VERSION ""

NS_ :

BS_:

BU_: IVI

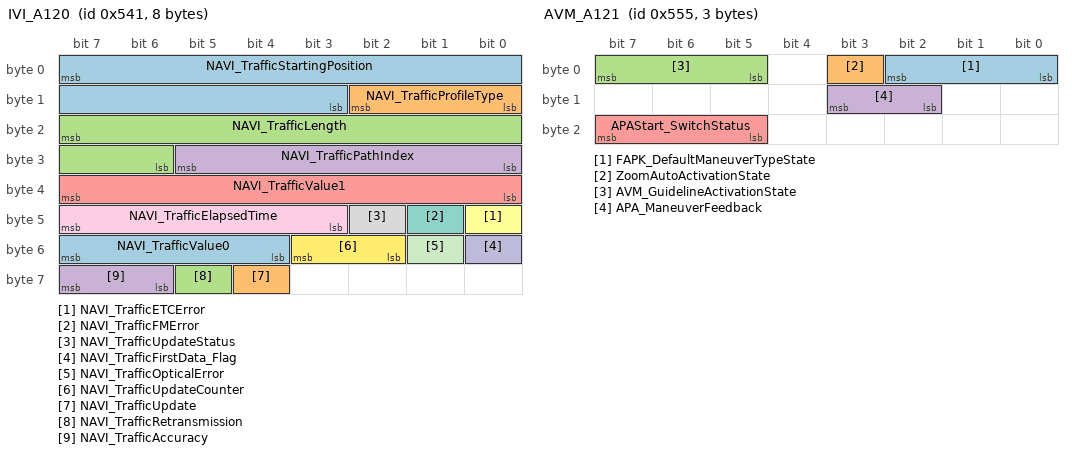
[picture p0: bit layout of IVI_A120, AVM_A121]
BO_ 1345 IVI_A120: 8 IVI
  SG_ NAVI_TrafficStartingPosition : 7|13@0+ (1,0) [0|8190] "m" Vector__XXX
  SG_ NAVI_TrafficProfileType : 10|3@0+ (1,0) [0|0] "" Vector__XXX
  SG_ NAVI_TrafficLength : 23|10@0+ (10,0) [0|7000] "m" Vector__XXX
  SG_ NAVI_TrafficPathIndex : 29|6@0+ (1,1) [1|63] "-" Vector__XXX
  SG_ NAVI_TrafficValue1 : 39|8@0+ (1,0) [0|255] "-" Vector__XXX
  SG_ NAVI_TrafficETCError : 40|1@0+ (1,0) [0|0] "" Vector__XXX
  SG_ NAVI_TrafficFMError : 41|1@0+ (1,0) [0|0] "" Vector__XXX
  SG_ NAVI_TrafficUpdateStatus : 42|1@0+ (1,0) [0|0] "" Vector__XXX
  SG_ NAVI_TrafficElapsedTime : 47|5@0+ (10,0) [0|300] "min" Vector__XXX
  SG_ NAVI_TrafficFirstData_Flag : 48|1@0+ (1,0) [0|0] "" Vector__XXX
  SG_ NAVI_TrafficOpticalError : 49|1@0+ (1,0) [0|0] "" Vector__XXX
  SG_ NAVI_TrafficUpdateCounter : 51|2@0+ (1,0) [0|3] "-" Vector__XXX
  SG_ NAVI_TrafficValue0 : 55|4@0+ (1,0) [0|0] "" Vector__XXX
  SG_ NAVI_TrafficUpdate : 60|1@0+ (1,0) [0|0] "" Vector__XXX
  SG_ NAVI_TrafficRetransmission : 61|1@0+ (1,0) [0|0] "" Vector__XXX
  SG_ NAVI_TrafficAccuracy : 63|2@0+ (1,0) [0|0] "" Vector__XXX

BO_ 1356 ADASISv2_A103: 8 IVI
  SG_ ADASISv2_POSITION : 7|64@0+ (1,0) [0|0] "" Vector__XXX

BO_ 1365 AVM_A121: 3 Vector__XXX
  SG_ FAPK_DefaultManeuverTypeState : 2|3@0+ (1,0) [0|0] "" IVI
  SG_ ZoomAutoActivationState : 3|1@0+ (1,0) [0|0] "" IVI
  SG_ AVM_GuidelineActivationState : 7|3@0+ (1,0) [0|0] "" IVI
  SG_ APA_ManeuverFeedback : 11|2@0+ (1,0) [0|0] "" IVI
  SG_ APAStart_SwitchStatus : 23|3@0+ (1,0) [0|0] "" IVI

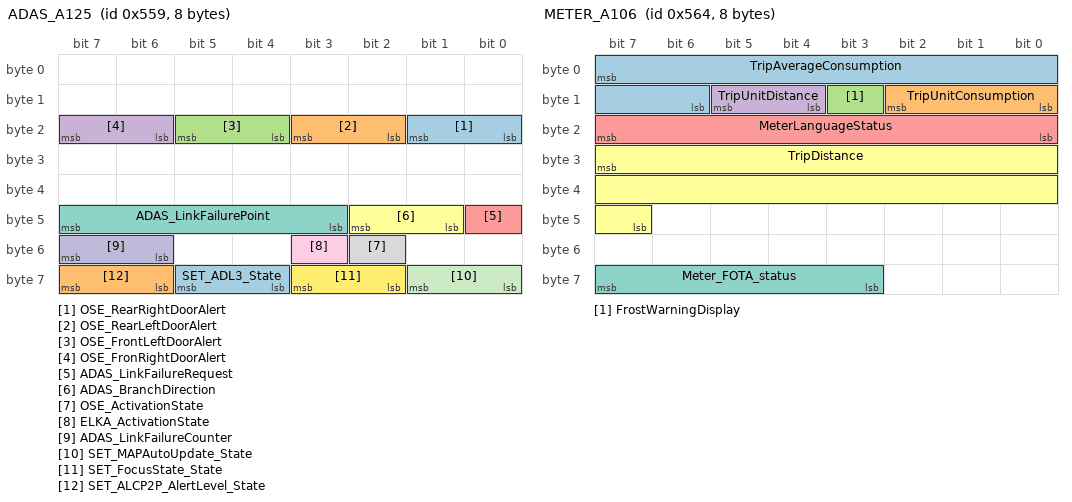
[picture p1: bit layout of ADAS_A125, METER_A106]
BO_ 1369 ADAS_A125: 8 Vector__XXX
  SG_ OSE_RearRightDoorAlert : 17|2@0+ (1,0) [0|0] "" IVI
  SG_ OSE_RearLeftDoorAlert : 19|2@0+ (1,0) [0|0] "" IVI
  SG_ OSE_FrontLeftDoorAlert : 21|2@0+ (1,0) [0|0] "" IVI
  SG_ OSE_FronRightDoorAlert : 23|2@0+ (1,0) [0|0] "" IVI
  SG_ ADAS_LinkFailureRequest : 40|1@0+ (1,0) [0|0] "" IVI
  SG_ ADAS_BranchDirection : 42|2@0+ (1,0) [0|0] "" IVI
  SG_ ADAS_LinkFailurePoint : 47|5@0+ (1,0) [0|30] "-" IVI
  SG_ OSE_ActivationState : 50|1@0+ (1,0) [0|0] "" IVI
  SG_ ELKA_ActivationState : 51|1@0+ (1,0) [0|0] "" IVI
  SG_ ADAS_LinkFailureCounter : 55|2@0+ (1,0) [0|3] "-" IVI
  SG_ SET_MAPAutoUpdate_State : 57|2@0+ (1,0) [0|0] "" IVI
  SG_ SET_FocusState_State : 59|2@0+ (1,0) [0|0] "" IVI
  SG_ SET_ADL3_State : 61|2@0+ (1,0) [0|0] "" IVI
  SG_ SET_ALCP2P_AlertLevel_State : 63|2@0+ (1,0) [0|0] "" IVI

BO_ 1380 METER_A106: 8 Vector__XXX
  SG_ TripAverageConsumption : 7|10@0+ (0.1,0) [0|102.3] "" IVI
  SG_ TripUnitConsumption : 10|3@0+ (1,0) [0|0] "" IVI
  SG_ FrostWarningDisplay : 11|1@0+ (1,0) [0|0] "" IVI
  SG_ TripUnitDistance : 13|2@0+ (1,0) [0|0] "" IVI
  SG_ MeterLanguageStatus : 23|8@0+ (1,0) [0|0] "" IVI
  SG_ TripDistance : 31|17@0+ (0.1,0) [0|13107.1] "" IVI
  SG_ Meter_FOTA_status : 63|5@0+ (1,0) [0|0] "" IVI

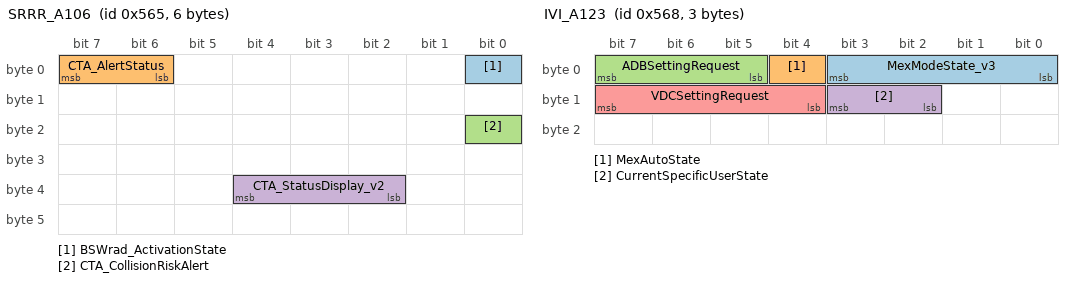
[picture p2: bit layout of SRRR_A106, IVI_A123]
BO_ 1381 SRRR_A106: 6 Vector__XXX
  SG_ BSWrad_ActivationState : 0|1@0+ (1,0) [0|0] "" IVI
  SG_ CTA_AlertStatus : 7|2@0+ (1,0) [0|0] "" IVI
  SG_ CTA_CollisionRiskAlert : 16|1@0+ (1,0) [0|0] "" IVI
  SG_ CTA_StatusDisplay_v2 : 36|3@0+ (1,0) [0|0] "" IVI

BO_ 1384 IVI_A123: 3 IVI
  SG_ MexModeState_v3 : 3|4@0+ (1,0) [0|0] "" Vector__XXX
  SG_ MexAutoState : 4|1@0+ (1,0) [0|0] "" Vector__XXX
  SG_ ADBSettingRequest : 7|3@0+ (1,0) [0|0] "" Vector__XXX
  SG_ CurrentSpecificUserState : 11|2@0+ (1,0) [0|0] "" Vector__XXX
  SG_ VDCSettingRequest : 15|4@0+ (1,0) [0|0] "" Vector__XXX

BO_ 1386 HVAC_A101: 5 Vector__XXX
  SG_ ClimCabinParticleConcDisplay : 15|10@0+ (5,0) [0|4095] "µg/m3" IVI
  SG_ ClimExternParticleConcDisplay : 21|10@0+ (5,0) [0|4095] "µg/m3" IVI

BO_ 1392 IVI_A119: 8 IVI
  SG_ HUD_ADASactivationRequest2 : 1|2@0+ (1,0) [0|0] "" Vector__XXX
  SG_ VSPsoundChoiceActivationRequest2 : 4|3@0+ (1,0) [0|0] "" Vector__XXX
  SG_ FAPK_DefaultManeuverTypeRequest2 : 7|3@0+ (1,0) [0|0] "" Vector__XXX
  SG_ AmbientLightingColor_v3 : 8|7@0+ (1,0) [0|0] "" Vector__XXX
  SG_ FOTA_ReadyToSleep_IVI : 9|1@0+ (1,0) [0|0] "" Vector__XXX
  SG_ VSPSoundActivationRequest2 : 11|2@0+ (1,0) [0|0] "" Vector__XXX
  SG_ HUD_TurnByTurnActivationRequest2 : 13|2@0+ (1,0) [0|0] "" Vector__XXX
  SG_ HUD_TSRactivationRequest2 : 15|2@0+ (1,0) [0|0] "" Vector__XXX
  SG_ SET_Acceleration_Request2 : 17|3@0+ (1,0) [0|0] "" Vector__XXX
  SG_ SET_NavigatDriveAssist_Request2 : 25|2@0+ (1,0) [0|0] "" Vector__XXX
  SG_ SET_ALCActivationByTSIG_Request2 : 27|2@0+ (1,0) [0|0] "" Vector__XXX
  SG_ SET_Deceleration_Request2 : 30|3@0+ (1,0) [0|0] "" Vector__XXX
  SG_ SET_OvertakingAssist_Request2 : 33|2@0+ (1,0) [0|0] "" Vector__XXX
  SG_ SET_LaneChangeSwiftness_Request2 : 36|3@0+ (1,0) [0|0] "" Vector__XXX
  SG_ SET_CornerSpeedLevel_Request2 : 39|3@0+ (1,0) [0|0] "" Vector__XXX
  SG_ SET_VoiceGuidance_Request2 : 41|2@0+ (1,0) [0|0] "" Vector__XXX
  SG_ SET_PositionInLane_Request2 : 44|3@0+ (1,0) [0|0] "" Vector__XXX
  SG_ SET_OvertakeRelatSpeed_Request2 : 47|3@0+ (1,0) [0|0] "" Vector__XXX
  SG_ IVI_SafeModeAck : 48|1@0+ (1,0) [0|0] "" Vector__XXX
  SG_ WDA_ActivationRequest2 : 50|2@0+ (1,0) [0|0] "" Vector__XXX
  SG_ RAB_ActivationRequest2 : 52|2@0+ (1,0) [0|0] "" Vector__XXX
  SG_ RST_PedalMappingRequest : 55|3@0+ (1,0) [0|0] "" Vector__XXX
  SG_ VirtualKeySuspendReq2 : 57|2@0+ (1,0) [0|0] "" Vector__XXX
  SG_ SET_MAPAutoUpdate_Request2 : 59|2@0+ (1,0) [0|0] "" Vector__XXX
  SG_ SET_FocusState_Request2 : 61|2@0+ (1,0) [0|0] "" Vector__XXX
  SG_ SET_ADL3_Request2 : 63|2@0+ (1,0) [0|0] "" Vector__XXX

BO_ 1394 ADASIS_CASP_A101: 8 IVI
  SG_ E_Hor_MedRange_CartoData : 4|61@0+ (1,0) [0|0] "" Vector__XXX
  SG_ E_Hor_MedRange_DataType : 7|3@0+ (1,0) [0|0] "" Vector__XXX

BO_ 1398 HEVC_A155: 3 Vector__XXX
  SG_ ChargingStationComType : 11|3@0+ (1,0) [0|0] "" IVI
  SG_ V2G_ServiceActivationState : 23|3@0+ (1,0) [0|0] "" IVI

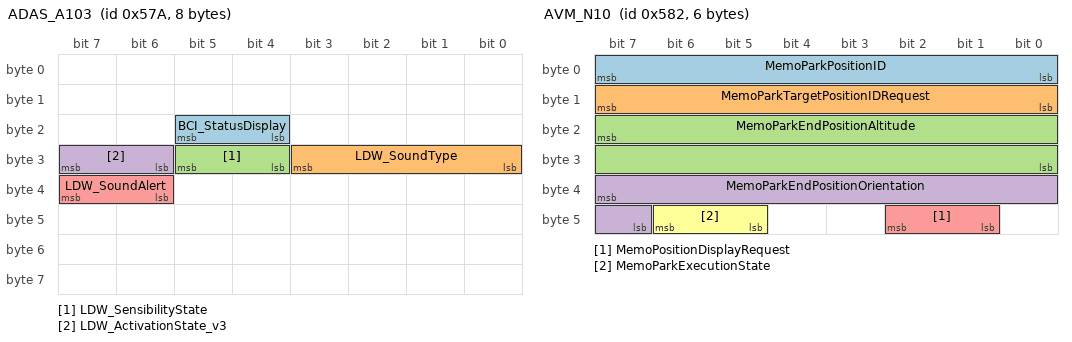
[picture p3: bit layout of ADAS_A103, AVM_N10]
BO_ 1402 ADAS_A103: 8 Vector__XXX
  SG_ BCI_StatusDisplay : 21|2@0+ (1,0) [0|0] "" IVI
  SG_ LDW_SoundType : 27|4@0+ (1,0) [0|0] "" IVI
  SG_ LDW_SensibilityState : 29|2@0+ (1,0) [0|0] "" IVI
  SG_ LDW_ActivationState_v3 : 31|2@0+ (1,0) [0|0] "" IVI
  SG_ LDW_SoundAlert : 39|2@0+ (1,0) [0|0] "" IVI

BO_ 1410 AVM_N10: 6 Vector__XXX
  SG_ MemoParkPositionID : 7|8@0+ (1,0) [0|250] "" IVI
  SG_ MemoParkTargetPositionIDRequest : 15|8@0+ (1,0) [0|250] "" IVI
  SG_ MemoParkEndPositionAltitude : 23|16@0+ (0.1,-500) [-500|3000] "m" IVI
  SG_ MemoParkEndPositionOrientation : 39|9@0+ (1,-180) [-180|179] "°" IVI
  SG_ MemoPositionDisplayRequest : 42|2@0+ (1,0) [0|0] "" IVI
  SG_ MemoParkExecutionState : 46|2@0+ (1,0) [0|0] "" IVI

BO_ 1412 HVAC_A108: 3 Vector__XXX
  SG_ HVAC_ClimShortcutPush : 5|1@0+ (1,0) [0|0] "" IVI

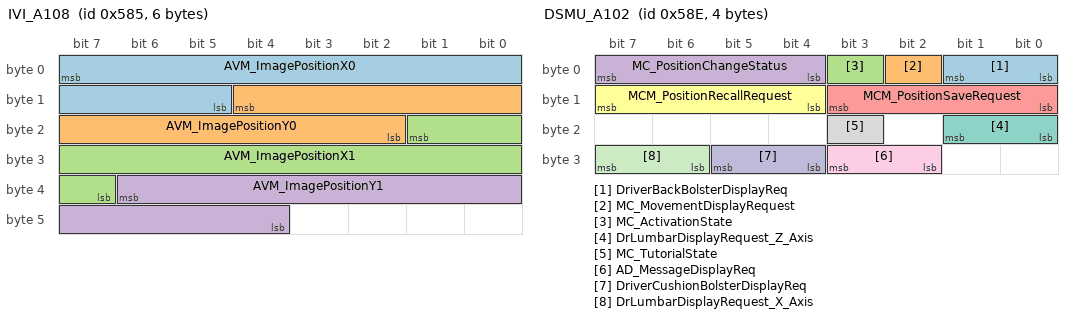
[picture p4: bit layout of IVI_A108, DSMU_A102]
BO_ 1413 IVI_A108: 6 IVI
  SG_ AVM_ImagePositionX0 : 7|11@0+ (1,0) [0|2045] "pixel" Vector__XXX
  SG_ AVM_ImagePositionY0 : 12|11@0+ (1,0) [0|2045] "pixel" Vector__XXX
  SG_ AVM_ImagePositionX1 : 17|11@0+ (1,0) [0|2045] "pixel" Vector__XXX
  SG_ AVM_ImagePositionY1 : 38|11@0+ (1,0) [0|2045] "pixel" Vector__XXX

BO_ 1415 IVI_R101: 1 IVI
  SG_ FAPK_SelectedManeuverTypeRequest : 6|3@0+ (1,0) [0|0] "" Vector__XXX

BO_ 1422 DSMU_A102: 4 Vector__XXX
  SG_ DriverBackBolsterDisplayReq : 1|2@0+ (1,0) [0|0] "" IVI
  SG_ MC_MovementDisplayRequest : 2|1@0+ (1,0) [0|0] "" IVI
  SG_ MC_ActivationState : 3|1@0+ (1,0) [0|0] "" IVI
  SG_ MC_PositionChangeStatus : 7|4@0+ (1,0) [0|0] "" IVI
  SG_ MCM_PositionSaveRequest : 11|4@0+ (1,0) [0|0] "" IVI
  SG_ MCM_PositionRecallRequest : 15|4@0+ (1,0) [0|0] "" IVI
  SG_ DrLumbarDisplayRequest_Z_Axis : 17|2@0+ (1,0) [0|0] "" IVI
  SG_ MC_TutorialState : 19|1@0+ (1,0) [0|0] "" IVI
  SG_ AD_MessageDisplayReq : 27|2@0+ (1,0) [0|0] "" IVI
  SG_ DriverCushionBolsterDisplayReq : 29|2@0+ (1,0) [0|0] "" IVI
  SG_ DrLumbarDisplayRequest_X_Axis : 31|2@0+ (1,0) [0|0] "" IVI

BO_ 1424 AVM_N11: 8 Vector__XXX
  SG_ MemoParkEndPositionLongitude : 7|29@0+ (0.00010,-18000) [-18000.0000|17959.9999] "min" IVI
  SG_ MemoParkEndPositionLatitude : 26|28@0+ (0.00010,-9000) [-9000.0000|8959.9999] "min" IVI

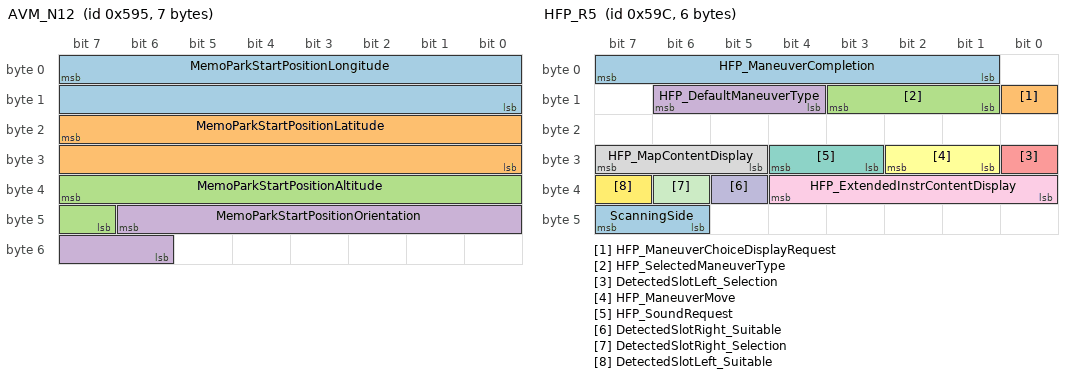
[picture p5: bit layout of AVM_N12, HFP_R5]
BO_ 1429 AVM_N12: 7 Vector__XXX
  SG_ MemoParkStartPositionLongitude : 7|16@0+ (0.00010,-0.2) [-0.2|0.2] "min" IVI
  SG_ MemoParkStartPositionLatitude : 23|16@0+ (0.00010,-0.2) [-0.2|0.2] "min" IVI
  SG_ MemoParkStartPositionAltitude : 39|9@0+ (0.1,-25.5) [-25.5|25.5] "m" IVI
  SG_ MemoParkStartPositionOrientation : 46|9@0+ (1,-180) [-180|179] "°" IVI

BO_ 1436 HFP_R5: 6 Vector__XXX
  SG_ HFP_ManeuverCompletion : 7|7@0+ (1,0) [0|100] "%" IVI
  SG_ HFP_ManeuverChoiceDisplayRequest : 8|1@0+ (1,0) [0|0] "" IVI
  SG_ HFP_SelectedManeuverType : 11|3@0+ (1,0) [0|0] "" IVI
  SG_ HFP_DefaultManeuverType : 14|3@0+ (1,0) [0|0] "" IVI
  SG_ DetectedSlotLeft_Selection : 24|1@0+ (1,0) [0|0] "" IVI
  SG_ HFP_ManeuverMove : 26|2@0+ (1,0) [0|0] "" IVI
  SG_ HFP_SoundRequest : 28|2@0+ (1,0) [0|0] "" IVI
  SG_ HFP_MapContentDisplay : 31|3@0+ (1,0) [0|0] "" IVI
  SG_ HFP_ExtendedInstrContentDisplay : 36|5@0+ (1,0) [0|0] "" IVI
  SG_ DetectedSlotRight_Suitable : 37|1@0+ (1,0) [0|0] "" IVI
  SG_ DetectedSlotRight_Selection : 38|1@0+ (1,0) [0|0] "" IVI
  SG_ DetectedSlotLeft_Suitable : 39|1@0+ (1,0) [0|0] "" IVI
  SG_ ScanningSide : 47|2@0+ (1,0) [0|0] "" IVI

BO_ 1439 HEVC_A133: 4 Vector__XXX
  SG_ InstantPowerZEVdisplay : 7|14@0+ (0.1,-500) [-500|500] "kW" IVI
  SG_ InstantConsumptionZEVdisplay_v3 : 23|11@0+ (0.1,-102.2) [-102.2|102.2] "" IVI

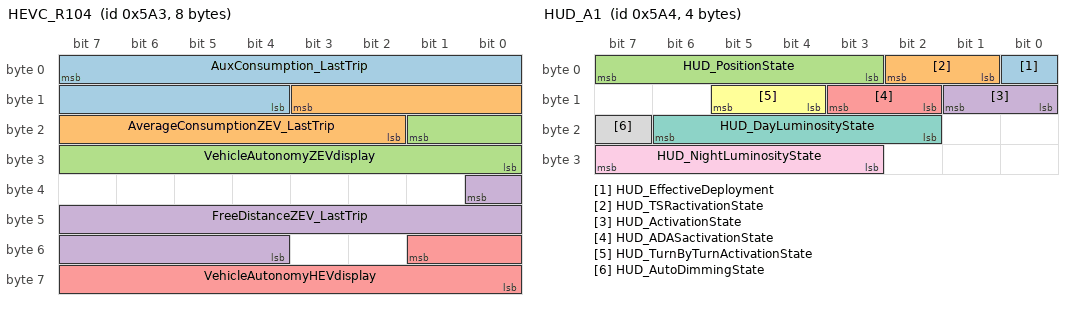
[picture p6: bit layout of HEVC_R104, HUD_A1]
BO_ 1443 HEVC_R104: 8 Vector__XXX
  SG_ AuxConsumption_LastTrip : 7|12@0+ (0.1,0) [0|409.4] "kWh" IVI
  SG_ AverageConsumptionZEV_LastTrip : 11|10@0+ (0.1,0) [0|102.2] "" IVI
  SG_ VehicleAutonomyZEVdisplay : 17|10@0+ (1,0) [0|1022] "km" IVI
  SG_ FreeDistanceZEV_LastTrip : 32|13@0+ (0.1,0) [0|819] "" IVI
  SG_ VehicleAutonomyHEVdisplay : 49|10@0+ (1,0) [0|1022] "" IVI

BO_ 1444 HUD_A1: 4 Vector__XXX
  SG_ HUD_EffectiveDeployment : 0|1@0+ (1,0) [0|0] "" IVI
  SG_ HUD_TSRactivationState : 2|2@0+ (1,0) [0|0] "" IVI
  SG_ HUD_PositionState : 7|5@0+ (1,0) [0|0] "" IVI
  SG_ HUD_ActivationState : 9|2@0+ (1,0) [0|0] "" IVI
  SG_ HUD_ADASactivationState : 11|2@0+ (1,0) [0|0] "" IVI
  SG_ HUD_TurnByTurnActivationState : 13|2@0+ (1,0) [0|0] "" IVI
  SG_ HUD_DayLuminosityState : 22|5@0+ (1,0) [0|0] "" IVI
  SG_ HUD_AutoDimmingState : 23|1@0+ (1,0) [0|0] "" IVI
  SG_ HUD_NightLuminosityState : 31|5@0+ (1,0) [0|0] "" IVI

BO_ 1446 SR_CANHS_R_02: 1 Vector__XXX
  SG_ StorageFormatStatus : 5|2@0+ (1,0) [0|0] "" IVI

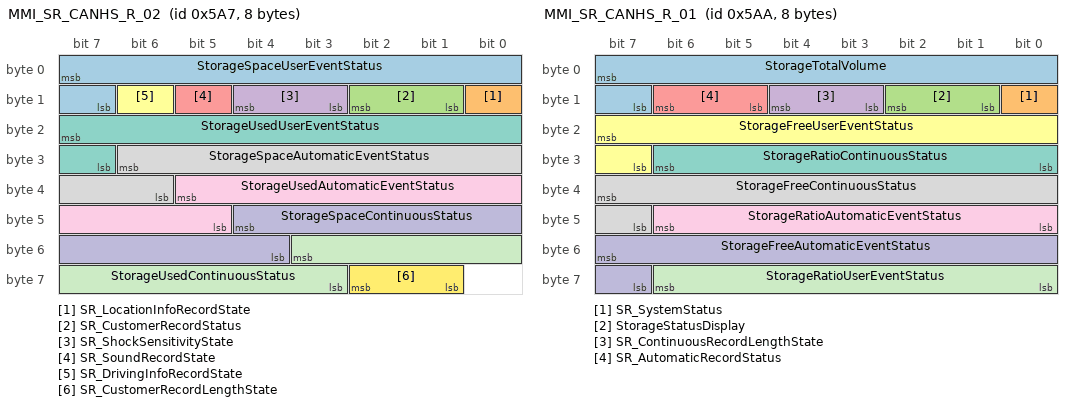
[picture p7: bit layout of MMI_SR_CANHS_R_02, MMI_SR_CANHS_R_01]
BO_ 1447 MMI_SR_CANHS_R_02: 8 Vector__XXX
  SG_ StorageSpaceUserEventStatus : 7|9@0+ (0.1,0) [0|32] "GB" IVI
  SG_ SR_LocationInfoRecordState : 8|1@0+ (1,0) [0|0] "" IVI
  SG_ SR_CustomerRecordStatus : 10|2@0+ (1,0) [0|0] "" IVI
  SG_ SR_ShockSensitivityState : 12|2@0+ (1,0) [0|0] "" IVI
  SG_ SR_SoundRecordState : 13|1@0+ (1,0) [0|0] "" IVI
  SG_ SR_DrivingInfoRecordState : 14|1@0+ (1,0) [0|0] "" IVI
  SG_ StorageUsedUserEventStatus : 23|9@0+ (0.1,0) [0|32] "GB" IVI
  SG_ StorageSpaceAutomaticEventStatus : 30|9@0+ (0.1,0) [0|32] "GB" IVI
  SG_ StorageUsedAutomaticEventStatus : 37|9@0+ (0.1,0) [0|32] "GB" IVI
  SG_ StorageSpaceContinuousStatus : 44|9@0+ (0.1,0) [0|32] "GB" IVI
  SG_ StorageUsedContinuousStatus : 51|9@0+ (0.1,0) [0|32] "GB" IVI
  SG_ SR_CustomerRecordLengthState : 58|2@0+ (1,0) [0|0] "" IVI

BO_ 1448 IVI_N20: 8 IVI
  SG_ ParkEndPositionLongitude : 7|29@0+ (0.00010,-18000) [-18000|17959.9999] "min" Vector__XXX
  SG_ ParkEndPositionLatitude : 26|28@0+ (0.00010,-9000) [-9000|8959.9999] "min" Vector__XXX

BO_ 1449 IVI_A109: 7 IVI
  SG_ ClimFrontDefrostPush : 0|1@0+ (1,0) [0|1] "-" Vector__XXX
  SG_ ClimRearDefrostPush : 1|1@0+ (1,0) [0|1] "-" Vector__XXX
  SG_ SecondRowLeftSeatAutoPush : 2|1@0+ (1,0) [0|1] "-" Vector__XXX
  SG_ SecondRowRightSeatAutoPush : 3|1@0+ (1,0) [0|1] "-" Vector__XXX
  SG_ ThirdRowLeftSeatAutoPush : 4|1@0+ (1,0) [0|1] "-" Vector__XXX
  SG_ ThirdRowRightSeatAutoPush : 5|1@0+ (1,0) [0|1] "-" Vector__XXX
  SG_ ClimHeatedSteeringWheelPush : 6|1@0+ (1,0) [0|1] "-" Vector__XXX
  SG_ ClimHeatedSteeringWheelAutoPush : 7|1@0+ (1,0) [0|1] "-" Vector__XXX
  SG_ ClimRearLeftTempRequest : 15|9@0+ (0.5,10) [10|127.5] "°" Vector__XXX
  SG_ ClimRearRightTempRequest : 22|9@0+ (0.5,10) [10|127.5] "°" Vector__XXX
  SG_ ClimRearRightFlowDistrVentPush : 24|1@0+ (1,0) [0|1] "" Vector__XXX
  SG_ ClimRearLeftFlowDistrVentPush : 25|1@0+ (1,0) [0|1] "" Vector__XXX
  SG_ ClimRearRightFlowDistrDefPush : 26|1@0+ (1,0) [0|1] "" Vector__XXX
  SG_ ClimRearLeftFlowDistrDefPush : 27|1@0+ (1,0) [0|1] "" Vector__XXX
  SG_ ClimRearRightSyncPush : 28|1@0+ (1,0) [0|1] "" Vector__XXX
  SG_ ClimRearLeftSyncPush : 29|1@0+ (1,0) [0|1] "" Vector__XXX
  SG_ ClimLinkPriorityHeatStrgAutoReq : 34|3@0+ (1,0) [0|0] "" Vector__XXX
  SG_ ClimRearRightAutoNormalPush : 35|1@0+ (1,0) [0|1] "" Vector__XXX
  SG_ ClimRearLeftAutoNormalPush : 36|1@0+ (1,0) [0|1] "" Vector__XXX
  SG_ ClimRearACPush : 37|1@0+ (1,0) [0|1] "" Vector__XXX
  SG_ ClimRearRightFlowDistrFeetPush : 38|1@0+ (1,0) [0|1] "" Vector__XXX
  SG_ ClimRearLeftFlowDistrFeetPush : 39|1@0+ (1,0) [0|1] "" Vector__XXX
  SG_ ClimFPrearLeftBlowingRequest : 43|4@0+ (1,0) [0|0] "" Vector__XXX
  SG_ ClimFPrearRightBlowingRequest : 47|4@0+ (1,0) [0|0] "" Vector__XXX
  SG_ ClimACmaxPush : 51|1@0+ (1,0) [0|1] "-" Vector__XXX
  SG_ VisionMexMode : 55|4@0+ (1,0) [0|0] "" Vector__XXX

BO_ 1450 MMI_SR_CANHS_R_01: 8 Vector__XXX
  SG_ StorageTotalVolume : 7|9@0+ (0.1,0) [0|32] "GB" IVI
  SG_ SR_SystemStatus : 8|1@0+ (1,0) [0|0] "" IVI
  SG_ StorageStatusDisplay : 10|2@0+ (1,0) [0|0] "" IVI
  SG_ SR_ContinuousRecordLengthState : 12|2@0+ (1,0) [0|0] "" IVI
  SG_ SR_AutomaticRecordStatus : 14|2@0+ (1,0) [0|0] "" IVI
  SG_ StorageFreeUserEventStatus : 23|9@0+ (0.1,0) [0|32] "GB" IVI
  SG_ StorageRatioContinuousStatus : 30|7@0+ (1,0) [0|100] "%" IVI
  SG_ StorageFreeContinuousStatus : 39|9@0+ (0.1,0) [0|32] "GB" IVI
  SG_ StorageRatioAutomaticEventStatus : 46|7@0+ (1,0) [0|100] "%" IVI
  SG_ StorageFreeAutomaticEventStatus : 55|9@0+ (0.1,0) [0|32] "GB" IVI
  SG_ StorageRatioUserEventStatus : 62|7@0+ (1,0) [0|100] "%" IVI

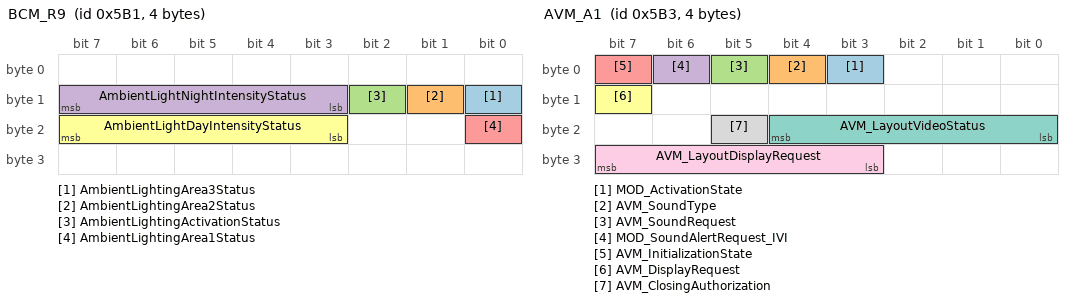
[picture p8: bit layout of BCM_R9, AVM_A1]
BO_ 1457 BCM_R9: 4 Vector__XXX
  SG_ AmbientLightingArea3Status : 8|1@0+ (1,0) [0|0] "" IVI
  SG_ AmbientLightingArea2Status : 9|1@0+ (1,0) [0|0] "" IVI
  SG_ AmbientLightingActivationStatus : 10|1@0+ (1,0) [0|0] "" IVI
  SG_ AmbientLightNightIntensityStatus : 15|5@0+ (5,0) [0|100] "%" IVI
  SG_ AmbientLightingArea1Status : 16|1@0+ (1,0) [0|0] "" IVI
  SG_ AmbientLightDayIntensityStatus : 23|5@0+ (5,0) [0|100] "%" IVI

BO_ 1458 HEVC_R112: 7 Vector__XXX
  SG_ PnCHEVCactivationStatus : 31|2@0+ (1,0) [0|0] "" IVI

BO_ 1459 AVM_A1: 4 Vector__XXX
  SG_ MOD_ActivationState : 3|1@0+ (1,0) [0|0] "" IVI
  SG_ AVM_SoundType : 4|1@0+ (1,0) [0|0] "" IVI
  SG_ AVM_SoundRequest : 5|1@0+ (1,0) [0|0] "" IVI
  SG_ MOD_SoundAlertRequest_IVI : 6|1@0+ (1,0) [0|0] "" IVI
  SG_ AVM_InitializationState : 7|1@0+ (1,0) [0|0] "" IVI
  SG_ AVM_DisplayRequest : 15|1@0+ (1,0) [0|0] "" IVI
  SG_ AVM_LayoutVideoStatus : 20|5@0+ (1,0) [0|0] "" IVI
  SG_ AVM_ClosingAuthorization : 21|1@0+ (1,0) [0|0] "" IVI
  SG_ AVM_LayoutDisplayRequest : 31|5@0+ (1,0) [0|0] "" IVI

BO_ 1462 HVAC_A105: 8 Vector__XXX
  SG_ ClimRearLeftTempDisplay : 7|9@0+ (0.5,0) [10|127.5] "°" IVI
  SG_ ClimFrontDefrostDisplayStatus : 8|1@0+ (1,0) [0|0] "" IVI
  SG_ ClimHeatedSteerWheelDispStatus : 9|1@0+ (1,0) [0|0] "" IVI
  SG_ ClimRearLeftTempDisplayStatus : 10|1@0+ (1,0) [0|0] "" IVI
  SG_ ClimHeatedSteerWheelAutoDisplay : 12|2@0+ (1,0) [0|0] "" IVI
  SG_ ClimFrontDefrostDisplay : 14|2@0+ (1,0) [0|0] "" IVI
  SG_ ClimRearRightTempDisplay : 23|9@0+ (0.5,0) [10|127.5] "°" IVI
  SG_ ClimRearRightSyncDisplayStatus : 24|1@0+ (1,0) [0|0] "" IVI
  SG_ ClimRearRightSyncDisplay : 26|2@0+ (1,0) [0|0] "" IVI
  SG_ ClimRearLeftSyncDisplayStatus : 27|1@0+ (1,0) [0|0] "" IVI
  SG_ ClimRearLeftSyncDisplay : 29|2@0+ (1,0) [0|0] "" IVI
  SG_ ClimRearRightTempDisplayStatus : 30|1@0+ (1,0) [0|0] "" IVI
  SG_ ClimRearRightFlowDistDispStatus : 32|1@0+ (1,0) [0|0] "" IVI
  SG_ ClimRearRightFlowDistrDisplay : 35|3@0+ (1,0) [0|0] "" IVI
  SG_ ClimRearLeftFlowDistrDispStatus : 36|1@0+ (1,0) [0|0] "" IVI
  SG_ ClimRearLeftFlowDistrDisplay : 39|3@0+ (1,0) [0|0] "" IVI
  SG_ ClimRearLeftBlowingAutoDisplay : 41|2@0+ (1,0) [0|0] "" IVI
  SG_ ClimRearRightBlowingAutoDisplay : 43|2@0+ (1,0) [0|0] "" IVI
  SG_ ClimRearRightBlowLevelDisplay : 47|4@0+ (1,0) [0|0] "" IVI
  SG_ ClimRearACDisplay : 49|2@0+ (1,0) [0|0] "" IVI
  SG_ ClimRearRightBlowLevlDispStatus : 50|1@0+ (1,0) [0|0] "" IVI
  SG_ ClimRearLeftBlowLevelDispStatus : 51|1@0+ (1,0) [0|0] "" IVI
  SG_ ClimRearLeftBlowLevelDisplay : 55|4@0+ (1,0) [0|0] "" IVI
  SG_ ClimLinkPrioritHeatStrgAutoDisp : 58|3@0+ (1,0) [0|0] "" IVI
  SG_ ClimRearRightAutoDisplay : 60|2@0+ (1,0) [0|0] "" IVI
  SG_ ClimRearLeftAutoDisplay : 62|2@0+ (1,0) [0|0] "" IVI
  SG_ ClimRearACDisplayStatus : 63|1@0+ (1,0) [0|0] "" IVI

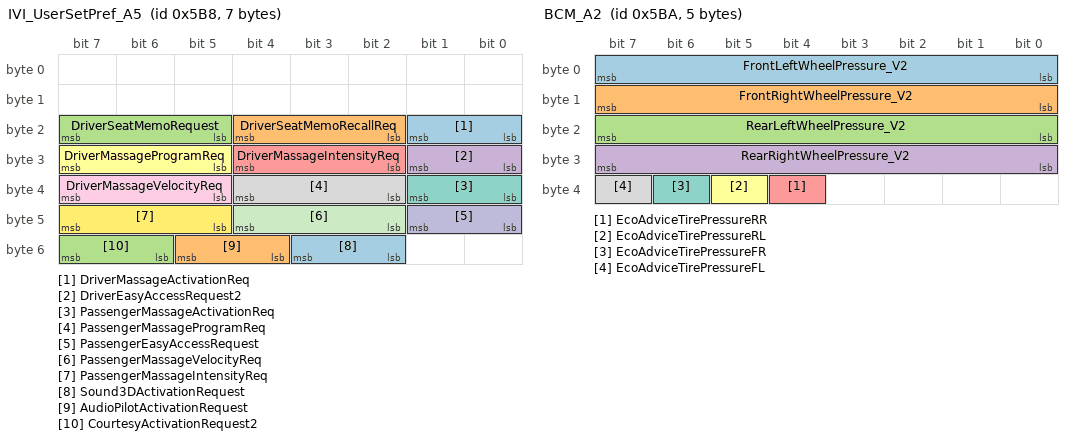
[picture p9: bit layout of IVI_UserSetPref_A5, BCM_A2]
BO_ 1464 IVI_UserSetPref_A5: 7 IVI
  SG_ DriverMassageActivationReq : 17|2@0+ (1,0) [0|0] "" Vector__XXX
  SG_ DriverSeatMemoRecallReq : 20|3@0+ (1,0) [0|0] "" Vector__XXX
  SG_ DriverSeatMemoRequest : 23|3@0+ (1,0) [0|0] "" Vector__XXX
  SG_ DriverEasyAccessRequest2 : 25|2@0+ (1,0) [0|0] "" Vector__XXX
  SG_ DriverMassageIntensityReq : 28|3@0+ (1,0) [0|0] "" Vector__XXX
  SG_ DriverMassageProgramReq : 31|3@0+ (1,0) [0|0] "" Vector__XXX
  SG_ PassengerMassageActivationReq : 33|2@0+ (1,0) [0|0] "" Vector__XXX
  SG_ PassengerMassageProgramReq : 36|3@0+ (1,0) [0|0] "" Vector__XXX
  SG_ DriverMassageVelocityReq : 39|3@0+ (1,0) [0|0] "" Vector__XXX
  SG_ PassengerEasyAccessRequest : 41|2@0+ (1,0) [0|0] "" Vector__XXX
  SG_ PassengerMassageVelocityReq : 44|3@0+ (1,0) [0|0] "" Vector__XXX
  SG_ PassengerMassageIntensityReq : 47|3@0+ (1,0) [0|0] "" Vector__XXX
  SG_ Sound3DActivationRequest : 51|2@0+ (1,0) [0|0] "" Vector__XXX
  SG_ AudioPilotActivationRequest : 53|2@0+ (1,0) [0|0] "" Vector__XXX
  SG_ CourtesyActivationRequest2 : 55|2@0+ (1,0) [0|0] "" Vector__XXX

BO_ 1465 IVI_A110: 8 IVI
  SG_ PreSoakHVACfunctionsRequest : 0|2@0+ (1,0) [0|0] "" Vector__XXX
  SG_ PreSoakTempValue_MMI_v2 : 7|7@0+ (0.5,16) [16|32] "°C" Vector__XXX
  SG_ PreSoakFRseatRequest : 10|3@0+ (1,0) [0|0] "" Vector__XXX
  SG_ PreSoakFLseatRequest : 13|3@0+ (1,0) [0|0] "" Vector__XXX
  SG_ PreSoakSecondRLseatRequest : 18|3@0+ (1,0) [0|0] "" Vector__XXX
  SG_ PreSoakSecondRRseatRequest : 21|3@0+ (1,0) [0|0] "" Vector__XXX
  SG_ PreSoak_eACmodeRequest : 23|2@0+ (1,0) [0|0] "" Vector__XXX
  SG_ PreSoakThirdRLseatRequest : 26|3@0+ (1,0) [0|0] "" Vector__XXX
  SG_ PreSoakBatteryHeatingRequest : 28|2@0+ (1,0) [0|0] "" Vector__XXX
  SG_ PreSoakSecondRCseatRequest : 31|3@0+ (1,0) [0|0] "" Vector__XXX
  SG_ LivingLightModeRequest : 32|1@0+ (1,0) [0|0] "" Vector__XXX
  SG_ PreSoakAirPurifierRequest : 34|2@0+ (1,0) [0|0] "" Vector__XXX
  SG_ PreSoakFrontDefrostRequest : 36|2@0+ (1,0) [0|0] "" Vector__XXX
  SG_ PreSoakThirdRRseatRequest : 39|3@0+ (1,0) [0|0] "" Vector__XXX
  SG_ SecondRowCentralSeatRequest : 43|4@0+ (1,0) [0|0] "" Vector__XXX
  SG_ PreSoakRearDefrostRequest : 45|2@0+ (1,0) [0|0] "" Vector__XXX
  SG_ PreSoakHeatedStrgWheelRequest : 47|2@0+ (1,0) [0|0] "" Vector__XXX
  SG_ FrontRightSeatRequest : 51|4@0+ (1,0) [0|0] "" Vector__XXX
  SG_ FrontLeftSeatRequest : 55|4@0+ (1,0) [0|0] "" Vector__XXX
  SG_ Dccharge_NextStationTimeArrival : 63|7@0+ (1,0) [0|120] "min" Vector__XXX

BO_ 1466 BCM_A2: 5 Vector__XXX
  SG_ FrontLeftWheelPressure_V2 : 7|8@0+ (30,0) [0|7620] "mbar" IVI
  SG_ FrontRightWheelPressure_V2 : 15|8@0+ (30,0) [0|7620] "mbar" IVI
  SG_ RearLeftWheelPressure_V2 : 23|8@0+ (30,0) [0|7620] "mbar" IVI
  SG_ RearRightWheelPressure_V2 : 31|8@0+ (30,0) [0|7620] "mbar" IVI
  SG_ EcoAdviceTirePressureRR : 36|1@0+ (1,0) [0|0] "" IVI
  SG_ EcoAdviceTirePressureRL : 37|1@0+ (1,0) [0|0] "" IVI
  SG_ EcoAdviceTirePressureFR : 38|1@0+ (1,0) [0|0] "" IVI
  SG_ EcoAdviceTirePressureFL : 39|1@0+ (1,0) [0|0] "" IVI

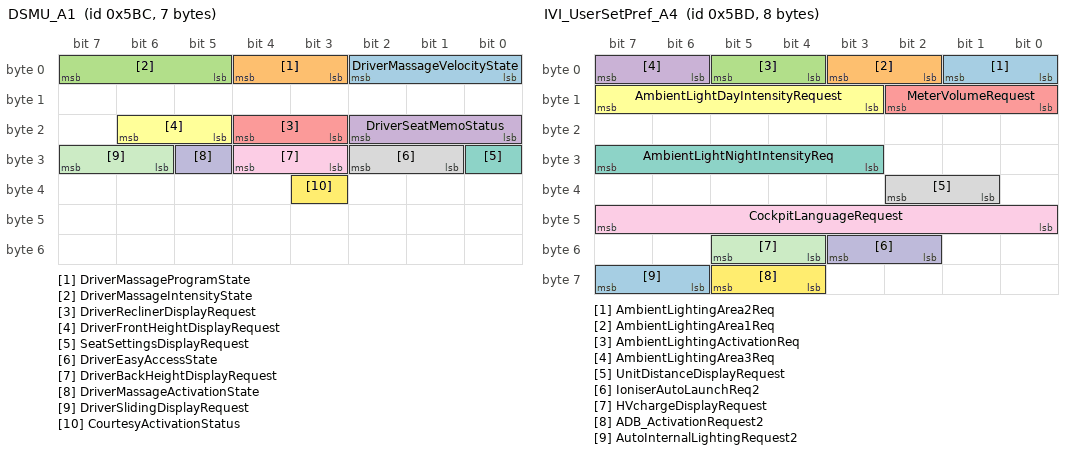
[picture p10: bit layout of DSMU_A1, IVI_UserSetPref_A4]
BO_ 1468 DSMU_A1: 7 Vector__XXX
  SG_ DriverMassageVelocityState : 2|3@0+ (1,0) [0|0] "" IVI
  SG_ DriverMassageProgramState : 4|2@0+ (1,0) [0|0] "" IVI
  SG_ DriverMassageIntensityState : 7|3@0+ (1,0) [0|0] "" IVI
  SG_ DriverSeatMemoStatus : 18|3@0+ (1,0) [0|0] "" IVI
  SG_ DriverReclinerDisplayRequest : 20|2@0+ (1,0) [0|0] "" IVI
  SG_ DriverFrontHeightDisplayRequest : 22|2@0+ (1,0) [0|0] "" IVI
  SG_ SeatSettingsDisplayRequest : 24|1@0+ (1,0) [0|0] "" IVI
  SG_ DriverEasyAccessState : 26|2@0+ (1,0) [0|0] "" IVI
  SG_ DriverBackHeightDisplayRequest : 28|2@0+ (1,0) [0|0] "" IVI
  SG_ DriverMassageActivationState : 29|1@0+ (1,0) [0|0] "" IVI
  SG_ DriverSlidingDisplayRequest : 31|2@0+ (1,0) [0|0] "" IVI
  SG_ CourtesyActivationStatus : 35|1@0+ (1,0) [0|0] "" IVI

BO_ 1469 IVI_UserSetPref_A4: 8 IVI
  SG_ AmbientLightingArea2Req : 1|2@0+ (1,0) [0|0] "" Vector__XXX
  SG_ AmbientLightingArea1Req : 3|2@0+ (1,0) [0|0] "" Vector__XXX
  SG_ AmbientLightingActivationReq : 5|2@0+ (1,0) [0|0] "" Vector__XXX
  SG_ AmbientLightingArea3Req : 7|2@0+ (1,0) [0|0] "" Vector__XXX
  SG_ MeterVolumeRequest : 10|3@0+ (1,0) [0|0] "" Vector__XXX
  SG_ AmbientLightDayIntensityRequest : 15|5@0+ (5,0) [0|100] "%" Vector__XXX
  SG_ AmbientLightNightIntensityReq : 31|5@0+ (5,0) [0|100] "%" Vector__XXX
  SG_ UnitDistanceDisplayRequest : 34|2@0+ (1,0) [0|0] "" Vector__XXX
  SG_ CockpitLanguageRequest : 47|8@0+ (1,0) [0|0] "" Vector__XXX
  SG_ IoniserAutoLaunchReq2 : 51|2@0+ (1,0) [0|0] "" Vector__XXX
  SG_ HVchargeDisplayRequest : 53|2@0+ (1,0) [0|0] "" Vector__XXX
  SG_ ADB_ActivationRequest2 : 61|2@0+ (1,0) [0|0] "" Vector__XXX
  SG_ AutoInternalLightingRequest2 : 63|2@0+ (1,0) [0|0] "" Vector__XXX

BO_ 1470 IVI_N105: 8 IVI
  SG_ ITM_LeftBlowingLevelDownPush : 0|1@0+ (1,0) [0|1] "" Vector__XXX
  SG_ ITM_HumidSensorSensitivUpPush : 1|1@0+ (1,0) [0|1] "" Vector__XXX
  SG_ ITM_HumidSensorSensitivOperType : 2|1@0+ (1,0) [0|0] "" Vector__XXX
  SG_ ITM_HumidSensorSensitivDownPush : 3|1@0+ (1,0) [0|1] "" Vector__XXX
  SG_ ITM_BlowingLevelLongPush : 4|1@0+ (1,0) [0|1] "" Vector__XXX
  SG_ ITM_AQSSensitivityUpPush : 5|1@0+ (1,0) [0|1] "" Vector__XXX
  SG_ ITM_AQSSensitivityOperationType : 6|1@0+ (1,0) [0|0] "" Vector__XXX
  SG_ ITM_AQSSensitivityDownPush : 7|1@0+ (1,0) [0|1] "" Vector__XXX
  SG_ ITM_LeftFlowDistrRequest : 10|3@0+ (1,0) [0|0] "" Vector__XXX
  SG_ ITM_LeftFlowDistrOperationType : 11|1@0+ (1,0) [0|0] "" Vector__XXX
  SG_ ITM_LeftFlowDistrDownPush : 12|1@0+ (1,0) [0|1] "-" Vector__XXX
  SG_ ITM_LeftBlowingLevelUpPush : 13|1@0+ (1,0) [0|1] "" Vector__XXX
  SG_ ITM_LeftBlowingLevelOperType : 15|2@0+ (1,0) [0|0] "" Vector__XXX
  SG_ ITM_RearLeftBlowLevelOperType : 17|2@0+ (1,0) [0|0] "" Vector__XXX
  SG_ ITM_RearLeftBlowLevelDownPush : 18|1@0+ (1,0) [0|1] "" Vector__XXX
  SG_ ITM_LeftTempUpPush : 19|1@0+ (1,0) [0|1] "-" Vector__XXX
  SG_ ITM_LeftTempOperationType : 21|2@0+ (1,0) [0|0] "" Vector__XXX
  SG_ ITM_LeftTempDownPush : 22|1@0+ (1,0) [0|1] "-" Vector__XXX
  SG_ ITM_LeftFlowDistrUpPush : 23|1@0+ (1,0) [0|1] "-" Vector__XXX
  SG_ ITM_RearLeftTempDownPush : 24|1@0+ (1,0) [0|1] "" Vector__XXX
  SG_ ITM_RearLeftFlowDistrUpPush : 25|1@0+ (1,0) [0|1] "" Vector__XXX
  SG_ ITM_RearLeftFlowDistrRequest : 28|3@0+ (1,0) [0|0] "" Vector__XXX
  SG_ ITM_RearLeftFlowDistrOperType : 29|1@0+ (1,0) [0|0] "" Vector__XXX
  SG_ ITM_RearLeftFlowDistrDownPush : 30|1@0+ (1,0) [0|1] "" Vector__XXX
  SG_ ITM_RearLeftBlowLevelUpPush : 31|1@0+ (1,0) [0|1] "" Vector__XXX
  SG_ ITM_RearRightFlowDistrDownPush : 32|1@0+ (1,0) [0|1] "" Vector__XXX
  SG_ ITM_RearRightBlowLevelUpPush : 33|1@0+ (1,0) [0|1] "" Vector__XXX
  SG_ ITM_RearRightBlowLevelOperType : 35|2@0+ (1,0) [0|0] "" Vector__XXX
  SG_ ITM_RearRightBlowLevelDownPush : 36|1@0+ (1,0) [0|1] "" Vector__XXX
  SG_ ITM_RearLeftTempUpPush : 37|1@0+ (1,0) [0|1] "" Vector__XXX
  SG_ ITM_RearLeftTempOperationType : 39|2@0+ (1,0) [0|0] "" Vector__XXX
  SG_ ITM_RearRightTempOperationType : 41|2@0+ (1,0) [0|0] "" Vector__XXX
  SG_ ITM_RearRightTempDownPush : 42|1@0+ (1,0) [0|1] "" Vector__XXX
  SG_ ITM_RearRightFlowDistrUpPush : 43|1@0+ (1,0) [0|1] "" Vector__XXX
  SG_ ITM_RearRightFlowDistrRequest : 46|3@0+ (1,0) [0|0] "" Vector__XXX
  SG_ ITM_RearRightFlowDistrOperType : 47|1@0+ (1,0) [0|0] "" Vector__XXX
  SG_ ITM_RightFlowDistrUpPush : 48|1@0+ (1,0) [0|1] "-" Vector__XXX
  SG_ ITM_RightFlowDistrOperationType : 49|1@0+ (1,0) [0|0] "" Vector__XXX
  SG_ ITM_RightFlowDistrDownPush : 50|1@0+ (1,0) [0|1] "-" Vector__XXX
  SG_ ITM_RightBlowingLevelUpPush : 51|1@0+ (1,0) [0|1] "" Vector__XXX
  SG_ ITM_RightBlowingLevelOperType : 53|2@0+ (1,0) [0|0] "" Vector__XXX
  SG_ ITM_RightBlowingLevelDownPush : 54|1@0+ (1,0) [0|1] "" Vector__XXX
  SG_ ITM_RearRightTempUpPush : 55|1@0+ (1,0) [0|1] "" Vector__XXX
  SG_ ITM_TempLongPush : 56|1@0+ (1,0) [0|1] "-" Vector__XXX
  SG_ ITM_RightTempUpPush : 57|1@0+ (1,0) [0|1] "-" Vector__XXX
  SG_ ITM_RightTempOperationType : 59|2@0+ (1,0) [0|0] "" Vector__XXX
  SG_ ITM_RightTempDownPush : 60|1@0+ (1,0) [0|1] "-" Vector__XXX
  SG_ ITM_RightFlowDistrRequest : 63|3@0+ (1,0) [0|0] "" Vector__XXX

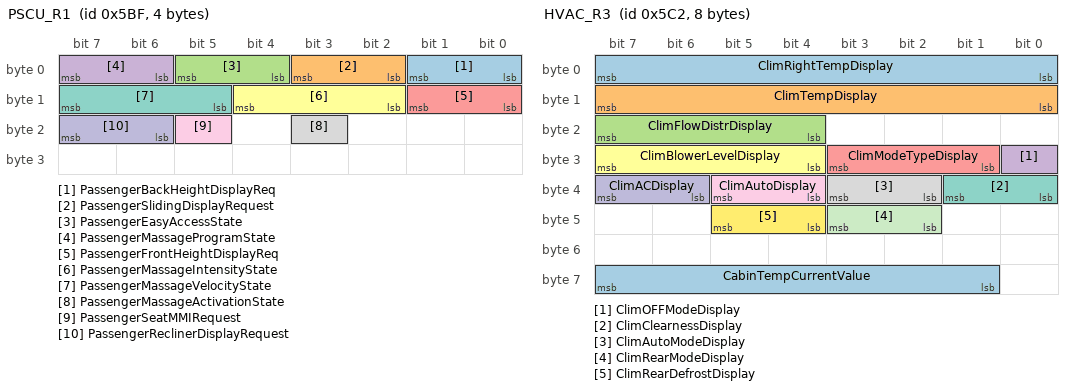
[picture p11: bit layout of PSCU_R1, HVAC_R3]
BO_ 1471 PSCU_R1: 4 Vector__XXX
  SG_ PassengerBackHeightDisplayReq : 1|2@0+ (1,0) [0|0] "" IVI
  SG_ PassengerSlidingDisplayRequest : 3|2@0+ (1,0) [0|0] "" IVI
  SG_ PassengerEasyAccessState : 5|2@0+ (1,0) [0|0] "" IVI
  SG_ PassengerMassageProgramState : 7|2@0+ (1,0) [0|0] "" IVI
  SG_ PassengerFrontHeightDisplayReq : 9|2@0+ (1,0) [0|0] "" IVI
  SG_ PassengerMassageIntensityState : 12|3@0+ (1,0) [0|0] "" IVI
  SG_ PassengerMassageVelocityState : 15|3@0+ (1,0) [0|0] "" IVI
  SG_ PassengerMassageActivationState : 19|1@0+ (1,0) [0|0] "" IVI
  SG_ PassengerSeatMMIRequest : 21|1@0+ (1,0) [0|0] "" IVI
  SG_ PassengerReclinerDisplayRequest : 23|2@0+ (1,0) [0|0] "" IVI

BO_ 1472 MULTIDRIVE_A1: 8 IVI
  SG_ MexModeState : 44|3@0+ (1,0) [0|0] "" Vector__XXX
  SG_ MexModeState_xEV : 63|3@0+ (1,0) [0|0] "" Vector__XXX

BO_ 1474 HVAC_R3: 8 Vector__XXX
  SG_ ClimRightTempDisplay : 7|8@0+ (0.5,0) [10|127.5] "°" IVI
  SG_ ClimTempDisplay : 15|8@0+ (0.5,0) [10|127.5] "°" IVI
  SG_ ClimFlowDistrDisplay : 23|4@0+ (1,0) [0|0] "" IVI
  SG_ ClimOFFModeDisplay : 24|1@0+ (1,0) [0|0] "" IVI
  SG_ ClimModeTypeDisplay : 27|3@0+ (1,0) [0|0] "" IVI
  SG_ ClimBlowerLevelDisplay : 31|4@0+ (1,0) [0|0] "" IVI
  SG_ ClimClearnessDisplay : 33|2@0+ (1,0) [0|0] "" IVI
  SG_ ClimAutoModeDisplay : 35|2@0+ (1,0) [0|0] "" IVI
  SG_ ClimAutoDisplay : 37|2@0+ (1,0) [0|0] "" IVI
  SG_ ClimACDisplay : 39|2@0+ (1,0) [0|0] "" IVI
  SG_ ClimRearModeDisplay : 43|2@0+ (1,0) [0|0] "" IVI
  SG_ ClimRearDefrostDisplay : 45|2@0+ (1,0) [0|0] "" IVI
  SG_ CabinTempCurrentValue : 63|7@0+ (1,-40) [-40|60] "°C" IVI

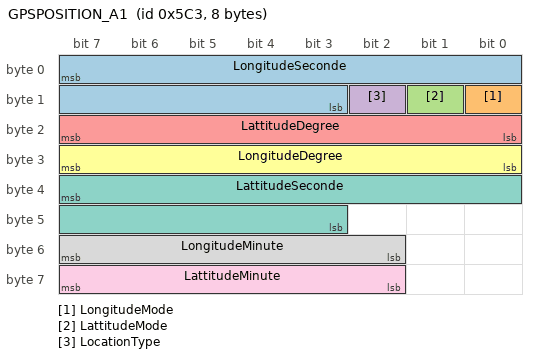
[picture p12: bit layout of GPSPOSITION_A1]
BO_ 1475 GPSPOSITION_A1: 8 IVI
  SG_ LongitudeSeconde : 7|13@0+ (0.01,0) [0|59.99] "s" Vector__XXX
  SG_ LongitudeMode : 8|1@0+ (1,0) [0|0] "" Vector__XXX
  SG_ LattitudeMode : 9|1@0+ (1,0) [0|0] "" Vector__XXX
  SG_ LocationType : 10|1@0+ (1,0) [0|0] "" Vector__XXX
  SG_ LattitudeDegree : 23|8@0+ (1,0) [0|180] "°" Vector__XXX
  SG_ LongitudeDegree : 31|8@0+ (1,0) [0|180] "°" Vector__XXX
  SG_ LattitudeSeconde : 39|13@0+ (0.01,0) [0|59.99] "s" Vector__XXX
  SG_ LongitudeMinute : 55|6@0+ (1,0) [0|59] "min" Vector__XXX
  SG_ LattitudeMinute : 63|6@0+ (1,0) [0|59] "min" Vector__XXX

CM_ BO_ 1386 "[C1AHS-T3-2017]: Specific C1A  frame";
BA_DEF_ BO_  "CANFD_BRS" ENUM "0","1";
BA_DEF_ BO_  "GenMsgSendType" STRING;
BA_DEF_ SG_  "Unavailable_Value" STRING;
BA_DEF_ BO_  "VFrameFormat" ENUM "StandardCAN","ExtendedCAN","reserved","reserved","reserved","reserved","reserved","reserved","reserved","reserved","reserved","reserved","reserved","reserved","StandardCAN_FD","ExtendedCAN_FD";
BA_DEF_ BO_  "GenMsgCycleTime" INT 0 50000;
BA_DEF_ BO_  "Exclusion_time" INT 0 50000;
BA_DEF_ SG_  "Event" STRING;
BA_DEF_ BO_  "Optional_Frame" STRING;

BA_DEF_DEF_  "CANFD_BRS" "0";
BA_DEF_DEF_  "Event" "false";
BA_DEF_DEF_  "GenMsgCycleTime" 0;
BA_DEF_DEF_  "Optional_Frame" "false";
BA_DEF_DEF_  "VFrameFormat" "StandardCAN";
BA_ "GenMsgCycleTime" BO_ 1345 1000;
BA_ "GenMsgSendType" BO_ 1345 "Periodic";
BA_ "GenMsgCycleTime" BO_ 1356 500;
BA_ "GenMsgSendType" BO_ 1356 "Periodic";
BA_ "Exclusion_time" BO_ 1365 20;
BA_ "GenMsgCycleTime" BO_ 1365 500;
BA_ "GenMsgSendType" BO_ 1365 "Periodic and Event";
BA_ "Exclusion_time" BO_ 1369 10;
BA_ "GenMsgCycleTime" BO_ 1369 500;
BA_ "GenMsgSendType" BO_ 1369 "Periodic and Event";
BA_ "Exclusion_time" BO_ 1380 100;
BA_ "GenMsgCycleTime" BO_ 1380 500;
BA_ "GenMsgSendType" BO_ 1380 "Periodic and Event";
BA_ "Exclusion_time" BO_ 1381 10;
BA_ "GenMsgCycleTime" BO_ 1381 500;
BA_ "GenMsgSendType" BO_ 1381 "Periodic and Event";
BA_ "Exclusion_time" BO_ 1384 20;
BA_ "GenMsgCycleTime" BO_ 1384 1000;
BA_ "GenMsgSendType" BO_ 1384 "Periodic and Event";
BA_ "GenMsgCycleTime" BO_ 1386 200;
BA_ "GenMsgSendType" BO_ 1386 "Periodic";
BA_ "Exclusion_time" BO_ 1392 100;
BA_ "GenMsgCycleTime" BO_ 1392 3000;
BA_ "GenMsgSendType" BO_ 1392 "Periodic and Event";
BA_ "Exclusion_time" BO_ 1394 20;
BA_ "GenMsgCycleTime" BO_ 1394 500;
BA_ "GenMsgSendType" BO_ 1394 "Periodic and Event";
BA_ "Exclusion_time" BO_ 1398 100;
BA_ "GenMsgCycleTime" BO_ 1398 3000;
BA_ "GenMsgSendType" BO_ 1398 "Periodic and Event";
BA_ "Exclusion_time" BO_ 1402 10;
BA_ "GenMsgCycleTime" BO_ 1402 500;
BA_ "GenMsgSendType" BO_ 1402 "Periodic and Event";
BA_ "Exclusion_time" BO_ 1410 20;
BA_ "GenMsgCycleTime" BO_ 1410 500;
BA_ "GenMsgSendType" BO_ 1410 "Periodic and Event";
BA_ "Exclusion_time" BO_ 1412 100;
BA_ "GenMsgCycleTime" BO_ 1412 500;
BA_ "GenMsgSendType" BO_ 1412 "Periodic and Event";
BA_ "Exclusion_time" BO_ 1413 20;
BA_ "GenMsgCycleTime" BO_ 1413 500;
BA_ "GenMsgSendType" BO_ 1413 "Periodic and Event";
BA_ "Exclusion_time" BO_ 1415 20;
BA_ "GenMsgCycleTime" BO_ 1415 500;
BA_ "GenMsgSendType" BO_ 1415 "Periodic and Event";
BA_ "Exclusion_time" BO_ 1422 20;
BA_ "GenMsgCycleTime" BO_ 1422 1000;
BA_ "GenMsgSendType" BO_ 1422 "Periodic and Event";
BA_ "Exclusion_time" BO_ 1424 20;
BA_ "GenMsgCycleTime" BO_ 1424 500;
BA_ "GenMsgSendType" BO_ 1424 "Periodic and Event";
BA_ "Exclusion_time" BO_ 1429 20;
BA_ "GenMsgCycleTime" BO_ 1429 500;
BA_ "GenMsgSendType" BO_ 1429 "Periodic and Event";
BA_ "Exclusion_time" BO_ 1436 10;
BA_ "GenMsgCycleTime" BO_ 1436 200;
BA_ "GenMsgSendType" BO_ 1436 "Periodic and Event";
BA_ "GenMsgCycleTime" BO_ 1439 500;
BA_ "GenMsgSendType" BO_ 1439 "Periodic";
BA_ "Exclusion_time" BO_ 1443 100;
BA_ "GenMsgCycleTime" BO_ 1443 500;
BA_ "GenMsgSendType" BO_ 1443 "Periodic and Event";
BA_ "Exclusion_time" BO_ 1444 100;
BA_ "GenMsgCycleTime" BO_ 1444 500;
BA_ "GenMsgSendType" BO_ 1444 "Periodic and Event";
BA_ "Exclusion_time" BO_ 1446 100;
BA_ "GenMsgCycleTime" BO_ 1446 500;
BA_ "GenMsgSendType" BO_ 1446 "Periodic and Event";
BA_ "Exclusion_time" BO_ 1447 100;
BA_ "GenMsgCycleTime" BO_ 1447 1000;
BA_ "GenMsgSendType" BO_ 1447 "Periodic and Event";
BA_ "Exclusion_time" BO_ 1448 20;
BA_ "GenMsgCycleTime" BO_ 1448 500;
BA_ "GenMsgSendType" BO_ 1448 "Periodic and Event";
BA_ "Exclusion_time" BO_ 1449 50;
BA_ "GenMsgCycleTime" BO_ 1449 1000;
BA_ "GenMsgSendType" BO_ 1449 "Periodic and Event";
BA_ "Exclusion_time" BO_ 1450 100;
BA_ "GenMsgCycleTime" BO_ 1450 1000;
BA_ "GenMsgSendType" BO_ 1450 "Periodic and Event";
BA_ "Exclusion_time" BO_ 1457 100;
BA_ "GenMsgCycleTime" BO_ 1457 500;
BA_ "GenMsgSendType" BO_ 1457 "Periodic and Event";
BA_ "Exclusion_time" BO_ 1458 100;
BA_ "GenMsgCycleTime" BO_ 1458 3000;
BA_ "GenMsgSendType" BO_ 1458 "Periodic and Event";
BA_ "Exclusion_time" BO_ 1459 100;
BA_ "GenMsgCycleTime" BO_ 1459 500;
BA_ "GenMsgSendType" BO_ 1459 "Periodic and Event";
BA_ "Exclusion_time" BO_ 1462 50;
BA_ "GenMsgCycleTime" BO_ 1462 1000;
BA_ "GenMsgSendType" BO_ 1462 "Periodic and Event";
BA_ "Exclusion_time" BO_ 1464 100;
BA_ "GenMsgCycleTime" BO_ 1464 3000;
BA_ "GenMsgSendType" BO_ 1464 "Periodic and Event";
BA_ "Exclusion_time" BO_ 1465 100;
BA_ "GenMsgCycleTime" BO_ 1465 1000;
BA_ "GenMsgSendType" BO_ 1465 "Periodic and Event";
BA_ "Exclusion_time" BO_ 1466 100;
BA_ "GenMsgCycleTime" BO_ 1466 500;
BA_ "GenMsgSendType" BO_ 1466 "Periodic and Event";
BA_ "Exclusion_time" BO_ 1468 100;
BA_ "GenMsgCycleTime" BO_ 1468 1000;
BA_ "GenMsgSendType" BO_ 1468 "Periodic and Event";
BA_ "Exclusion_time" BO_ 1469 100;
BA_ "GenMsgCycleTime" BO_ 1469 3000;
BA_ "GenMsgSendType" BO_ 1469 "Periodic and Event";
BA_ "Exclusion_time" BO_ 1470 50;
BA_ "GenMsgCycleTime" BO_ 1470 1000;
BA_ "GenMsgSendType" BO_ 1470 "Periodic and Event";
BA_ "Exclusion_time" BO_ 1471 100;
BA_ "GenMsgCycleTime" BO_ 1471 1000;
BA_ "GenMsgSendType" BO_ 1471 "Periodic and Event";
BA_ "Exclusion_time" BO_ 1472 100;
BA_ "GenMsgCycleTime" BO_ 1472 1000;
BA_ "GenMsgSendType" BO_ 1472 "Periodic and Event";
BA_ "Exclusion_time" BO_ 1474 20;
BA_ "GenMsgCycleTime" BO_ 1474 1000;
BA_ "GenMsgSendType" BO_ 1474 "Periodic and Event";
BA_ "Exclusion_time" BO_ 1475 100;
BA_ "GenMsgCycleTime" BO_ 1475 1000;
BA_ "GenMsgSendType" BO_ 1475 "Periodic and Event";
BA_ "Unavailable_Value" SG_ 1345 NAVI_TrafficUpdate "0b0";
BA_ "Unavailable_Value" SG_ 1345 NAVI_TrafficRetransmission "0b0";
BA_ "Unavailable_Value" SG_ 1345 NAVI_TrafficAccuracy "0b00";
BA_ "Event" SG_ 1365 FAPK_DefaultManeuverTypeState "true";
BA_ "Event" SG_ 1365 FAPK_DefaultManeuverTypeState "true";
BA_ "Event" SG_ 1365 FAPK_DefaultManeuverTypeState "true";
BA_ "Event" SG_ 1365 FAPK_DefaultManeuverTypeState "true";
BA_ "Unavailable_Value" SG_ 1365 FAPK_DefaultManeuverTypeState "0b111";
BA_ "Event" SG_ 1365 ZoomAutoActivationState "true";
BA_ "Event" SG_ 1365 ZoomAutoActivationState "true";
BA_ "Event" SG_ 1365 ZoomAutoActivationState "true";
BA_ "Event" SG_ 1365 ZoomAutoActivationState "true";
BA_ "Unavailable_Value" SG_ 1365 ZoomAutoActivationState "0b0";
BA_ "Event" SG_ 1365 AVM_GuidelineActivationState "true";
BA_ "Event" SG_ 1365 AVM_GuidelineActivationState "true";
BA_ "Event" SG_ 1365 AVM_GuidelineActivationState "true";
BA_ "Event" SG_ 1365 AVM_GuidelineActivationState "true";
BA_ "Unavailable_Value" SG_ 1365 AVM_GuidelineActivationState "0b111";
BA_ "Event" SG_ 1365 APA_ManeuverFeedback "true";
BA_ "Event" SG_ 1365 APA_ManeuverFeedback "true";
BA_ "Event" SG_ 1365 APA_ManeuverFeedback "true";
BA_ "Event" SG_ 1365 APA_ManeuverFeedback "true";
BA_ "Unavailable_Value" SG_ 1365 APA_ManeuverFeedback "0b11";
BA_ "Event" SG_ 1365 APAStart_SwitchStatus "true";
BA_ "Event" SG_ 1365 APAStart_SwitchStatus "true";
BA_ "Event" SG_ 1365 APAStart_SwitchStatus "true";
BA_ "Event" SG_ 1365 APAStart_SwitchStatus "true";
BA_ "Unavailable_Value" SG_ 1365 APAStart_SwitchStatus "0b000";
BA_ "Event" SG_ 1369 OSE_RearRightDoorAlert "true";
BA_ "Event" SG_ 1369 OSE_RearRightDoorAlert "true";
BA_ "Event" SG_ 1369 OSE_RearRightDoorAlert "true";
BA_ "Event" SG_ 1369 OSE_RearRightDoorAlert "true";
BA_ "Unavailable_Value" SG_ 1369 OSE_RearRightDoorAlert "0b00";
BA_ "Event" SG_ 1369 OSE_RearLeftDoorAlert "true";
BA_ "Event" SG_ 1369 OSE_RearLeftDoorAlert "true";
BA_ "Event" SG_ 1369 OSE_RearLeftDoorAlert "true";
BA_ "Event" SG_ 1369 OSE_RearLeftDoorAlert "true";
BA_ "Unavailable_Value" SG_ 1369 OSE_RearLeftDoorAlert "0b00";
BA_ "Event" SG_ 1369 OSE_FrontLeftDoorAlert "true";
BA_ "Event" SG_ 1369 OSE_FrontLeftDoorAlert "true";
BA_ "Event" SG_ 1369 OSE_FrontLeftDoorAlert "true";
BA_ "Event" SG_ 1369 OSE_FrontLeftDoorAlert "true";
BA_ "Unavailable_Value" SG_ 1369 OSE_FrontLeftDoorAlert "0b00";
BA_ "Event" SG_ 1369 OSE_FronRightDoorAlert "true";
BA_ "Event" SG_ 1369 OSE_FronRightDoorAlert "true";
BA_ "Event" SG_ 1369 OSE_FronRightDoorAlert "true";
BA_ "Event" SG_ 1369 OSE_FronRightDoorAlert "true";
BA_ "Unavailable_Value" SG_ 1369 OSE_FronRightDoorAlert "0b00";
BA_ "Event" SG_ 1369 ADAS_LinkFailureRequest "true";
BA_ "Event" SG_ 1369 ADAS_LinkFailureRequest "true";
BA_ "Event" SG_ 1369 ADAS_LinkFailureRequest "true";
BA_ "Event" SG_ 1369 ADAS_LinkFailureRequest "true";
BA_ "Event" SG_ 1369 ADAS_BranchDirection "true";
BA_ "Event" SG_ 1369 ADAS_BranchDirection "true";
BA_ "Event" SG_ 1369 ADAS_BranchDirection "true";
BA_ "Event" SG_ 1369 ADAS_BranchDirection "true";
BA_ "Unavailable_Value" SG_ 1369 ADAS_BranchDirection "0b00";
BA_ "Event" SG_ 1369 ADAS_LinkFailurePoint "true";
BA_ "Event" SG_ 1369 ADAS_LinkFailurePoint "true";
BA_ "Event" SG_ 1369 ADAS_LinkFailurePoint "true";
BA_ "Event" SG_ 1369 ADAS_LinkFailurePoint "true";
BA_ "Event" SG_ 1369 OSE_ActivationState "true";
BA_ "Event" SG_ 1369 OSE_ActivationState "true";
BA_ "Event" SG_ 1369 OSE_ActivationState "true";
BA_ "Event" SG_ 1369 OSE_ActivationState "true";
BA_ "Unavailable_Value" SG_ 1369 OSE_ActivationState "0b0";
BA_ "Event" SG_ 1369 ELKA_ActivationState "true";
BA_ "Event" SG_ 1369 ELKA_ActivationState "true";
BA_ "Event" SG_ 1369 ELKA_ActivationState "true";
BA_ "Event" SG_ 1369 ELKA_ActivationState "true";
BA_ "Unavailable_Value" SG_ 1369 ELKA_ActivationState "0b1";
BA_ "Event" SG_ 1369 ADAS_LinkFailureCounter "true";
BA_ "Event" SG_ 1369 ADAS_LinkFailureCounter "true";
BA_ "Event" SG_ 1369 ADAS_LinkFailureCounter "true";
BA_ "Event" SG_ 1369 ADAS_LinkFailureCounter "true";
BA_ "Event" SG_ 1369 SET_MAPAutoUpdate_State "true";
BA_ "Event" SG_ 1369 SET_MAPAutoUpdate_State "true";
BA_ "Event" SG_ 1369 SET_MAPAutoUpdate_State "true";
BA_ "Event" SG_ 1369 SET_MAPAutoUpdate_State "true";
BA_ "Unavailable_Value" SG_ 1369 SET_MAPAutoUpdate_State "0b00";
BA_ "Event" SG_ 1369 SET_FocusState_State "true";
BA_ "Event" SG_ 1369 SET_FocusState_State "true";
BA_ "Event" SG_ 1369 SET_FocusState_State "true";
BA_ "Event" SG_ 1369 SET_FocusState_State "true";
BA_ "Unavailable_Value" SG_ 1369 SET_FocusState_State "0b00";
BA_ "Event" SG_ 1369 SET_ADL3_State "true";
BA_ "Event" SG_ 1369 SET_ADL3_State "true";
BA_ "Event" SG_ 1369 SET_ADL3_State "true";
BA_ "Event" SG_ 1369 SET_ADL3_State "true";
BA_ "Unavailable_Value" SG_ 1369 SET_ADL3_State "0b00";
BA_ "Event" SG_ 1369 SET_ALCP2P_AlertLevel_State "true";
BA_ "Event" SG_ 1369 SET_ALCP2P_AlertLevel_State "true";
BA_ "Event" SG_ 1369 SET_ALCP2P_AlertLevel_State "true";
BA_ "Event" SG_ 1369 SET_ALCP2P_AlertLevel_State "true";
BA_ "Unavailable_Value" SG_ 1369 SET_ALCP2P_AlertLevel_State "0b00";
BA_ "Unavailable_Value" SG_ 1380 TripAverageConsumption "0x3FF";
BA_ "Unavailable_Value" SG_ 1380 TripUnitConsumption "0b000";
BA_ "Event" SG_ 1380 FrostWarningDisplay "true";
BA_ "Event" SG_ 1380 FrostWarningDisplay "true";
BA_ "Event" SG_ 1380 FrostWarningDisplay "true";
BA_ "Event" SG_ 1380 FrostWarningDisplay "true";
BA_ "Unavailable_Value" SG_ 1380 FrostWarningDisplay "0b0";
BA_ "Unavailable_Value" SG_ 1380 TripUnitDistance "0b00";
BA_ "Event" SG_ 1380 MeterLanguageStatus "true";
BA_ "Event" SG_ 1380 MeterLanguageStatus "true";
BA_ "Event" SG_ 1380 MeterLanguageStatus "true";
BA_ "Event" SG_ 1380 MeterLanguageStatus "true";
BA_ "Unavailable_Value" SG_ 1380 MeterLanguageStatus "0x00";
BA_ "Event" SG_ 1380 TripDistance "true";
BA_ "Event" SG_ 1380 TripDistance "true";
BA_ "Event" SG_ 1380 TripDistance "true";
BA_ "Event" SG_ 1380 TripDistance "true";
BA_ "Unavailable_Value" SG_ 1380 TripDistance "0x1FFFF";
BA_ "Event" SG_ 1380 Meter_FOTA_status "true";
BA_ "Event" SG_ 1380 Meter_FOTA_status "true";
BA_ "Event" SG_ 1380 Meter_FOTA_status "true";
BA_ "Event" SG_ 1380 Meter_FOTA_status "true";
BA_ "Unavailable_Value" SG_ 1380 Meter_FOTA_status "0x1F";
BA_ "Event" SG_ 1381 BSWrad_ActivationState "true";
BA_ "Event" SG_ 1381 BSWrad_ActivationState "true";
BA_ "Event" SG_ 1381 BSWrad_ActivationState "true";
BA_ "Event" SG_ 1381 BSWrad_ActivationState "true";
BA_ "Unavailable_Value" SG_ 1381 BSWrad_ActivationState "0b0";
BA_ "Event" SG_ 1381 CTA_AlertStatus "true";
BA_ "Event" SG_ 1381 CTA_AlertStatus "true";
BA_ "Event" SG_ 1381 CTA_AlertStatus "true";
BA_ "Event" SG_ 1381 CTA_AlertStatus "true";
BA_ "Unavailable_Value" SG_ 1381 CTA_AlertStatus "0b00";
BA_ "Event" SG_ 1381 CTA_CollisionRiskAlert "true";
BA_ "Event" SG_ 1381 CTA_CollisionRiskAlert "true";
BA_ "Event" SG_ 1381 CTA_CollisionRiskAlert "true";
BA_ "Event" SG_ 1381 CTA_CollisionRiskAlert "true";
BA_ "Unavailable_Value" SG_ 1381 CTA_CollisionRiskAlert "0b0";
BA_ "Event" SG_ 1381 CTA_StatusDisplay_v2 "true";
BA_ "Event" SG_ 1381 CTA_StatusDisplay_v2 "true";
BA_ "Event" SG_ 1381 CTA_StatusDisplay_v2 "true";
BA_ "Event" SG_ 1381 CTA_StatusDisplay_v2 "true";
BA_ "Event" SG_ 1384 MexModeState_v3 "true";
BA_ "Event" SG_ 1384 MexModeState_v3 "true";
BA_ "Event" SG_ 1384 MexModeState_v3 "true";
BA_ "Event" SG_ 1384 MexModeState_v3 "true";
BA_ "Unavailable_Value" SG_ 1384 MexModeState_v3 "0b0000";
BA_ "Event" SG_ 1384 MexAutoState "true";
BA_ "Event" SG_ 1384 MexAutoState "true";
BA_ "Event" SG_ 1384 MexAutoState "true";
BA_ "Event" SG_ 1384 MexAutoState "true";
BA_ "Unavailable_Value" SG_ 1384 MexAutoState "0b0";
BA_ "Event" SG_ 1384 ADBSettingRequest "true";
BA_ "Event" SG_ 1384 ADBSettingRequest "true";
BA_ "Event" SG_ 1384 ADBSettingRequest "true";
BA_ "Event" SG_ 1384 ADBSettingRequest "true";
BA_ "Unavailable_Value" SG_ 1384 ADBSettingRequest "0b000";
BA_ "Event" SG_ 1384 CurrentSpecificUserState "true";
BA_ "Event" SG_ 1384 CurrentSpecificUserState "true";
BA_ "Event" SG_ 1384 CurrentSpecificUserState "true";
BA_ "Event" SG_ 1384 CurrentSpecificUserState "true";
BA_ "Event" SG_ 1384 VDCSettingRequest "true";
BA_ "Event" SG_ 1384 VDCSettingRequest "true";
BA_ "Event" SG_ 1384 VDCSettingRequest "true";
BA_ "Event" SG_ 1384 VDCSettingRequest "true";
BA_ "Unavailable_Value" SG_ 1384 VDCSettingRequest "0b0000";
BA_ "Unavailable_Value" SG_ 1386 ClimCabinParticleConcDisplay "0x3FF";
BA_ "Unavailable_Value" SG_ 1386 ClimExternParticleConcDisplay "0x3FF";
BA_ "Event" SG_ 1392 HUD_ADASactivationRequest2 "true";
BA_ "Event" SG_ 1392 HUD_ADASactivationRequest2 "true";
BA_ "Event" SG_ 1392 HUD_ADASactivationRequest2 "true";
BA_ "Event" SG_ 1392 HUD_ADASactivationRequest2 "true";
BA_ "Unavailable_Value" SG_ 1392 HUD_ADASactivationRequest2 "0b00";
BA_ "Event" SG_ 1392 VSPsoundChoiceActivationRequest2 "true";
BA_ "Event" SG_ 1392 VSPsoundChoiceActivationRequest2 "true";
BA_ "Event" SG_ 1392 VSPsoundChoiceActivationRequest2 "true";
BA_ "Event" SG_ 1392 VSPsoundChoiceActivationRequest2 "true";
BA_ "Event" SG_ 1392 FAPK_DefaultManeuverTypeRequest2 "true";
BA_ "Event" SG_ 1392 FAPK_DefaultManeuverTypeRequest2 "true";
BA_ "Event" SG_ 1392 FAPK_DefaultManeuverTypeRequest2 "true";
BA_ "Event" SG_ 1392 FAPK_DefaultManeuverTypeRequest2 "true";
BA_ "Unavailable_Value" SG_ 1392 FAPK_DefaultManeuverTypeRequest2 "0b000";
BA_ "Event" SG_ 1392 AmbientLightingColor_v3 "true";
BA_ "Event" SG_ 1392 AmbientLightingColor_v3 "true";
BA_ "Event" SG_ 1392 AmbientLightingColor_v3 "true";
BA_ "Event" SG_ 1392 AmbientLightingColor_v3 "true";
BA_ "Unavailable_Value" SG_ 1392 AmbientLightingColor_v3 "0x0";
BA_ "Event" SG_ 1392 FOTA_ReadyToSleep_IVI "true";
BA_ "Event" SG_ 1392 FOTA_ReadyToSleep_IVI "true";
BA_ "Event" SG_ 1392 FOTA_ReadyToSleep_IVI "true";
BA_ "Event" SG_ 1392 FOTA_ReadyToSleep_IVI "true";
BA_ "Unavailable_Value" SG_ 1392 FOTA_ReadyToSleep_IVI "0b1";
BA_ "Event" SG_ 1392 VSPSoundActivationRequest2 "true";
BA_ "Event" SG_ 1392 VSPSoundActivationRequest2 "true";
BA_ "Event" SG_ 1392 VSPSoundActivationRequest2 "true";
BA_ "Event" SG_ 1392 VSPSoundActivationRequest2 "true";
BA_ "Event" SG_ 1392 HUD_TurnByTurnActivationRequest2 "true";
BA_ "Event" SG_ 1392 HUD_TurnByTurnActivationRequest2 "true";
BA_ "Event" SG_ 1392 HUD_TurnByTurnActivationRequest2 "true";
BA_ "Event" SG_ 1392 HUD_TurnByTurnActivationRequest2 "true";
BA_ "Unavailable_Value" SG_ 1392 HUD_TurnByTurnActivationRequest2 "0b00";
BA_ "Event" SG_ 1392 HUD_TSRactivationRequest2 "true";
BA_ "Event" SG_ 1392 HUD_TSRactivationRequest2 "true";
BA_ "Event" SG_ 1392 HUD_TSRactivationRequest2 "true";
BA_ "Event" SG_ 1392 HUD_TSRactivationRequest2 "true";
BA_ "Unavailable_Value" SG_ 1392 HUD_TSRactivationRequest2 "0b00";
BA_ "Event" SG_ 1392 SET_Acceleration_Request2 "true";
BA_ "Event" SG_ 1392 SET_Acceleration_Request2 "true";
BA_ "Event" SG_ 1392 SET_Acceleration_Request2 "true";
BA_ "Event" SG_ 1392 SET_Acceleration_Request2 "true";
BA_ "Event" SG_ 1392 SET_NavigatDriveAssist_Request2 "true";
BA_ "Event" SG_ 1392 SET_NavigatDriveAssist_Request2 "true";
BA_ "Event" SG_ 1392 SET_NavigatDriveAssist_Request2 "true";
BA_ "Event" SG_ 1392 SET_NavigatDriveAssist_Request2 "true";
BA_ "Event" SG_ 1392 SET_ALCActivationByTSIG_Request2 "true";
BA_ "Event" SG_ 1392 SET_ALCActivationByTSIG_Request2 "true";
BA_ "Event" SG_ 1392 SET_ALCActivationByTSIG_Request2 "true";
BA_ "Event" SG_ 1392 SET_ALCActivationByTSIG_Request2 "true";
BA_ "Event" SG_ 1392 SET_Deceleration_Request2 "true";
BA_ "Event" SG_ 1392 SET_Deceleration_Request2 "true";
BA_ "Event" SG_ 1392 SET_Deceleration_Request2 "true";
BA_ "Event" SG_ 1392 SET_Deceleration_Request2 "true";
BA_ "Event" SG_ 1392 SET_OvertakingAssist_Request2 "true";
BA_ "Event" SG_ 1392 SET_OvertakingAssist_Request2 "true";
BA_ "Event" SG_ 1392 SET_OvertakingAssist_Request2 "true";
BA_ "Event" SG_ 1392 SET_OvertakingAssist_Request2 "true";
BA_ "Event" SG_ 1392 SET_LaneChangeSwiftness_Request2 "true";
BA_ "Event" SG_ 1392 SET_LaneChangeSwiftness_Request2 "true";
BA_ "Event" SG_ 1392 SET_LaneChangeSwiftness_Request2 "true";
BA_ "Event" SG_ 1392 SET_LaneChangeSwiftness_Request2 "true";
BA_ "Event" SG_ 1392 SET_CornerSpeedLevel_Request2 "true";
BA_ "Event" SG_ 1392 SET_CornerSpeedLevel_Request2 "true";
BA_ "Event" SG_ 1392 SET_CornerSpeedLevel_Request2 "true";
BA_ "Event" SG_ 1392 SET_CornerSpeedLevel_Request2 "true";
BA_ "Event" SG_ 1392 SET_VoiceGuidance_Request2 "true";
BA_ "Event" SG_ 1392 SET_VoiceGuidance_Request2 "true";
BA_ "Event" SG_ 1392 SET_VoiceGuidance_Request2 "true";
BA_ "Event" SG_ 1392 SET_VoiceGuidance_Request2 "true";
BA_ "Event" SG_ 1392 SET_PositionInLane_Request2 "true";
BA_ "Event" SG_ 1392 SET_PositionInLane_Request2 "true";
BA_ "Event" SG_ 1392 SET_PositionInLane_Request2 "true";
BA_ "Event" SG_ 1392 SET_PositionInLane_Request2 "true";
BA_ "Event" SG_ 1392 SET_OvertakeRelatSpeed_Request2 "true";
BA_ "Event" SG_ 1392 SET_OvertakeRelatSpeed_Request2 "true";
BA_ "Event" SG_ 1392 SET_OvertakeRelatSpeed_Request2 "true";
BA_ "Event" SG_ 1392 SET_OvertakeRelatSpeed_Request2 "true";
BA_ "Event" SG_ 1392 IVI_SafeModeAck "true";
BA_ "Event" SG_ 1392 IVI_SafeModeAck "true";
BA_ "Event" SG_ 1392 IVI_SafeModeAck "true";
BA_ "Event" SG_ 1392 IVI_SafeModeAck "true";
BA_ "Unavailable_Value" SG_ 1392 IVI_SafeModeAck "0b0";
BA_ "Event" SG_ 1392 WDA_ActivationRequest2 "true";
BA_ "Event" SG_ 1392 WDA_ActivationRequest2 "true";
BA_ "Event" SG_ 1392 WDA_ActivationRequest2 "true";
BA_ "Event" SG_ 1392 WDA_ActivationRequest2 "true";
BA_ "Event" SG_ 1392 RAB_ActivationRequest2 "true";
BA_ "Event" SG_ 1392 RAB_ActivationRequest2 "true";
BA_ "Event" SG_ 1392 RAB_ActivationRequest2 "true";
BA_ "Event" SG_ 1392 RAB_ActivationRequest2 "true";
BA_ "Event" SG_ 1392 RST_PedalMappingRequest "true";
BA_ "Event" SG_ 1392 RST_PedalMappingRequest "true";
BA_ "Event" SG_ 1392 RST_PedalMappingRequest "true";
BA_ "Event" SG_ 1392 RST_PedalMappingRequest "true";
BA_ "Unavailable_Value" SG_ 1392 RST_PedalMappingRequest "0b111";
BA_ "Event" SG_ 1392 VirtualKeySuspendReq2 "true";
BA_ "Event" SG_ 1392 VirtualKeySuspendReq2 "true";
BA_ "Event" SG_ 1392 VirtualKeySuspendReq2 "true";
BA_ "Event" SG_ 1392 VirtualKeySuspendReq2 "true";
BA_ "Event" SG_ 1392 SET_MAPAutoUpdate_Request2 "true";
BA_ "Event" SG_ 1392 SET_MAPAutoUpdate_Request2 "true";
BA_ "Event" SG_ 1392 SET_MAPAutoUpdate_Request2 "true";
BA_ "Event" SG_ 1392 SET_MAPAutoUpdate_Request2 "true";
BA_ "Unavailable_Value" SG_ 1392 SET_MAPAutoUpdate_Request2 "0b00";
BA_ "Event" SG_ 1392 SET_FocusState_Request2 "true";
BA_ "Event" SG_ 1392 SET_FocusState_Request2 "true";
BA_ "Event" SG_ 1392 SET_FocusState_Request2 "true";
BA_ "Event" SG_ 1392 SET_FocusState_Request2 "true";
BA_ "Unavailable_Value" SG_ 1392 SET_FocusState_Request2 "0b00";
BA_ "Event" SG_ 1392 SET_ADL3_Request2 "true";
BA_ "Event" SG_ 1392 SET_ADL3_Request2 "true";
BA_ "Event" SG_ 1392 SET_ADL3_Request2 "true";
BA_ "Event" SG_ 1392 SET_ADL3_Request2 "true";
BA_ "Unavailable_Value" SG_ 1392 SET_ADL3_Request2 "0b00";
BA_ "Event" SG_ 1394 E_Hor_MedRange_CartoData "true";
BA_ "Event" SG_ 1394 E_Hor_MedRange_CartoData "true";
BA_ "Event" SG_ 1394 E_Hor_MedRange_CartoData "true";
BA_ "Event" SG_ 1394 E_Hor_MedRange_CartoData "true";
BA_ "Unavailable_Value" SG_ 1394 E_Hor_MedRange_CartoData "null";
BA_ "Event" SG_ 1394 E_Hor_MedRange_DataType "true";
BA_ "Event" SG_ 1394 E_Hor_MedRange_DataType "true";
BA_ "Event" SG_ 1394 E_Hor_MedRange_DataType "true";
BA_ "Event" SG_ 1394 E_Hor_MedRange_DataType "true";
BA_ "Unavailable_Value" SG_ 1394 E_Hor_MedRange_DataType "null";
BA_ "Event" SG_ 1398 ChargingStationComType "true";
BA_ "Event" SG_ 1398 ChargingStationComType "true";
BA_ "Event" SG_ 1398 ChargingStationComType "true";
BA_ "Event" SG_ 1398 ChargingStationComType "true";
BA_ "Unavailable_Value" SG_ 1398 ChargingStationComType "0b111";
BA_ "Event" SG_ 1398 V2G_ServiceActivationState "true";
BA_ "Event" SG_ 1398 V2G_ServiceActivationState "true";
BA_ "Event" SG_ 1398 V2G_ServiceActivationState "true";
BA_ "Event" SG_ 1398 V2G_ServiceActivationState "true";
BA_ "Unavailable_Value" SG_ 1398 V2G_ServiceActivationState "0b000";
BA_ "Event" SG_ 1402 BCI_StatusDisplay "true";
BA_ "Event" SG_ 1402 BCI_StatusDisplay "true";
BA_ "Event" SG_ 1402 BCI_StatusDisplay "true";
BA_ "Event" SG_ 1402 BCI_StatusDisplay "true";
BA_ "Unavailable_Value" SG_ 1402 BCI_StatusDisplay "0b00";
BA_ "Event" SG_ 1402 LDW_SoundType "true";
BA_ "Event" SG_ 1402 LDW_SoundType "true";
BA_ "Event" SG_ 1402 LDW_SoundType "true";
BA_ "Event" SG_ 1402 LDW_SoundType "true";
BA_ "Unavailable_Value" SG_ 1402 LDW_SoundType "0x0";
BA_ "Event" SG_ 1402 LDW_SensibilityState "true";
BA_ "Event" SG_ 1402 LDW_SensibilityState "true";
BA_ "Event" SG_ 1402 LDW_SensibilityState "true";
BA_ "Event" SG_ 1402 LDW_SensibilityState "true";
BA_ "Unavailable_Value" SG_ 1402 LDW_SensibilityState "0b00";
BA_ "Event" SG_ 1402 LDW_ActivationState_v3 "true";
BA_ "Event" SG_ 1402 LDW_ActivationState_v3 "true";
BA_ "Event" SG_ 1402 LDW_ActivationState_v3 "true";
BA_ "Event" SG_ 1402 LDW_ActivationState_v3 "true";
BA_ "Unavailable_Value" SG_ 1402 LDW_ActivationState_v3 "0b00";
BA_ "Event" SG_ 1402 LDW_SoundAlert "true";
BA_ "Event" SG_ 1402 LDW_SoundAlert "true";
BA_ "Event" SG_ 1402 LDW_SoundAlert "true";
BA_ "Event" SG_ 1402 LDW_SoundAlert "true";
BA_ "Unavailable_Value" SG_ 1402 LDW_SoundAlert "0b00";
BA_ "Event" SG_ 1410 MemoParkPositionID "true";
BA_ "Event" SG_ 1410 MemoParkPositionID "true";
BA_ "Event" SG_ 1410 MemoParkPositionID "true";
BA_ "Event" SG_ 1410 MemoParkPositionID "true";
BA_ "Unavailable_Value" SG_ 1410 MemoParkPositionID "0x00";
BA_ "Event" SG_ 1410 MemoParkTargetPositionIDRequest "true";
BA_ "Event" SG_ 1410 MemoParkTargetPositionIDRequest "true";
BA_ "Event" SG_ 1410 MemoParkTargetPositionIDRequest "true";
BA_ "Event" SG_ 1410 MemoParkTargetPositionIDRequest "true";
BA_ "Unavailable_Value" SG_ 1410 MemoParkTargetPositionIDRequest "0x00";
BA_ "Event" SG_ 1410 MemoParkEndPositionAltitude "true";
BA_ "Event" SG_ 1410 MemoParkEndPositionAltitude "true";
BA_ "Event" SG_ 1410 MemoParkEndPositionAltitude "true";
BA_ "Event" SG_ 1410 MemoParkEndPositionAltitude "true";
BA_ "Unavailable_Value" SG_ 1410 MemoParkEndPositionAltitude "0xFFFF";
BA_ "Event" SG_ 1410 MemoParkEndPositionOrientation "true";
BA_ "Event" SG_ 1410 MemoParkEndPositionOrientation "true";
BA_ "Event" SG_ 1410 MemoParkEndPositionOrientation "true";
BA_ "Event" SG_ 1410 MemoParkEndPositionOrientation "true";
BA_ "Unavailable_Value" SG_ 1410 MemoParkEndPositionOrientation "0x1FF";
BA_ "Event" SG_ 1410 MemoPositionDisplayRequest "true";
BA_ "Event" SG_ 1410 MemoPositionDisplayRequest "true";
BA_ "Event" SG_ 1410 MemoPositionDisplayRequest "true";
BA_ "Event" SG_ 1410 MemoPositionDisplayRequest "true";
BA_ "Unavailable_Value" SG_ 1410 MemoPositionDisplayRequest "0b00";
BA_ "Event" SG_ 1410 MemoParkExecutionState "true";
BA_ "Event" SG_ 1410 MemoParkExecutionState "true";
BA_ "Event" SG_ 1410 MemoParkExecutionState "true";
BA_ "Event" SG_ 1410 MemoParkExecutionState "true";
BA_ "Unavailable_Value" SG_ 1410 MemoParkExecutionState "0b00";
BA_ "Event" SG_ 1412 HVAC_ClimShortcutPush "true";
BA_ "Event" SG_ 1412 HVAC_ClimShortcutPush "true";
BA_ "Event" SG_ 1412 HVAC_ClimShortcutPush "true";
BA_ "Event" SG_ 1412 HVAC_ClimShortcutPush "true";
BA_ "Unavailable_Value" SG_ 1412 HVAC_ClimShortcutPush "0b0";
BA_ "Event" SG_ 1413 AVM_ImagePositionX0 "true";
BA_ "Event" SG_ 1413 AVM_ImagePositionX0 "true";
BA_ "Event" SG_ 1413 AVM_ImagePositionX0 "true";
BA_ "Event" SG_ 1413 AVM_ImagePositionX0 "true";
BA_ "Unavailable_Value" SG_ 1413 AVM_ImagePositionX0 "0x7FF";
BA_ "Event" SG_ 1413 AVM_ImagePositionY0 "true";
BA_ "Event" SG_ 1413 AVM_ImagePositionY0 "true";
BA_ "Event" SG_ 1413 AVM_ImagePositionY0 "true";
BA_ "Event" SG_ 1413 AVM_ImagePositionY0 "true";
BA_ "Unavailable_Value" SG_ 1413 AVM_ImagePositionY0 "0x7FF";
BA_ "Event" SG_ 1413 AVM_ImagePositionX1 "true";
BA_ "Event" SG_ 1413 AVM_ImagePositionX1 "true";
BA_ "Event" SG_ 1413 AVM_ImagePositionX1 "true";
BA_ "Event" SG_ 1413 AVM_ImagePositionX1 "true";
BA_ "Unavailable_Value" SG_ 1413 AVM_ImagePositionX1 "0x7FF";
BA_ "Event" SG_ 1413 AVM_ImagePositionY1 "true";
BA_ "Event" SG_ 1413 AVM_ImagePositionY1 "true";
BA_ "Event" SG_ 1413 AVM_ImagePositionY1 "true";
BA_ "Event" SG_ 1413 AVM_ImagePositionY1 "true";
BA_ "Unavailable_Value" SG_ 1413 AVM_ImagePositionY1 "0x7FF";
BA_ "Event" SG_ 1415 FAPK_SelectedManeuverTypeRequest "true";
BA_ "Event" SG_ 1415 FAPK_SelectedManeuverTypeRequest "true";
BA_ "Event" SG_ 1415 FAPK_SelectedManeuverTypeRequest "true";
BA_ "Event" SG_ 1415 FAPK_SelectedManeuverTypeRequest "true";
BA_ "Unavailable_Value" SG_ 1415 FAPK_SelectedManeuverTypeRequest "0b000";
BA_ "Event" SG_ 1422 DriverBackBolsterDisplayReq "true";
BA_ "Event" SG_ 1422 DriverBackBolsterDisplayReq "true";
BA_ "Event" SG_ 1422 DriverBackBolsterDisplayReq "true";
BA_ "Event" SG_ 1422 DriverBackBolsterDisplayReq "true";
BA_ "Unavailable_Value" SG_ 1422 DriverBackBolsterDisplayReq "0b0";
BA_ "Event" SG_ 1422 MC_MovementDisplayRequest "true";
BA_ "Event" SG_ 1422 MC_MovementDisplayRequest "true";
BA_ "Event" SG_ 1422 MC_MovementDisplayRequest "true";
BA_ "Event" SG_ 1422 MC_MovementDisplayRequest "true";
BA_ "Unavailable_Value" SG_ 1422 MC_MovementDisplayRequest "0b0";
BA_ "Event" SG_ 1422 MC_ActivationState "true";
BA_ "Event" SG_ 1422 MC_ActivationState "true";
BA_ "Event" SG_ 1422 MC_ActivationState "true";
BA_ "Event" SG_ 1422 MC_ActivationState "true";
BA_ "Unavailable_Value" SG_ 1422 MC_ActivationState "0b0";
BA_ "Event" SG_ 1422 MC_PositionChangeStatus "true";
BA_ "Event" SG_ 1422 MC_PositionChangeStatus "true";
BA_ "Event" SG_ 1422 MC_PositionChangeStatus "true";
BA_ "Event" SG_ 1422 MC_PositionChangeStatus "true";
BA_ "Unavailable_Value" SG_ 1422 MC_PositionChangeStatus "0x0";
BA_ "Event" SG_ 1422 MCM_PositionSaveRequest "true";
BA_ "Event" SG_ 1422 MCM_PositionSaveRequest "true";
BA_ "Event" SG_ 1422 MCM_PositionSaveRequest "true";
BA_ "Event" SG_ 1422 MCM_PositionSaveRequest "true";
BA_ "Unavailable_Value" SG_ 1422 MCM_PositionSaveRequest "0x0";
BA_ "Event" SG_ 1422 MCM_PositionRecallRequest "true";
BA_ "Event" SG_ 1422 MCM_PositionRecallRequest "true";
BA_ "Event" SG_ 1422 MCM_PositionRecallRequest "true";
BA_ "Event" SG_ 1422 MCM_PositionRecallRequest "true";
BA_ "Unavailable_Value" SG_ 1422 MCM_PositionRecallRequest "0x0";
BA_ "Unavailable_Value" SG_ 1422 DrLumbarDisplayRequest_Z_Axis "0b00";
BA_ "Event" SG_ 1422 MC_TutorialState "true";
BA_ "Event" SG_ 1422 MC_TutorialState "true";
BA_ "Event" SG_ 1422 MC_TutorialState "true";
BA_ "Event" SG_ 1422 MC_TutorialState "true";
BA_ "Unavailable_Value" SG_ 1422 MC_TutorialState "0b0";
BA_ "Event" SG_ 1422 AD_MessageDisplayReq "true";
BA_ "Event" SG_ 1422 AD_MessageDisplayReq "true";
BA_ "Event" SG_ 1422 AD_MessageDisplayReq "true";
BA_ "Event" SG_ 1422 AD_MessageDisplayReq "true";
BA_ "Unavailable_Value" SG_ 1422 AD_MessageDisplayReq "0b00";
BA_ "Event" SG_ 1422 DriverCushionBolsterDisplayReq "true";
BA_ "Event" SG_ 1422 DriverCushionBolsterDisplayReq "true";
BA_ "Event" SG_ 1422 DriverCushionBolsterDisplayReq "true";
BA_ "Event" SG_ 1422 DriverCushionBolsterDisplayReq "true";
BA_ "Unavailable_Value" SG_ 1422 DriverCushionBolsterDisplayReq "0b00";
BA_ "Unavailable_Value" SG_ 1422 DrLumbarDisplayRequest_X_Axis "0b00";
BA_ "Event" SG_ 1424 MemoParkEndPositionLongitude "true";
BA_ "Event" SG_ 1424 MemoParkEndPositionLongitude "true";
BA_ "Event" SG_ 1424 MemoParkEndPositionLongitude "true";
BA_ "Event" SG_ 1424 MemoParkEndPositionLongitude "true";
BA_ "Unavailable_Value" SG_ 1424 MemoParkEndPositionLongitude "0x1FFFFFFF";
BA_ "Event" SG_ 1424 MemoParkEndPositionLatitude "true";
BA_ "Event" SG_ 1424 MemoParkEndPositionLatitude "true";
BA_ "Event" SG_ 1424 MemoParkEndPositionLatitude "true";
BA_ "Event" SG_ 1424 MemoParkEndPositionLatitude "true";
BA_ "Unavailable_Value" SG_ 1424 MemoParkEndPositionLatitude "0xFFFFFFF";
BA_ "Event" SG_ 1429 MemoParkStartPositionLongitude "true";
BA_ "Event" SG_ 1429 MemoParkStartPositionLongitude "true";
BA_ "Event" SG_ 1429 MemoParkStartPositionLongitude "true";
BA_ "Event" SG_ 1429 MemoParkStartPositionLongitude "true";
BA_ "Unavailable_Value" SG_ 1429 MemoParkStartPositionLongitude "0xFFFF";
BA_ "Event" SG_ 1429 MemoParkStartPositionLatitude "true";
BA_ "Event" SG_ 1429 MemoParkStartPositionLatitude "true";
BA_ "Event" SG_ 1429 MemoParkStartPositionLatitude "true";
BA_ "Event" SG_ 1429 MemoParkStartPositionLatitude "true";
BA_ "Unavailable_Value" SG_ 1429 MemoParkStartPositionLatitude "0xFFFF";
BA_ "Event" SG_ 1429 MemoParkStartPositionAltitude "true";
BA_ "Event" SG_ 1429 MemoParkStartPositionAltitude "true";
BA_ "Event" SG_ 1429 MemoParkStartPositionAltitude "true";
BA_ "Event" SG_ 1429 MemoParkStartPositionAltitude "true";
BA_ "Unavailable_Value" SG_ 1429 MemoParkStartPositionAltitude "0x1FF";
BA_ "Event" SG_ 1429 MemoParkStartPositionOrientation "true";
BA_ "Event" SG_ 1429 MemoParkStartPositionOrientation "true";
BA_ "Event" SG_ 1429 MemoParkStartPositionOrientation "true";
BA_ "Event" SG_ 1429 MemoParkStartPositionOrientation "true";
BA_ "Unavailable_Value" SG_ 1429 MemoParkStartPositionOrientation "0x1FF";
BA_ "Event" SG_ 1436 HFP_ManeuverCompletion "true";
BA_ "Event" SG_ 1436 HFP_ManeuverCompletion "true";
BA_ "Event" SG_ 1436 HFP_ManeuverCompletion "true";
BA_ "Event" SG_ 1436 HFP_ManeuverCompletion "true";
BA_ "Unavailable_Value" SG_ 1436 HFP_ManeuverCompletion "0x00";
BA_ "Event" SG_ 1436 HFP_ManeuverChoiceDisplayRequest "true";
BA_ "Event" SG_ 1436 HFP_ManeuverChoiceDisplayRequest "true";
BA_ "Event" SG_ 1436 HFP_ManeuverChoiceDisplayRequest "true";
BA_ "Event" SG_ 1436 HFP_ManeuverChoiceDisplayRequest "true";
BA_ "Unavailable_Value" SG_ 1436 HFP_ManeuverChoiceDisplayRequest "0b0";
BA_ "Event" SG_ 1436 HFP_SelectedManeuverType "true";
BA_ "Event" SG_ 1436 HFP_SelectedManeuverType "true";
BA_ "Event" SG_ 1436 HFP_SelectedManeuverType "true";
BA_ "Event" SG_ 1436 HFP_SelectedManeuverType "true";
BA_ "Unavailable_Value" SG_ 1436 HFP_SelectedManeuverType "0b000";
BA_ "Event" SG_ 1436 HFP_DefaultManeuverType "true";
BA_ "Event" SG_ 1436 HFP_DefaultManeuverType "true";
BA_ "Event" SG_ 1436 HFP_DefaultManeuverType "true";
BA_ "Event" SG_ 1436 HFP_DefaultManeuverType "true";
BA_ "Unavailable_Value" SG_ 1436 HFP_DefaultManeuverType "0b000";
BA_ "Event" SG_ 1436 DetectedSlotLeft_Selection "true";
BA_ "Event" SG_ 1436 DetectedSlotLeft_Selection "true";
BA_ "Event" SG_ 1436 DetectedSlotLeft_Selection "true";
BA_ "Event" SG_ 1436 DetectedSlotLeft_Selection "true";
BA_ "Unavailable_Value" SG_ 1436 DetectedSlotLeft_Selection "0b0";
BA_ "Event" SG_ 1436 HFP_ManeuverMove "true";
BA_ "Event" SG_ 1436 HFP_ManeuverMove "true";
BA_ "Event" SG_ 1436 HFP_ManeuverMove "true";
BA_ "Event" SG_ 1436 HFP_ManeuverMove "true";
BA_ "Unavailable_Value" SG_ 1436 HFP_ManeuverMove "0b00";
BA_ "Event" SG_ 1436 HFP_SoundRequest "true";
BA_ "Event" SG_ 1436 HFP_SoundRequest "true";
BA_ "Event" SG_ 1436 HFP_SoundRequest "true";
BA_ "Event" SG_ 1436 HFP_SoundRequest "true";
BA_ "Unavailable_Value" SG_ 1436 HFP_SoundRequest "0b11";
BA_ "Event" SG_ 1436 HFP_MapContentDisplay "true";
BA_ "Event" SG_ 1436 HFP_MapContentDisplay "true";
BA_ "Event" SG_ 1436 HFP_MapContentDisplay "true";
BA_ "Event" SG_ 1436 HFP_MapContentDisplay "true";
BA_ "Unavailable_Value" SG_ 1436 HFP_MapContentDisplay "0b111";
BA_ "Event" SG_ 1436 HFP_ExtendedInstrContentDisplay "true";
BA_ "Event" SG_ 1436 HFP_ExtendedInstrContentDisplay "true";
BA_ "Event" SG_ 1436 HFP_ExtendedInstrContentDisplay "true";
BA_ "Event" SG_ 1436 HFP_ExtendedInstrContentDisplay "true";
BA_ "Unavailable_Value" SG_ 1436 HFP_ExtendedInstrContentDisplay "0x1F";
BA_ "Event" SG_ 1436 DetectedSlotRight_Suitable "true";
BA_ "Event" SG_ 1436 DetectedSlotRight_Suitable "true";
BA_ "Event" SG_ 1436 DetectedSlotRight_Suitable "true";
BA_ "Event" SG_ 1436 DetectedSlotRight_Suitable "true";
BA_ "Unavailable_Value" SG_ 1436 DetectedSlotRight_Suitable "0b0";
BA_ "Event" SG_ 1436 DetectedSlotRight_Selection "true";
BA_ "Event" SG_ 1436 DetectedSlotRight_Selection "true";
BA_ "Event" SG_ 1436 DetectedSlotRight_Selection "true";
BA_ "Event" SG_ 1436 DetectedSlotRight_Selection "true";
BA_ "Unavailable_Value" SG_ 1436 DetectedSlotRight_Selection "0b0";
BA_ "Event" SG_ 1436 DetectedSlotLeft_Suitable "true";
BA_ "Event" SG_ 1436 DetectedSlotLeft_Suitable "true";
BA_ "Event" SG_ 1436 DetectedSlotLeft_Suitable "true";
BA_ "Event" SG_ 1436 DetectedSlotLeft_Suitable "true";
BA_ "Unavailable_Value" SG_ 1436 DetectedSlotLeft_Suitable "0b0";
BA_ "Event" SG_ 1436 ScanningSide "true";
BA_ "Event" SG_ 1436 ScanningSide "true";
BA_ "Event" SG_ 1436 ScanningSide "true";
BA_ "Event" SG_ 1436 ScanningSide "true";
BA_ "Unavailable_Value" SG_ 1436 ScanningSide "0b11";
BA_ "Unavailable_Value" SG_ 1443 AuxConsumption_LastTrip "0xFFF";
BA_ "Unavailable_Value" SG_ 1443 AverageConsumptionZEV_LastTrip "0x3FF";
BA_ "Unavailable_Value" SG_ 1443 VehicleAutonomyZEVdisplay "0x3FF";
BA_ "Unavailable_Value" SG_ 1443 FreeDistanceZEV_LastTrip "0x1FFF";
BA_ "Event" SG_ 1443 VehicleAutonomyHEVdisplay "true";
BA_ "Event" SG_ 1443 VehicleAutonomyHEVdisplay "true";
BA_ "Event" SG_ 1443 VehicleAutonomyHEVdisplay "true";
BA_ "Event" SG_ 1443 VehicleAutonomyHEVdisplay "true";
BA_ "Unavailable_Value" SG_ 1443 VehicleAutonomyHEVdisplay "0x3FF";
BA_ "Event" SG_ 1444 HUD_EffectiveDeployment "true";
BA_ "Event" SG_ 1444 HUD_EffectiveDeployment "true";
BA_ "Event" SG_ 1444 HUD_EffectiveDeployment "true";
BA_ "Event" SG_ 1444 HUD_EffectiveDeployment "true";
BA_ "Unavailable_Value" SG_ 1444 HUD_EffectiveDeployment "0b0";
BA_ "Event" SG_ 1444 HUD_TSRactivationState "true";
BA_ "Event" SG_ 1444 HUD_TSRactivationState "true";
BA_ "Event" SG_ 1444 HUD_TSRactivationState "true";
BA_ "Event" SG_ 1444 HUD_TSRactivationState "true";
BA_ "Unavailable_Value" SG_ 1444 HUD_TSRactivationState "0b00";
BA_ "Event" SG_ 1444 HUD_PositionState "true";
BA_ "Event" SG_ 1444 HUD_PositionState "true";
BA_ "Event" SG_ 1444 HUD_PositionState "true";
BA_ "Event" SG_ 1444 HUD_PositionState "true";
BA_ "Unavailable_Value" SG_ 1444 HUD_PositionState "0x00";
BA_ "Event" SG_ 1444 HUD_ActivationState "true";
BA_ "Event" SG_ 1444 HUD_ActivationState "true";
BA_ "Event" SG_ 1444 HUD_ActivationState "true";
BA_ "Event" SG_ 1444 HUD_ActivationState "true";
BA_ "Unavailable_Value" SG_ 1444 HUD_ActivationState "0b00";
BA_ "Event" SG_ 1444 HUD_ADASactivationState "true";
BA_ "Event" SG_ 1444 HUD_ADASactivationState "true";
BA_ "Event" SG_ 1444 HUD_ADASactivationState "true";
BA_ "Event" SG_ 1444 HUD_ADASactivationState "true";
BA_ "Unavailable_Value" SG_ 1444 HUD_ADASactivationState "0b00";
BA_ "Event" SG_ 1444 HUD_TurnByTurnActivationState "true";
BA_ "Event" SG_ 1444 HUD_TurnByTurnActivationState "true";
BA_ "Event" SG_ 1444 HUD_TurnByTurnActivationState "true";
BA_ "Event" SG_ 1444 HUD_TurnByTurnActivationState "true";
BA_ "Unavailable_Value" SG_ 1444 HUD_TurnByTurnActivationState "0b00";
BA_ "Event" SG_ 1444 HUD_DayLuminosityState "true";
BA_ "Event" SG_ 1444 HUD_DayLuminosityState "true";
BA_ "Event" SG_ 1444 HUD_DayLuminosityState "true";
BA_ "Event" SG_ 1444 HUD_DayLuminosityState "true";
BA_ "Unavailable_Value" SG_ 1444 HUD_DayLuminosityState "0x00";
BA_ "Event" SG_ 1444 HUD_AutoDimmingState "true";
BA_ "Event" SG_ 1444 HUD_AutoDimmingState "true";
BA_ "Event" SG_ 1444 HUD_AutoDimmingState "true";
BA_ "Event" SG_ 1444 HUD_AutoDimmingState "true";
BA_ "Unavailable_Value" SG_ 1444 HUD_AutoDimmingState "0b1";
BA_ "Event" SG_ 1444 HUD_NightLuminosityState "true";
BA_ "Event" SG_ 1444 HUD_NightLuminosityState "true";
BA_ "Event" SG_ 1444 HUD_NightLuminosityState "true";
BA_ "Event" SG_ 1444 HUD_NightLuminosityState "true";
BA_ "Unavailable_Value" SG_ 1444 HUD_NightLuminosityState "0x00";
BA_ "Event" SG_ 1446 StorageFormatStatus "true";
BA_ "Event" SG_ 1446 StorageFormatStatus "true";
BA_ "Event" SG_ 1446 StorageFormatStatus "true";
BA_ "Unavailable_Value" SG_ 1446 StorageFormatStatus "0b00";
BA_ "Event" SG_ 1447 StorageSpaceUserEventStatus "true";
BA_ "Event" SG_ 1447 StorageSpaceUserEventStatus "true";
BA_ "Event" SG_ 1447 StorageSpaceUserEventStatus "true";
BA_ "Event" SG_ 1447 StorageSpaceUserEventStatus "true";
BA_ "Unavailable_Value" SG_ 1447 StorageSpaceUserEventStatus "0x1FF";
BA_ "Event" SG_ 1447 SR_LocationInfoRecordState "true";
BA_ "Event" SG_ 1447 SR_LocationInfoRecordState "true";
BA_ "Event" SG_ 1447 SR_LocationInfoRecordState "true";
BA_ "Event" SG_ 1447 SR_LocationInfoRecordState "true";
BA_ "Unavailable_Value" SG_ 1447 SR_LocationInfoRecordState "0b1";
BA_ "Event" SG_ 1447 SR_CustomerRecordStatus "true";
BA_ "Event" SG_ 1447 SR_CustomerRecordStatus "true";
BA_ "Event" SG_ 1447 SR_CustomerRecordStatus "true";
BA_ "Event" SG_ 1447 SR_CustomerRecordStatus "true";
BA_ "Unavailable_Value" SG_ 1447 SR_CustomerRecordStatus "0b00";
BA_ "Event" SG_ 1447 SR_ShockSensitivityState "true";
BA_ "Event" SG_ 1447 SR_ShockSensitivityState "true";
BA_ "Event" SG_ 1447 SR_ShockSensitivityState "true";
BA_ "Event" SG_ 1447 SR_ShockSensitivityState "true";
BA_ "Unavailable_Value" SG_ 1447 SR_ShockSensitivityState "0b01";
BA_ "Event" SG_ 1447 SR_SoundRecordState "true";
BA_ "Event" SG_ 1447 SR_SoundRecordState "true";
BA_ "Event" SG_ 1447 SR_SoundRecordState "true";
BA_ "Event" SG_ 1447 SR_SoundRecordState "true";
BA_ "Unavailable_Value" SG_ 1447 SR_SoundRecordState "0b0";
BA_ "Event" SG_ 1447 SR_DrivingInfoRecordState "true";
BA_ "Event" SG_ 1447 SR_DrivingInfoRecordState "true";
BA_ "Event" SG_ 1447 SR_DrivingInfoRecordState "true";
BA_ "Event" SG_ 1447 SR_DrivingInfoRecordState "true";
BA_ "Unavailable_Value" SG_ 1447 SR_DrivingInfoRecordState "0b1";
BA_ "Event" SG_ 1447 StorageUsedUserEventStatus "true";
BA_ "Event" SG_ 1447 StorageUsedUserEventStatus "true";
BA_ "Event" SG_ 1447 StorageUsedUserEventStatus "true";
BA_ "Event" SG_ 1447 StorageUsedUserEventStatus "true";
BA_ "Unavailable_Value" SG_ 1447 StorageUsedUserEventStatus "0x1FF";
BA_ "Event" SG_ 1447 StorageSpaceAutomaticEventStatus "true";
BA_ "Event" SG_ 1447 StorageSpaceAutomaticEventStatus "true";
BA_ "Event" SG_ 1447 StorageSpaceAutomaticEventStatus "true";
BA_ "Event" SG_ 1447 StorageSpaceAutomaticEventStatus "true";
BA_ "Unavailable_Value" SG_ 1447 StorageSpaceAutomaticEventStatus "0x1FF";
BA_ "Event" SG_ 1447 StorageUsedAutomaticEventStatus "true";
BA_ "Event" SG_ 1447 StorageUsedAutomaticEventStatus "true";
BA_ "Event" SG_ 1447 StorageUsedAutomaticEventStatus "true";
BA_ "Event" SG_ 1447 StorageUsedAutomaticEventStatus "true";
BA_ "Unavailable_Value" SG_ 1447 StorageUsedAutomaticEventStatus "0x1FF";
BA_ "Event" SG_ 1447 StorageSpaceContinuousStatus "true";
BA_ "Event" SG_ 1447 StorageSpaceContinuousStatus "true";
BA_ "Event" SG_ 1447 StorageSpaceContinuousStatus "true";
BA_ "Event" SG_ 1447 StorageSpaceContinuousStatus "true";
BA_ "Unavailable_Value" SG_ 1447 StorageSpaceContinuousStatus "0x1FF";
BA_ "Event" SG_ 1447 StorageUsedContinuousStatus "true";
BA_ "Event" SG_ 1447 StorageUsedContinuousStatus "true";
BA_ "Event" SG_ 1447 StorageUsedContinuousStatus "true";
BA_ "Event" SG_ 1447 StorageUsedContinuousStatus "true";
BA_ "Unavailable_Value" SG_ 1447 StorageUsedContinuousStatus "0x1FF";
BA_ "Event" SG_ 1447 SR_CustomerRecordLengthState "true";
BA_ "Event" SG_ 1447 SR_CustomerRecordLengthState "true";
BA_ "Event" SG_ 1447 SR_CustomerRecordLengthState "true";
BA_ "Event" SG_ 1447 SR_CustomerRecordLengthState "true";
BA_ "Unavailable_Value" SG_ 1447 SR_CustomerRecordLengthState "0b00";
BA_ "Event" SG_ 1448 ParkEndPositionLongitude "true";
BA_ "Event" SG_ 1448 ParkEndPositionLongitude "true";
BA_ "Event" SG_ 1448 ParkEndPositionLongitude "true";
BA_ "Event" SG_ 1448 ParkEndPositionLongitude "true";
BA_ "Unavailable_Value" SG_ 1448 ParkEndPositionLongitude "0x1FFFFFFF";
BA_ "Event" SG_ 1448 ParkEndPositionLatitude "true";
BA_ "Event" SG_ 1448 ParkEndPositionLatitude "true";
BA_ "Event" SG_ 1448 ParkEndPositionLatitude "true";
BA_ "Event" SG_ 1448 ParkEndPositionLatitude "true";
BA_ "Unavailable_Value" SG_ 1448 ParkEndPositionLatitude "0xFFFFFFF";
BA_ "Event" SG_ 1449 ClimFrontDefrostPush "true";
BA_ "Event" SG_ 1449 ClimFrontDefrostPush "true";
BA_ "Event" SG_ 1449 ClimFrontDefrostPush "true";
BA_ "Event" SG_ 1449 ClimFrontDefrostPush "true";
BA_ "Unavailable_Value" SG_ 1449 ClimFrontDefrostPush "0b0";
BA_ "Event" SG_ 1449 ClimRearDefrostPush "true";
BA_ "Event" SG_ 1449 ClimRearDefrostPush "true";
BA_ "Event" SG_ 1449 ClimRearDefrostPush "true";
BA_ "Event" SG_ 1449 ClimRearDefrostPush "true";
BA_ "Unavailable_Value" SG_ 1449 ClimRearDefrostPush "0b0";
BA_ "Event" SG_ 1449 SecondRowLeftSeatAutoPush "true";
BA_ "Event" SG_ 1449 SecondRowLeftSeatAutoPush "true";
BA_ "Event" SG_ 1449 SecondRowLeftSeatAutoPush "true";
BA_ "Event" SG_ 1449 SecondRowLeftSeatAutoPush "true";
BA_ "Unavailable_Value" SG_ 1449 SecondRowLeftSeatAutoPush "0b0";
BA_ "Event" SG_ 1449 SecondRowRightSeatAutoPush "true";
BA_ "Event" SG_ 1449 SecondRowRightSeatAutoPush "true";
BA_ "Event" SG_ 1449 SecondRowRightSeatAutoPush "true";
BA_ "Event" SG_ 1449 SecondRowRightSeatAutoPush "true";
BA_ "Unavailable_Value" SG_ 1449 SecondRowRightSeatAutoPush "0b0";
BA_ "Event" SG_ 1449 ThirdRowLeftSeatAutoPush "true";
BA_ "Event" SG_ 1449 ThirdRowLeftSeatAutoPush "true";
BA_ "Event" SG_ 1449 ThirdRowLeftSeatAutoPush "true";
BA_ "Event" SG_ 1449 ThirdRowLeftSeatAutoPush "true";
BA_ "Unavailable_Value" SG_ 1449 ThirdRowLeftSeatAutoPush "0b0";
BA_ "Event" SG_ 1449 ThirdRowRightSeatAutoPush "true";
BA_ "Event" SG_ 1449 ThirdRowRightSeatAutoPush "true";
BA_ "Event" SG_ 1449 ThirdRowRightSeatAutoPush "true";
BA_ "Event" SG_ 1449 ThirdRowRightSeatAutoPush "true";
BA_ "Unavailable_Value" SG_ 1449 ThirdRowRightSeatAutoPush "0b0";
BA_ "Event" SG_ 1449 ClimHeatedSteeringWheelPush "true";
BA_ "Event" SG_ 1449 ClimHeatedSteeringWheelPush "true";
BA_ "Event" SG_ 1449 ClimHeatedSteeringWheelPush "true";
BA_ "Event" SG_ 1449 ClimHeatedSteeringWheelPush "true";
BA_ "Unavailable_Value" SG_ 1449 ClimHeatedSteeringWheelPush "0b0";
BA_ "Event" SG_ 1449 ClimHeatedSteeringWheelAutoPush "true";
BA_ "Event" SG_ 1449 ClimHeatedSteeringWheelAutoPush "true";
BA_ "Event" SG_ 1449 ClimHeatedSteeringWheelAutoPush "true";
BA_ "Event" SG_ 1449 ClimHeatedSteeringWheelAutoPush "true";
BA_ "Unavailable_Value" SG_ 1449 ClimHeatedSteeringWheelAutoPush "0b0";
BA_ "Event" SG_ 1449 ClimRearLeftTempRequest "true";
BA_ "Event" SG_ 1449 ClimRearLeftTempRequest "true";
BA_ "Event" SG_ 1449 ClimRearLeftTempRequest "true";
BA_ "Event" SG_ 1449 ClimRearLeftTempRequest "true";
BA_ "Unavailable_Value" SG_ 1449 ClimRearLeftTempRequest "0x1FF";
BA_ "Event" SG_ 1449 ClimRearRightTempRequest "true";
BA_ "Event" SG_ 1449 ClimRearRightTempRequest "true";
BA_ "Event" SG_ 1449 ClimRearRightTempRequest "true";
BA_ "Event" SG_ 1449 ClimRearRightTempRequest "true";
BA_ "Unavailable_Value" SG_ 1449 ClimRearRightTempRequest "0x1FF";
BA_ "Event" SG_ 1449 ClimRearRightFlowDistrVentPush "true";
BA_ "Event" SG_ 1449 ClimRearRightFlowDistrVentPush "true";
BA_ "Event" SG_ 1449 ClimRearRightFlowDistrVentPush "true";
BA_ "Event" SG_ 1449 ClimRearRightFlowDistrVentPush "true";
BA_ "Unavailable_Value" SG_ 1449 ClimRearRightFlowDistrVentPush "0b0";
BA_ "Event" SG_ 1449 ClimRearLeftFlowDistrVentPush "true";
BA_ "Event" SG_ 1449 ClimRearLeftFlowDistrVentPush "true";
BA_ "Event" SG_ 1449 ClimRearLeftFlowDistrVentPush "true";
BA_ "Event" SG_ 1449 ClimRearLeftFlowDistrVentPush "true";
BA_ "Unavailable_Value" SG_ 1449 ClimRearLeftFlowDistrVentPush "0b0";
BA_ "Event" SG_ 1449 ClimRearRightFlowDistrDefPush "true";
BA_ "Event" SG_ 1449 ClimRearRightFlowDistrDefPush "true";
BA_ "Event" SG_ 1449 ClimRearRightFlowDistrDefPush "true";
BA_ "Event" SG_ 1449 ClimRearRightFlowDistrDefPush "true";
BA_ "Unavailable_Value" SG_ 1449 ClimRearRightFlowDistrDefPush "0b0";
BA_ "Event" SG_ 1449 ClimRearLeftFlowDistrDefPush "true";
BA_ "Event" SG_ 1449 ClimRearLeftFlowDistrDefPush "true";
BA_ "Event" SG_ 1449 ClimRearLeftFlowDistrDefPush "true";
BA_ "Event" SG_ 1449 ClimRearLeftFlowDistrDefPush "true";
BA_ "Unavailable_Value" SG_ 1449 ClimRearLeftFlowDistrDefPush "0b0";
BA_ "Event" SG_ 1449 ClimRearRightSyncPush "true";
BA_ "Event" SG_ 1449 ClimRearRightSyncPush "true";
BA_ "Event" SG_ 1449 ClimRearRightSyncPush "true";
BA_ "Event" SG_ 1449 ClimRearRightSyncPush "true";
BA_ "Unavailable_Value" SG_ 1449 ClimRearRightSyncPush "0b0";
BA_ "Event" SG_ 1449 ClimRearLeftSyncPush "true";
BA_ "Event" SG_ 1449 ClimRearLeftSyncPush "true";
BA_ "Event" SG_ 1449 ClimRearLeftSyncPush "true";
BA_ "Event" SG_ 1449 ClimRearLeftSyncPush "true";
BA_ "Unavailable_Value" SG_ 1449 ClimRearLeftSyncPush "0b0";
BA_ "Event" SG_ 1449 ClimLinkPriorityHeatStrgAutoReq "true";
BA_ "Event" SG_ 1449 ClimLinkPriorityHeatStrgAutoReq "true";
BA_ "Event" SG_ 1449 ClimLinkPriorityHeatStrgAutoReq "true";
BA_ "Event" SG_ 1449 ClimLinkPriorityHeatStrgAutoReq "true";
BA_ "Unavailable_Value" SG_ 1449 ClimLinkPriorityHeatStrgAutoReq "0b000";
BA_ "Event" SG_ 1449 ClimRearRightAutoNormalPush "true";
BA_ "Event" SG_ 1449 ClimRearRightAutoNormalPush "true";
BA_ "Event" SG_ 1449 ClimRearRightAutoNormalPush "true";
BA_ "Event" SG_ 1449 ClimRearRightAutoNormalPush "true";
BA_ "Unavailable_Value" SG_ 1449 ClimRearRightAutoNormalPush "0b0";
BA_ "Event" SG_ 1449 ClimRearLeftAutoNormalPush "true";
BA_ "Event" SG_ 1449 ClimRearLeftAutoNormalPush "true";
BA_ "Event" SG_ 1449 ClimRearLeftAutoNormalPush "true";
BA_ "Event" SG_ 1449 ClimRearLeftAutoNormalPush "true";
BA_ "Unavailable_Value" SG_ 1449 ClimRearLeftAutoNormalPush "0b0";
BA_ "Event" SG_ 1449 ClimRearACPush "true";
BA_ "Event" SG_ 1449 ClimRearACPush "true";
BA_ "Event" SG_ 1449 ClimRearACPush "true";
BA_ "Event" SG_ 1449 ClimRearACPush "true";
BA_ "Unavailable_Value" SG_ 1449 ClimRearACPush "0b0";
BA_ "Event" SG_ 1449 ClimRearRightFlowDistrFeetPush "true";
BA_ "Event" SG_ 1449 ClimRearRightFlowDistrFeetPush "true";
BA_ "Event" SG_ 1449 ClimRearRightFlowDistrFeetPush "true";
BA_ "Event" SG_ 1449 ClimRearRightFlowDistrFeetPush "true";
BA_ "Unavailable_Value" SG_ 1449 ClimRearRightFlowDistrFeetPush "0b0";
BA_ "Event" SG_ 1449 ClimRearLeftFlowDistrFeetPush "true";
BA_ "Event" SG_ 1449 ClimRearLeftFlowDistrFeetPush "true";
BA_ "Event" SG_ 1449 ClimRearLeftFlowDistrFeetPush "true";
BA_ "Event" SG_ 1449 ClimRearLeftFlowDistrFeetPush "true";
BA_ "Unavailable_Value" SG_ 1449 ClimRearLeftFlowDistrFeetPush "0b0";
BA_ "Event" SG_ 1449 ClimFPrearLeftBlowingRequest "true";
BA_ "Event" SG_ 1449 ClimFPrearLeftBlowingRequest "true";
BA_ "Event" SG_ 1449 ClimFPrearLeftBlowingRequest "true";
BA_ "Event" SG_ 1449 ClimFPrearLeftBlowingRequest "true";
BA_ "Unavailable_Value" SG_ 1449 ClimFPrearLeftBlowingRequest "0b0000";
BA_ "Event" SG_ 1449 ClimFPrearRightBlowingRequest "true";
BA_ "Event" SG_ 1449 ClimFPrearRightBlowingRequest "true";
BA_ "Event" SG_ 1449 ClimFPrearRightBlowingRequest "true";
BA_ "Event" SG_ 1449 ClimFPrearRightBlowingRequest "true";
BA_ "Unavailable_Value" SG_ 1449 ClimFPrearRightBlowingRequest "0b0000";
BA_ "Event" SG_ 1449 ClimACmaxPush "true";
BA_ "Event" SG_ 1449 ClimACmaxPush "true";
BA_ "Event" SG_ 1449 ClimACmaxPush "true";
BA_ "Event" SG_ 1449 ClimACmaxPush "true";
BA_ "Unavailable_Value" SG_ 1449 VisionMexMode "0b1111";
BA_ "Event" SG_ 1450 StorageTotalVolume "true";
BA_ "Event" SG_ 1450 StorageTotalVolume "true";
BA_ "Event" SG_ 1450 StorageTotalVolume "true";
BA_ "Event" SG_ 1450 StorageTotalVolume "true";
BA_ "Unavailable_Value" SG_ 1450 StorageTotalVolume "0x1FF";
BA_ "Event" SG_ 1450 SR_SystemStatus "true";
BA_ "Event" SG_ 1450 SR_SystemStatus "true";
BA_ "Event" SG_ 1450 SR_SystemStatus "true";
BA_ "Event" SG_ 1450 SR_SystemStatus "true";
BA_ "Unavailable_Value" SG_ 1450 SR_SystemStatus "0b0";
BA_ "Event" SG_ 1450 StorageStatusDisplay "true";
BA_ "Event" SG_ 1450 StorageStatusDisplay "true";
BA_ "Event" SG_ 1450 StorageStatusDisplay "true";
BA_ "Event" SG_ 1450 StorageStatusDisplay "true";
BA_ "Unavailable_Value" SG_ 1450 StorageStatusDisplay "0b00";
BA_ "Event" SG_ 1450 SR_ContinuousRecordLengthState "true";
BA_ "Event" SG_ 1450 SR_ContinuousRecordLengthState "true";
BA_ "Event" SG_ 1450 SR_ContinuousRecordLengthState "true";
BA_ "Event" SG_ 1450 SR_ContinuousRecordLengthState "true";
BA_ "Unavailable_Value" SG_ 1450 SR_ContinuousRecordLengthState "0b00";
BA_ "Event" SG_ 1450 SR_AutomaticRecordStatus "true";
BA_ "Event" SG_ 1450 SR_AutomaticRecordStatus "true";
BA_ "Event" SG_ 1450 SR_AutomaticRecordStatus "true";
BA_ "Event" SG_ 1450 SR_AutomaticRecordStatus "true";
BA_ "Unavailable_Value" SG_ 1450 SR_AutomaticRecordStatus "0b00";
BA_ "Event" SG_ 1450 StorageFreeUserEventStatus "true";
BA_ "Event" SG_ 1450 StorageFreeUserEventStatus "true";
BA_ "Event" SG_ 1450 StorageFreeUserEventStatus "true";
BA_ "Event" SG_ 1450 StorageFreeUserEventStatus "true";
BA_ "Unavailable_Value" SG_ 1450 StorageFreeUserEventStatus "0x1FF";
BA_ "Event" SG_ 1450 StorageRatioContinuousStatus "true";
BA_ "Event" SG_ 1450 StorageRatioContinuousStatus "true";
BA_ "Event" SG_ 1450 StorageRatioContinuousStatus "true";
BA_ "Event" SG_ 1450 StorageRatioContinuousStatus "true";
BA_ "Unavailable_Value" SG_ 1450 StorageRatioContinuousStatus "0x7F";
BA_ "Event" SG_ 1450 StorageFreeContinuousStatus "true";
BA_ "Event" SG_ 1450 StorageFreeContinuousStatus "true";
BA_ "Event" SG_ 1450 StorageFreeContinuousStatus "true";
BA_ "Event" SG_ 1450 StorageFreeContinuousStatus "true";
BA_ "Unavailable_Value" SG_ 1450 StorageFreeContinuousStatus "0x1FF";
BA_ "Event" SG_ 1450 StorageRatioAutomaticEventStatus "true";
BA_ "Event" SG_ 1450 StorageRatioAutomaticEventStatus "true";
BA_ "Event" SG_ 1450 StorageRatioAutomaticEventStatus "true";
BA_ "Event" SG_ 1450 StorageRatioAutomaticEventStatus "true";
BA_ "Unavailable_Value" SG_ 1450 StorageRatioAutomaticEventStatus "0x7F";
BA_ "Event" SG_ 1450 StorageFreeAutomaticEventStatus "true";
BA_ "Event" SG_ 1450 StorageFreeAutomaticEventStatus "true";
BA_ "Event" SG_ 1450 StorageFreeAutomaticEventStatus "true";
BA_ "Event" SG_ 1450 StorageFreeAutomaticEventStatus "true";
BA_ "Unavailable_Value" SG_ 1450 StorageFreeAutomaticEventStatus "0x1FF";
BA_ "Event" SG_ 1450 StorageRatioUserEventStatus "true";
BA_ "Event" SG_ 1450 StorageRatioUserEventStatus "true";
BA_ "Event" SG_ 1450 StorageRatioUserEventStatus "true";
BA_ "Event" SG_ 1450 StorageRatioUserEventStatus "true";
BA_ "Unavailable_Value" SG_ 1450 StorageRatioUserEventStatus "0x7F";
BA_ "Event" SG_ 1457 AmbientLightingArea3Status "true";
BA_ "Event" SG_ 1457 AmbientLightingArea3Status "true";
BA_ "Event" SG_ 1457 AmbientLightingArea3Status "true";
BA_ "Event" SG_ 1457 AmbientLightingArea3Status "true";
BA_ "Unavailable_Value" SG_ 1457 AmbientLightingArea3Status "null";
BA_ "Event" SG_ 1457 AmbientLightingArea2Status "true";
BA_ "Event" SG_ 1457 AmbientLightingArea2Status "true";
BA_ "Event" SG_ 1457 AmbientLightingArea2Status "true";
BA_ "Event" SG_ 1457 AmbientLightingArea2Status "true";
BA_ "Unavailable_Value" SG_ 1457 AmbientLightingArea2Status "null";
BA_ "Event" SG_ 1457 AmbientLightingActivationStatus "true";
BA_ "Event" SG_ 1457 AmbientLightingActivationStatus "true";
BA_ "Event" SG_ 1457 AmbientLightingActivationStatus "true";
BA_ "Event" SG_ 1457 AmbientLightingActivationStatus "true";
BA_ "Unavailable_Value" SG_ 1457 AmbientLightingActivationStatus "null";
BA_ "Event" SG_ 1457 AmbientLightNightIntensityStatus "true";
BA_ "Event" SG_ 1457 AmbientLightNightIntensityStatus "true";
BA_ "Event" SG_ 1457 AmbientLightNightIntensityStatus "true";
BA_ "Event" SG_ 1457 AmbientLightNightIntensityStatus "true";
BA_ "Unavailable_Value" SG_ 1457 AmbientLightNightIntensityStatus "0x1F";
BA_ "Event" SG_ 1457 AmbientLightingArea1Status "true";
BA_ "Event" SG_ 1457 AmbientLightingArea1Status "true";
BA_ "Event" SG_ 1457 AmbientLightingArea1Status "true";
BA_ "Event" SG_ 1457 AmbientLightingArea1Status "true";
BA_ "Unavailable_Value" SG_ 1457 AmbientLightingArea1Status "null";
BA_ "Event" SG_ 1457 AmbientLightDayIntensityStatus "true";
BA_ "Event" SG_ 1457 AmbientLightDayIntensityStatus "true";
BA_ "Event" SG_ 1457 AmbientLightDayIntensityStatus "true";
BA_ "Event" SG_ 1457 AmbientLightDayIntensityStatus "true";
BA_ "Unavailable_Value" SG_ 1457 AmbientLightDayIntensityStatus "0x1F";
BA_ "Event" SG_ 1458 PnCHEVCactivationStatus "true";
BA_ "Event" SG_ 1458 PnCHEVCactivationStatus "true";
BA_ "Event" SG_ 1458 PnCHEVCactivationStatus "true";
BA_ "Event" SG_ 1458 PnCHEVCactivationStatus "true";
BA_ "Unavailable_Value" SG_ 1458 PnCHEVCactivationStatus "0b11";
BA_ "Event" SG_ 1459 MOD_ActivationState "true";
BA_ "Event" SG_ 1459 MOD_ActivationState "true";
BA_ "Event" SG_ 1459 MOD_ActivationState "true";
BA_ "Event" SG_ 1459 MOD_ActivationState "true";
BA_ "Unavailable_Value" SG_ 1459 MOD_ActivationState "0b0";
BA_ "Event" SG_ 1459 AVM_SoundType "true";
BA_ "Event" SG_ 1459 AVM_SoundType "true";
BA_ "Event" SG_ 1459 AVM_SoundType "true";
BA_ "Event" SG_ 1459 AVM_SoundType "true";
BA_ "Unavailable_Value" SG_ 1459 AVM_SoundType "0b0";
BA_ "Event" SG_ 1459 AVM_SoundRequest "true";
BA_ "Event" SG_ 1459 AVM_SoundRequest "true";
BA_ "Event" SG_ 1459 AVM_SoundRequest "true";
BA_ "Event" SG_ 1459 AVM_SoundRequest "true";
BA_ "Unavailable_Value" SG_ 1459 AVM_SoundRequest "0b0";
BA_ "Event" SG_ 1459 MOD_SoundAlertRequest_IVI "true";
BA_ "Event" SG_ 1459 MOD_SoundAlertRequest_IVI "true";
BA_ "Event" SG_ 1459 MOD_SoundAlertRequest_IVI "true";
BA_ "Event" SG_ 1459 MOD_SoundAlertRequest_IVI "true";
BA_ "Unavailable_Value" SG_ 1459 MOD_SoundAlertRequest_IVI "0b0";
BA_ "Event" SG_ 1459 AVM_InitializationState "true";
BA_ "Event" SG_ 1459 AVM_InitializationState "true";
BA_ "Event" SG_ 1459 AVM_InitializationState "true";
BA_ "Event" SG_ 1459 AVM_InitializationState "true";
BA_ "Unavailable_Value" SG_ 1459 AVM_InitializationState "0b0";
BA_ "Event" SG_ 1459 AVM_DisplayRequest "true";
BA_ "Event" SG_ 1459 AVM_DisplayRequest "true";
BA_ "Event" SG_ 1459 AVM_DisplayRequest "true";
BA_ "Event" SG_ 1459 AVM_DisplayRequest "true";
BA_ "Unavailable_Value" SG_ 1459 AVM_DisplayRequest "0b0";
BA_ "Event" SG_ 1459 AVM_LayoutVideoStatus "true";
BA_ "Event" SG_ 1459 AVM_LayoutVideoStatus "true";
BA_ "Event" SG_ 1459 AVM_LayoutVideoStatus "true";
BA_ "Event" SG_ 1459 AVM_LayoutVideoStatus "true";
BA_ "Unavailable_Value" SG_ 1459 AVM_LayoutVideoStatus "0x0";
BA_ "Event" SG_ 1459 AVM_ClosingAuthorization "true";
BA_ "Event" SG_ 1459 AVM_ClosingAuthorization "true";
BA_ "Event" SG_ 1459 AVM_ClosingAuthorization "true";
BA_ "Event" SG_ 1459 AVM_ClosingAuthorization "true";
BA_ "Unavailable_Value" SG_ 1459 AVM_ClosingAuthorization "0b0";
BA_ "Event" SG_ 1459 AVM_LayoutDisplayRequest "true";
BA_ "Event" SG_ 1459 AVM_LayoutDisplayRequest "true";
BA_ "Event" SG_ 1459 AVM_LayoutDisplayRequest "true";
BA_ "Event" SG_ 1459 AVM_LayoutDisplayRequest "true";
BA_ "Unavailable_Value" SG_ 1459 AVM_LayoutDisplayRequest "0x00";
BA_ "Event" SG_ 1462 ClimRearLeftTempDisplay "true";
BA_ "Event" SG_ 1462 ClimRearLeftTempDisplay "true";
BA_ "Event" SG_ 1462 ClimRearLeftTempDisplay "true";
BA_ "Event" SG_ 1462 ClimRearLeftTempDisplay "true";
BA_ "Unavailable_Value" SG_ 1462 ClimRearLeftTempDisplay "0x000";
BA_ "Event" SG_ 1462 ClimFrontDefrostDisplayStatus "true";
BA_ "Event" SG_ 1462 ClimFrontDefrostDisplayStatus "true";
BA_ "Event" SG_ 1462 ClimFrontDefrostDisplayStatus "true";
BA_ "Event" SG_ 1462 ClimFrontDefrostDisplayStatus "true";
BA_ "Unavailable_Value" SG_ 1462 ClimFrontDefrostDisplayStatus "0b0";
BA_ "Event" SG_ 1462 ClimHeatedSteerWheelDispStatus "true";
BA_ "Event" SG_ 1462 ClimHeatedSteerWheelDispStatus "true";
BA_ "Event" SG_ 1462 ClimHeatedSteerWheelDispStatus "true";
BA_ "Event" SG_ 1462 ClimHeatedSteerWheelDispStatus "true";
BA_ "Unavailable_Value" SG_ 1462 ClimHeatedSteerWheelDispStatus "0b0";
BA_ "Event" SG_ 1462 ClimRearLeftTempDisplayStatus "true";
BA_ "Event" SG_ 1462 ClimRearLeftTempDisplayStatus "true";
BA_ "Event" SG_ 1462 ClimRearLeftTempDisplayStatus "true";
BA_ "Event" SG_ 1462 ClimRearLeftTempDisplayStatus "true";
BA_ "Unavailable_Value" SG_ 1462 ClimRearLeftTempDisplayStatus "0b0";
BA_ "Event" SG_ 1462 ClimHeatedSteerWheelAutoDisplay "true";
BA_ "Event" SG_ 1462 ClimHeatedSteerWheelAutoDisplay "true";
BA_ "Event" SG_ 1462 ClimHeatedSteerWheelAutoDisplay "true";
BA_ "Event" SG_ 1462 ClimHeatedSteerWheelAutoDisplay "true";
BA_ "Unavailable_Value" SG_ 1462 ClimHeatedSteerWheelAutoDisplay "0b00";
BA_ "Event" SG_ 1462 ClimFrontDefrostDisplay "true";
BA_ "Event" SG_ 1462 ClimFrontDefrostDisplay "true";
BA_ "Event" SG_ 1462 ClimFrontDefrostDisplay "true";
BA_ "Event" SG_ 1462 ClimFrontDefrostDisplay "true";
BA_ "Unavailable_Value" SG_ 1462 ClimFrontDefrostDisplay "0b00";
BA_ "Event" SG_ 1462 ClimRearRightTempDisplay "true";
BA_ "Event" SG_ 1462 ClimRearRightTempDisplay "true";
BA_ "Event" SG_ 1462 ClimRearRightTempDisplay "true";
BA_ "Event" SG_ 1462 ClimRearRightTempDisplay "true";
BA_ "Unavailable_Value" SG_ 1462 ClimRearRightTempDisplay "0x000";
BA_ "Event" SG_ 1462 ClimRearRightSyncDisplayStatus "true";
BA_ "Event" SG_ 1462 ClimRearRightSyncDisplayStatus "true";
BA_ "Event" SG_ 1462 ClimRearRightSyncDisplayStatus "true";
BA_ "Event" SG_ 1462 ClimRearRightSyncDisplayStatus "true";
BA_ "Unavailable_Value" SG_ 1462 ClimRearRightSyncDisplayStatus "0b0";
BA_ "Event" SG_ 1462 ClimRearRightSyncDisplay "true";
BA_ "Event" SG_ 1462 ClimRearRightSyncDisplay "true";
BA_ "Event" SG_ 1462 ClimRearRightSyncDisplay "true";
BA_ "Event" SG_ 1462 ClimRearRightSyncDisplay "true";
BA_ "Unavailable_Value" SG_ 1462 ClimRearRightSyncDisplay "0b00";
BA_ "Event" SG_ 1462 ClimRearLeftSyncDisplayStatus "true";
BA_ "Event" SG_ 1462 ClimRearLeftSyncDisplayStatus "true";
BA_ "Event" SG_ 1462 ClimRearLeftSyncDisplayStatus "true";
BA_ "Event" SG_ 1462 ClimRearLeftSyncDisplayStatus "true";
BA_ "Unavailable_Value" SG_ 1462 ClimRearLeftSyncDisplayStatus "0b0";
BA_ "Event" SG_ 1462 ClimRearLeftSyncDisplay "true";
BA_ "Event" SG_ 1462 ClimRearLeftSyncDisplay "true";
BA_ "Event" SG_ 1462 ClimRearLeftSyncDisplay "true";
BA_ "Event" SG_ 1462 ClimRearLeftSyncDisplay "true";
BA_ "Unavailable_Value" SG_ 1462 ClimRearLeftSyncDisplay "0b00";
BA_ "Event" SG_ 1462 ClimRearRightTempDisplayStatus "true";
BA_ "Event" SG_ 1462 ClimRearRightTempDisplayStatus "true";
BA_ "Event" SG_ 1462 ClimRearRightTempDisplayStatus "true";
BA_ "Event" SG_ 1462 ClimRearRightTempDisplayStatus "true";
BA_ "Unavailable_Value" SG_ 1462 ClimRearRightTempDisplayStatus "0b0";
BA_ "Event" SG_ 1462 ClimRearRightFlowDistDispStatus "true";
BA_ "Event" SG_ 1462 ClimRearRightFlowDistDispStatus "true";
BA_ "Event" SG_ 1462 ClimRearRightFlowDistDispStatus "true";
BA_ "Event" SG_ 1462 ClimRearRightFlowDistDispStatus "true";
BA_ "Unavailable_Value" SG_ 1462 ClimRearRightFlowDistDispStatus "0b0";
BA_ "Event" SG_ 1462 ClimRearRightFlowDistrDisplay "true";
BA_ "Event" SG_ 1462 ClimRearRightFlowDistrDisplay "true";
BA_ "Event" SG_ 1462 ClimRearRightFlowDistrDisplay "true";
BA_ "Event" SG_ 1462 ClimRearRightFlowDistrDisplay "true";
BA_ "Unavailable_Value" SG_ 1462 ClimRearRightFlowDistrDisplay "0b000";
BA_ "Event" SG_ 1462 ClimRearLeftFlowDistrDispStatus "true";
BA_ "Event" SG_ 1462 ClimRearLeftFlowDistrDispStatus "true";
BA_ "Event" SG_ 1462 ClimRearLeftFlowDistrDispStatus "true";
BA_ "Event" SG_ 1462 ClimRearLeftFlowDistrDispStatus "true";
BA_ "Unavailable_Value" SG_ 1462 ClimRearLeftFlowDistrDispStatus "0b0";
BA_ "Event" SG_ 1462 ClimRearLeftFlowDistrDisplay "true";
BA_ "Event" SG_ 1462 ClimRearLeftFlowDistrDisplay "true";
BA_ "Event" SG_ 1462 ClimRearLeftFlowDistrDisplay "true";
BA_ "Event" SG_ 1462 ClimRearLeftFlowDistrDisplay "true";
BA_ "Unavailable_Value" SG_ 1462 ClimRearLeftFlowDistrDisplay "0b000";
BA_ "Event" SG_ 1462 ClimRearLeftBlowingAutoDisplay "true";
BA_ "Event" SG_ 1462 ClimRearLeftBlowingAutoDisplay "true";
BA_ "Event" SG_ 1462 ClimRearLeftBlowingAutoDisplay "true";
BA_ "Event" SG_ 1462 ClimRearLeftBlowingAutoDisplay "true";
BA_ "Unavailable_Value" SG_ 1462 ClimRearLeftBlowingAutoDisplay "0b00";
BA_ "Event" SG_ 1462 ClimRearRightBlowingAutoDisplay "true";
BA_ "Event" SG_ 1462 ClimRearRightBlowingAutoDisplay "true";
BA_ "Event" SG_ 1462 ClimRearRightBlowingAutoDisplay "true";
BA_ "Event" SG_ 1462 ClimRearRightBlowingAutoDisplay "true";
BA_ "Unavailable_Value" SG_ 1462 ClimRearRightBlowingAutoDisplay "0b00";
BA_ "Event" SG_ 1462 ClimRearRightBlowLevelDisplay "true";
BA_ "Event" SG_ 1462 ClimRearRightBlowLevelDisplay "true";
BA_ "Event" SG_ 1462 ClimRearRightBlowLevelDisplay "true";
BA_ "Event" SG_ 1462 ClimRearRightBlowLevelDisplay "true";
BA_ "Unavailable_Value" SG_ 1462 ClimRearRightBlowLevelDisplay "0b0000";
BA_ "Event" SG_ 1462 ClimRearACDisplay "true";
BA_ "Event" SG_ 1462 ClimRearACDisplay "true";
BA_ "Event" SG_ 1462 ClimRearACDisplay "true";
BA_ "Event" SG_ 1462 ClimRearACDisplay "true";
BA_ "Unavailable_Value" SG_ 1462 ClimRearACDisplay "0b00";
BA_ "Event" SG_ 1462 ClimRearRightBlowLevlDispStatus "true";
BA_ "Event" SG_ 1462 ClimRearRightBlowLevlDispStatus "true";
BA_ "Event" SG_ 1462 ClimRearRightBlowLevlDispStatus "true";
BA_ "Event" SG_ 1462 ClimRearRightBlowLevlDispStatus "true";
BA_ "Unavailable_Value" SG_ 1462 ClimRearRightBlowLevlDispStatus "0b0";
BA_ "Event" SG_ 1462 ClimRearLeftBlowLevelDispStatus "true";
BA_ "Event" SG_ 1462 ClimRearLeftBlowLevelDispStatus "true";
BA_ "Event" SG_ 1462 ClimRearLeftBlowLevelDispStatus "true";
BA_ "Event" SG_ 1462 ClimRearLeftBlowLevelDispStatus "true";
BA_ "Unavailable_Value" SG_ 1462 ClimRearLeftBlowLevelDispStatus "0b0";
BA_ "Event" SG_ 1462 ClimRearLeftBlowLevelDisplay "true";
BA_ "Event" SG_ 1462 ClimRearLeftBlowLevelDisplay "true";
BA_ "Event" SG_ 1462 ClimRearLeftBlowLevelDisplay "true";
BA_ "Event" SG_ 1462 ClimRearLeftBlowLevelDisplay "true";
BA_ "Unavailable_Value" SG_ 1462 ClimRearLeftBlowLevelDisplay "0b0000";
BA_ "Event" SG_ 1462 ClimLinkPrioritHeatStrgAutoDisp "true";
BA_ "Event" SG_ 1462 ClimLinkPrioritHeatStrgAutoDisp "true";
BA_ "Event" SG_ 1462 ClimLinkPrioritHeatStrgAutoDisp "true";
BA_ "Event" SG_ 1462 ClimLinkPrioritHeatStrgAutoDisp "true";
BA_ "Unavailable_Value" SG_ 1462 ClimLinkPrioritHeatStrgAutoDisp "0b000";
BA_ "Event" SG_ 1462 ClimRearRightAutoDisplay "true";
BA_ "Event" SG_ 1462 ClimRearRightAutoDisplay "true";
BA_ "Event" SG_ 1462 ClimRearRightAutoDisplay "true";
BA_ "Event" SG_ 1462 ClimRearRightAutoDisplay "true";
BA_ "Unavailable_Value" SG_ 1462 ClimRearRightAutoDisplay "0b00";
BA_ "Event" SG_ 1462 ClimRearLeftAutoDisplay "true";
BA_ "Event" SG_ 1462 ClimRearLeftAutoDisplay "true";
BA_ "Event" SG_ 1462 ClimRearLeftAutoDisplay "true";
BA_ "Event" SG_ 1462 ClimRearLeftAutoDisplay "true";
BA_ "Unavailable_Value" SG_ 1462 ClimRearLeftAutoDisplay "0b00";
BA_ "Event" SG_ 1462 ClimRearACDisplayStatus "true";
BA_ "Event" SG_ 1462 ClimRearACDisplayStatus "true";
BA_ "Event" SG_ 1462 ClimRearACDisplayStatus "true";
BA_ "Event" SG_ 1462 ClimRearACDisplayStatus "true";
BA_ "Unavailable_Value" SG_ 1462 ClimRearACDisplayStatus "0b0";
BA_ "Event" SG_ 1464 DriverMassageActivationReq "true";
BA_ "Event" SG_ 1464 DriverMassageActivationReq "true";
BA_ "Event" SG_ 1464 DriverMassageActivationReq "true";
BA_ "Event" SG_ 1464 DriverMassageActivationReq "true";
BA_ "Unavailable_Value" SG_ 1464 DriverMassageActivationReq "0b00";
BA_ "Event" SG_ 1464 DriverSeatMemoRecallReq "true";
BA_ "Event" SG_ 1464 DriverSeatMemoRecallReq "true";
BA_ "Event" SG_ 1464 DriverSeatMemoRecallReq "true";
BA_ "Event" SG_ 1464 DriverSeatMemoRecallReq "true";
BA_ "Unavailable_Value" SG_ 1464 DriverSeatMemoRecallReq "0b000";
BA_ "Event" SG_ 1464 DriverSeatMemoRequest "true";
BA_ "Event" SG_ 1464 DriverSeatMemoRequest "true";
BA_ "Event" SG_ 1464 DriverSeatMemoRequest "true";
BA_ "Event" SG_ 1464 DriverSeatMemoRequest "true";
BA_ "Unavailable_Value" SG_ 1464 DriverSeatMemoRequest "0b000";
BA_ "Event" SG_ 1464 DriverEasyAccessRequest2 "true";
BA_ "Event" SG_ 1464 DriverEasyAccessRequest2 "true";
BA_ "Event" SG_ 1464 DriverEasyAccessRequest2 "true";
BA_ "Event" SG_ 1464 DriverEasyAccessRequest2 "true";
BA_ "Unavailable_Value" SG_ 1464 DriverEasyAccessRequest2 "0b00";
BA_ "Event" SG_ 1464 DriverMassageIntensityReq "true";
BA_ "Event" SG_ 1464 DriverMassageIntensityReq "true";
BA_ "Event" SG_ 1464 DriverMassageIntensityReq "true";
BA_ "Event" SG_ 1464 DriverMassageIntensityReq "true";
BA_ "Unavailable_Value" SG_ 1464 DriverMassageIntensityReq "0b000";
BA_ "Event" SG_ 1464 DriverMassageProgramReq "true";
BA_ "Event" SG_ 1464 DriverMassageProgramReq "true";
BA_ "Event" SG_ 1464 DriverMassageProgramReq "true";
BA_ "Event" SG_ 1464 DriverMassageProgramReq "true";
BA_ "Unavailable_Value" SG_ 1464 DriverMassageProgramReq "0b000";
BA_ "Event" SG_ 1464 PassengerMassageActivationReq "true";
BA_ "Event" SG_ 1464 PassengerMassageActivationReq "true";
BA_ "Event" SG_ 1464 PassengerMassageActivationReq "true";
BA_ "Event" SG_ 1464 PassengerMassageActivationReq "true";
BA_ "Unavailable_Value" SG_ 1464 PassengerMassageActivationReq "0b00";
BA_ "Event" SG_ 1464 PassengerMassageProgramReq "true";
BA_ "Event" SG_ 1464 PassengerMassageProgramReq "true";
BA_ "Event" SG_ 1464 PassengerMassageProgramReq "true";
BA_ "Event" SG_ 1464 PassengerMassageProgramReq "true";
BA_ "Unavailable_Value" SG_ 1464 PassengerMassageProgramReq "0b000";
BA_ "Event" SG_ 1464 DriverMassageVelocityReq "true";
BA_ "Event" SG_ 1464 DriverMassageVelocityReq "true";
BA_ "Event" SG_ 1464 DriverMassageVelocityReq "true";
BA_ "Event" SG_ 1464 DriverMassageVelocityReq "true";
BA_ "Unavailable_Value" SG_ 1464 DriverMassageVelocityReq "0b000";
BA_ "Event" SG_ 1464 PassengerEasyAccessRequest "true";
BA_ "Event" SG_ 1464 PassengerEasyAccessRequest "true";
BA_ "Event" SG_ 1464 PassengerEasyAccessRequest "true";
BA_ "Event" SG_ 1464 PassengerEasyAccessRequest "true";
BA_ "Unavailable_Value" SG_ 1464 PassengerEasyAccessRequest "0b00";
BA_ "Event" SG_ 1464 PassengerMassageVelocityReq "true";
BA_ "Event" SG_ 1464 PassengerMassageVelocityReq "true";
BA_ "Event" SG_ 1464 PassengerMassageVelocityReq "true";
BA_ "Event" SG_ 1464 PassengerMassageVelocityReq "true";
BA_ "Unavailable_Value" SG_ 1464 PassengerMassageVelocityReq "0b000";
BA_ "Event" SG_ 1464 PassengerMassageIntensityReq "true";
BA_ "Event" SG_ 1464 PassengerMassageIntensityReq "true";
BA_ "Event" SG_ 1464 PassengerMassageIntensityReq "true";
BA_ "Event" SG_ 1464 PassengerMassageIntensityReq "true";
BA_ "Unavailable_Value" SG_ 1464 PassengerMassageIntensityReq "0b000";
BA_ "Event" SG_ 1464 Sound3DActivationRequest "true";
BA_ "Event" SG_ 1464 Sound3DActivationRequest "true";
BA_ "Event" SG_ 1464 Sound3DActivationRequest "true";
BA_ "Event" SG_ 1464 Sound3DActivationRequest "true";
BA_ "Unavailable_Value" SG_ 1464 Sound3DActivationRequest "0b00";
BA_ "Event" SG_ 1464 AudioPilotActivationRequest "true";
BA_ "Event" SG_ 1464 AudioPilotActivationRequest "true";
BA_ "Event" SG_ 1464 AudioPilotActivationRequest "true";
BA_ "Event" SG_ 1464 AudioPilotActivationRequest "true";
BA_ "Unavailable_Value" SG_ 1464 AudioPilotActivationRequest "0b00";
BA_ "Event" SG_ 1464 CourtesyActivationRequest2 "true";
BA_ "Event" SG_ 1464 CourtesyActivationRequest2 "true";
BA_ "Event" SG_ 1464 CourtesyActivationRequest2 "true";
BA_ "Event" SG_ 1464 CourtesyActivationRequest2 "true";
BA_ "Unavailable_Value" SG_ 1464 CourtesyActivationRequest2 "0b00";
BA_ "Event" SG_ 1465 PreSoakHVACfunctionsRequest "true";
BA_ "Event" SG_ 1465 PreSoakHVACfunctionsRequest "true";
BA_ "Event" SG_ 1465 PreSoakHVACfunctionsRequest "true";
BA_ "Event" SG_ 1465 PreSoakHVACfunctionsRequest "true";
BA_ "Unavailable_Value" SG_ 1465 PreSoakHVACfunctionsRequest "null";
BA_ "Event" SG_ 1465 PreSoakTempValue_MMI_v2 "true";
BA_ "Event" SG_ 1465 PreSoakTempValue_MMI_v2 "true";
BA_ "Event" SG_ 1465 PreSoakTempValue_MMI_v2 "true";
BA_ "Event" SG_ 1465 PreSoakTempValue_MMI_v2 "true";
BA_ "Unavailable_Value" SG_ 1465 PreSoakTempValue_MMI_v2 "0x7F";
BA_ "Event" SG_ 1465 PreSoakFRseatRequest "true";
BA_ "Event" SG_ 1465 PreSoakFRseatRequest "true";
BA_ "Event" SG_ 1465 PreSoakFRseatRequest "true";
BA_ "Event" SG_ 1465 PreSoakFRseatRequest "true";
BA_ "Unavailable_Value" SG_ 1465 PreSoakFRseatRequest "null";
BA_ "Event" SG_ 1465 PreSoakFLseatRequest "true";
BA_ "Event" SG_ 1465 PreSoakFLseatRequest "true";
BA_ "Event" SG_ 1465 PreSoakFLseatRequest "true";
BA_ "Event" SG_ 1465 PreSoakFLseatRequest "true";
BA_ "Unavailable_Value" SG_ 1465 PreSoakFLseatRequest "null";
BA_ "Event" SG_ 1465 PreSoakSecondRLseatRequest "true";
BA_ "Event" SG_ 1465 PreSoakSecondRLseatRequest "true";
BA_ "Event" SG_ 1465 PreSoakSecondRLseatRequest "true";
BA_ "Event" SG_ 1465 PreSoakSecondRLseatRequest "true";
BA_ "Unavailable_Value" SG_ 1465 PreSoakSecondRLseatRequest "null";
BA_ "Event" SG_ 1465 PreSoakSecondRRseatRequest "true";
BA_ "Event" SG_ 1465 PreSoakSecondRRseatRequest "true";
BA_ "Event" SG_ 1465 PreSoakSecondRRseatRequest "true";
BA_ "Event" SG_ 1465 PreSoakSecondRRseatRequest "true";
BA_ "Unavailable_Value" SG_ 1465 PreSoakSecondRRseatRequest "null";
BA_ "Event" SG_ 1465 PreSoak_eACmodeRequest "true";
BA_ "Event" SG_ 1465 PreSoak_eACmodeRequest "true";
BA_ "Event" SG_ 1465 PreSoak_eACmodeRequest "true";
BA_ "Event" SG_ 1465 PreSoak_eACmodeRequest "true";
BA_ "Unavailable_Value" SG_ 1465 PreSoak_eACmodeRequest "null";
BA_ "Event" SG_ 1465 PreSoakThirdRLseatRequest "true";
BA_ "Event" SG_ 1465 PreSoakThirdRLseatRequest "true";
BA_ "Event" SG_ 1465 PreSoakThirdRLseatRequest "true";
BA_ "Event" SG_ 1465 PreSoakThirdRLseatRequest "true";
BA_ "Unavailable_Value" SG_ 1465 PreSoakThirdRLseatRequest "null";
BA_ "Event" SG_ 1465 PreSoakBatteryHeatingRequest "true";
BA_ "Event" SG_ 1465 PreSoakBatteryHeatingRequest "true";
BA_ "Event" SG_ 1465 PreSoakBatteryHeatingRequest "true";
BA_ "Event" SG_ 1465 PreSoakBatteryHeatingRequest "true";
BA_ "Unavailable_Value" SG_ 1465 PreSoakBatteryHeatingRequest "null";
BA_ "Event" SG_ 1465 PreSoakSecondRCseatRequest "true";
BA_ "Event" SG_ 1465 PreSoakSecondRCseatRequest "true";
BA_ "Event" SG_ 1465 PreSoakSecondRCseatRequest "true";
BA_ "Event" SG_ 1465 PreSoakSecondRCseatRequest "true";
BA_ "Unavailable_Value" SG_ 1465 PreSoakSecondRCseatRequest "null";
BA_ "Unavailable_Value" SG_ 1465 LivingLightModeRequest "0b0";
BA_ "Event" SG_ 1465 PreSoakAirPurifierRequest "true";
BA_ "Event" SG_ 1465 PreSoakAirPurifierRequest "true";
BA_ "Event" SG_ 1465 PreSoakAirPurifierRequest "true";
BA_ "Event" SG_ 1465 PreSoakAirPurifierRequest "true";
BA_ "Unavailable_Value" SG_ 1465 PreSoakAirPurifierRequest "null";
BA_ "Event" SG_ 1465 PreSoakFrontDefrostRequest "true";
BA_ "Event" SG_ 1465 PreSoakFrontDefrostRequest "true";
BA_ "Event" SG_ 1465 PreSoakFrontDefrostRequest "true";
BA_ "Event" SG_ 1465 PreSoakFrontDefrostRequest "true";
BA_ "Unavailable_Value" SG_ 1465 PreSoakFrontDefrostRequest "null";
BA_ "Event" SG_ 1465 PreSoakThirdRRseatRequest "true";
BA_ "Event" SG_ 1465 PreSoakThirdRRseatRequest "true";
BA_ "Event" SG_ 1465 PreSoakThirdRRseatRequest "true";
BA_ "Event" SG_ 1465 PreSoakThirdRRseatRequest "true";
BA_ "Unavailable_Value" SG_ 1465 PreSoakThirdRRseatRequest "null";
BA_ "Event" SG_ 1465 SecondRowCentralSeatRequest "true";
BA_ "Event" SG_ 1465 SecondRowCentralSeatRequest "true";
BA_ "Event" SG_ 1465 SecondRowCentralSeatRequest "true";
BA_ "Event" SG_ 1465 SecondRowCentralSeatRequest "true";
BA_ "Unavailable_Value" SG_ 1465 SecondRowCentralSeatRequest "0b0000";
BA_ "Event" SG_ 1465 PreSoakRearDefrostRequest "true";
BA_ "Event" SG_ 1465 PreSoakRearDefrostRequest "true";
BA_ "Event" SG_ 1465 PreSoakRearDefrostRequest "true";
BA_ "Event" SG_ 1465 PreSoakRearDefrostRequest "true";
BA_ "Unavailable_Value" SG_ 1465 PreSoakRearDefrostRequest "null";
BA_ "Event" SG_ 1465 PreSoakHeatedStrgWheelRequest "true";
BA_ "Event" SG_ 1465 PreSoakHeatedStrgWheelRequest "true";
BA_ "Event" SG_ 1465 PreSoakHeatedStrgWheelRequest "true";
BA_ "Event" SG_ 1465 PreSoakHeatedStrgWheelRequest "true";
BA_ "Unavailable_Value" SG_ 1465 PreSoakHeatedStrgWheelRequest "null";
BA_ "Event" SG_ 1465 FrontRightSeatRequest "true";
BA_ "Event" SG_ 1465 FrontRightSeatRequest "true";
BA_ "Event" SG_ 1465 FrontRightSeatRequest "true";
BA_ "Event" SG_ 1465 FrontRightSeatRequest "true";
BA_ "Unavailable_Value" SG_ 1465 FrontRightSeatRequest "0b0000";
BA_ "Event" SG_ 1465 FrontLeftSeatRequest "true";
BA_ "Event" SG_ 1465 FrontLeftSeatRequest "true";
BA_ "Event" SG_ 1465 FrontLeftSeatRequest "true";
BA_ "Event" SG_ 1465 FrontLeftSeatRequest "true";
BA_ "Unavailable_Value" SG_ 1465 FrontLeftSeatRequest "0b0000";
BA_ "Event" SG_ 1465 Dccharge_NextStationTimeArrival "true";
BA_ "Event" SG_ 1465 Dccharge_NextStationTimeArrival "true";
BA_ "Event" SG_ 1465 Dccharge_NextStationTimeArrival "true";
BA_ "Event" SG_ 1465 Dccharge_NextStationTimeArrival "true";
BA_ "Unavailable_Value" SG_ 1465 Dccharge_NextStationTimeArrival "0x7F";
BA_ "Event" SG_ 1466 FrontLeftWheelPressure_V2 "true";
BA_ "Event" SG_ 1466 FrontLeftWheelPressure_V2 "true";
BA_ "Event" SG_ 1466 FrontLeftWheelPressure_V2 "true";
BA_ "Event" SG_ 1466 FrontLeftWheelPressure_V2 "true";
BA_ "Unavailable_Value" SG_ 1466 FrontLeftWheelPressure_V2 "0xFF";
BA_ "Event" SG_ 1466 FrontRightWheelPressure_V2 "true";
BA_ "Event" SG_ 1466 FrontRightWheelPressure_V2 "true";
BA_ "Event" SG_ 1466 FrontRightWheelPressure_V2 "true";
BA_ "Event" SG_ 1466 FrontRightWheelPressure_V2 "true";
BA_ "Unavailable_Value" SG_ 1466 FrontRightWheelPressure_V2 "0xFF";
BA_ "Event" SG_ 1466 RearLeftWheelPressure_V2 "true";
BA_ "Event" SG_ 1466 RearLeftWheelPressure_V2 "true";
BA_ "Event" SG_ 1466 RearLeftWheelPressure_V2 "true";
BA_ "Event" SG_ 1466 RearLeftWheelPressure_V2 "true";
BA_ "Unavailable_Value" SG_ 1466 RearLeftWheelPressure_V2 "0xFF";
BA_ "Event" SG_ 1466 RearRightWheelPressure_V2 "true";
BA_ "Event" SG_ 1466 RearRightWheelPressure_V2 "true";
BA_ "Event" SG_ 1466 RearRightWheelPressure_V2 "true";
BA_ "Event" SG_ 1466 RearRightWheelPressure_V2 "true";
BA_ "Unavailable_Value" SG_ 1466 RearRightWheelPressure_V2 "0xFF";
BA_ "Event" SG_ 1466 EcoAdviceTirePressureRR "true";
BA_ "Event" SG_ 1466 EcoAdviceTirePressureRR "true";
BA_ "Event" SG_ 1466 EcoAdviceTirePressureRR "true";
BA_ "Event" SG_ 1466 EcoAdviceTirePressureRR "true";
BA_ "Unavailable_Value" SG_ 1466 EcoAdviceTirePressureRR "0b0";
BA_ "Event" SG_ 1466 EcoAdviceTirePressureRL "true";
BA_ "Event" SG_ 1466 EcoAdviceTirePressureRL "true";
BA_ "Event" SG_ 1466 EcoAdviceTirePressureRL "true";
BA_ "Event" SG_ 1466 EcoAdviceTirePressureRL "true";
BA_ "Unavailable_Value" SG_ 1466 EcoAdviceTirePressureRL "0b0";
BA_ "Event" SG_ 1466 EcoAdviceTirePressureFR "true";
BA_ "Event" SG_ 1466 EcoAdviceTirePressureFR "true";
BA_ "Event" SG_ 1466 EcoAdviceTirePressureFR "true";
BA_ "Event" SG_ 1466 EcoAdviceTirePressureFR "true";
BA_ "Unavailable_Value" SG_ 1466 EcoAdviceTirePressureFR "0b0";
BA_ "Event" SG_ 1466 EcoAdviceTirePressureFL "true";
BA_ "Event" SG_ 1466 EcoAdviceTirePressureFL "true";
BA_ "Event" SG_ 1466 EcoAdviceTirePressureFL "true";
BA_ "Event" SG_ 1466 EcoAdviceTirePressureFL "true";
BA_ "Unavailable_Value" SG_ 1466 EcoAdviceTirePressureFL "0b0";
BA_ "Event" SG_ 1468 DriverMassageVelocityState "true";
BA_ "Event" SG_ 1468 DriverMassageVelocityState "true";
BA_ "Event" SG_ 1468 DriverMassageVelocityState "true";
BA_ "Event" SG_ 1468 DriverMassageVelocityState "true";
BA_ "Unavailable_Value" SG_ 1468 DriverMassageVelocityState "0b000";
BA_ "Event" SG_ 1468 DriverMassageProgramState "true";
BA_ "Event" SG_ 1468 DriverMassageProgramState "true";
BA_ "Event" SG_ 1468 DriverMassageProgramState "true";
BA_ "Event" SG_ 1468 DriverMassageProgramState "true";
BA_ "Unavailable_Value" SG_ 1468 DriverMassageProgramState "0b00";
BA_ "Event" SG_ 1468 DriverMassageIntensityState "true";
BA_ "Event" SG_ 1468 DriverMassageIntensityState "true";
BA_ "Event" SG_ 1468 DriverMassageIntensityState "true";
BA_ "Event" SG_ 1468 DriverMassageIntensityState "true";
BA_ "Unavailable_Value" SG_ 1468 DriverMassageIntensityState "0b000";
BA_ "Event" SG_ 1468 DriverSeatMemoStatus "true";
BA_ "Event" SG_ 1468 DriverSeatMemoStatus "true";
BA_ "Event" SG_ 1468 DriverSeatMemoStatus "true";
BA_ "Event" SG_ 1468 DriverSeatMemoStatus "true";
BA_ "Unavailable_Value" SG_ 1468 DriverSeatMemoStatus "0b000";
BA_ "Event" SG_ 1468 DriverReclinerDisplayRequest "true";
BA_ "Event" SG_ 1468 DriverReclinerDisplayRequest "true";
BA_ "Event" SG_ 1468 DriverReclinerDisplayRequest "true";
BA_ "Event" SG_ 1468 DriverReclinerDisplayRequest "true";
BA_ "Unavailable_Value" SG_ 1468 DriverReclinerDisplayRequest "0b00";
BA_ "Event" SG_ 1468 DriverFrontHeightDisplayRequest "true";
BA_ "Event" SG_ 1468 DriverFrontHeightDisplayRequest "true";
BA_ "Event" SG_ 1468 DriverFrontHeightDisplayRequest "true";
BA_ "Event" SG_ 1468 DriverFrontHeightDisplayRequest "true";
BA_ "Unavailable_Value" SG_ 1468 DriverFrontHeightDisplayRequest "0b00";
BA_ "Event" SG_ 1468 SeatSettingsDisplayRequest "true";
BA_ "Event" SG_ 1468 SeatSettingsDisplayRequest "true";
BA_ "Event" SG_ 1468 SeatSettingsDisplayRequest "true";
BA_ "Event" SG_ 1468 SeatSettingsDisplayRequest "true";
BA_ "Unavailable_Value" SG_ 1468 SeatSettingsDisplayRequest "0b0";
BA_ "Event" SG_ 1468 DriverEasyAccessState "true";
BA_ "Event" SG_ 1468 DriverEasyAccessState "true";
BA_ "Event" SG_ 1468 DriverEasyAccessState "true";
BA_ "Event" SG_ 1468 DriverEasyAccessState "true";
BA_ "Unavailable_Value" SG_ 1468 DriverEasyAccessState "0b00";
BA_ "Event" SG_ 1468 DriverBackHeightDisplayRequest "true";
BA_ "Event" SG_ 1468 DriverBackHeightDisplayRequest "true";
BA_ "Event" SG_ 1468 DriverBackHeightDisplayRequest "true";
BA_ "Event" SG_ 1468 DriverBackHeightDisplayRequest "true";
BA_ "Unavailable_Value" SG_ 1468 DriverBackHeightDisplayRequest "0b00";
BA_ "Event" SG_ 1468 DriverMassageActivationState "true";
BA_ "Event" SG_ 1468 DriverMassageActivationState "true";
BA_ "Event" SG_ 1468 DriverMassageActivationState "true";
BA_ "Event" SG_ 1468 DriverMassageActivationState "true";
BA_ "Unavailable_Value" SG_ 1468 DriverMassageActivationState "0b0";
BA_ "Event" SG_ 1468 DriverSlidingDisplayRequest "true";
BA_ "Event" SG_ 1468 DriverSlidingDisplayRequest "true";
BA_ "Event" SG_ 1468 DriverSlidingDisplayRequest "true";
BA_ "Event" SG_ 1468 DriverSlidingDisplayRequest "true";
BA_ "Unavailable_Value" SG_ 1468 DriverSlidingDisplayRequest "0b00";
BA_ "Event" SG_ 1468 CourtesyActivationStatus "true";
BA_ "Event" SG_ 1468 CourtesyActivationStatus "true";
BA_ "Event" SG_ 1468 CourtesyActivationStatus "true";
BA_ "Event" SG_ 1468 CourtesyActivationStatus "true";
BA_ "Unavailable_Value" SG_ 1468 CourtesyActivationStatus "0b00";
BA_ "Event" SG_ 1469 AmbientLightingArea2Req "true";
BA_ "Event" SG_ 1469 AmbientLightingArea2Req "true";
BA_ "Event" SG_ 1469 AmbientLightingArea2Req "true";
BA_ "Event" SG_ 1469 AmbientLightingArea2Req "true";
BA_ "Unavailable_Value" SG_ 1469 AmbientLightingArea2Req "0b00";
BA_ "Event" SG_ 1469 AmbientLightingArea1Req "true";
BA_ "Event" SG_ 1469 AmbientLightingArea1Req "true";
BA_ "Event" SG_ 1469 AmbientLightingArea1Req "true";
BA_ "Event" SG_ 1469 AmbientLightingArea1Req "true";
BA_ "Unavailable_Value" SG_ 1469 AmbientLightingArea1Req "0b00";
BA_ "Event" SG_ 1469 AmbientLightingActivationReq "true";
BA_ "Event" SG_ 1469 AmbientLightingActivationReq "true";
BA_ "Event" SG_ 1469 AmbientLightingActivationReq "true";
BA_ "Event" SG_ 1469 AmbientLightingActivationReq "true";
BA_ "Unavailable_Value" SG_ 1469 AmbientLightingActivationReq "0b00";
BA_ "Event" SG_ 1469 AmbientLightingArea3Req "true";
BA_ "Event" SG_ 1469 AmbientLightingArea3Req "true";
BA_ "Event" SG_ 1469 AmbientLightingArea3Req "true";
BA_ "Event" SG_ 1469 AmbientLightingArea3Req "true";
BA_ "Unavailable_Value" SG_ 1469 AmbientLightingArea3Req "0b00";
BA_ "Event" SG_ 1469 MeterVolumeRequest "true";
BA_ "Event" SG_ 1469 MeterVolumeRequest "true";
BA_ "Event" SG_ 1469 MeterVolumeRequest "true";
BA_ "Event" SG_ 1469 MeterVolumeRequest "true";
BA_ "Unavailable_Value" SG_ 1469 MeterVolumeRequest "0b000";
BA_ "Event" SG_ 1469 AmbientLightDayIntensityRequest "true";
BA_ "Event" SG_ 1469 AmbientLightDayIntensityRequest "true";
BA_ "Event" SG_ 1469 AmbientLightDayIntensityRequest "true";
BA_ "Event" SG_ 1469 AmbientLightDayIntensityRequest "true";
BA_ "Unavailable_Value" SG_ 1469 AmbientLightDayIntensityRequest "0x1E";
BA_ "Event" SG_ 1469 AmbientLightNightIntensityReq "true";
BA_ "Event" SG_ 1469 AmbientLightNightIntensityReq "true";
BA_ "Event" SG_ 1469 AmbientLightNightIntensityReq "true";
BA_ "Event" SG_ 1469 AmbientLightNightIntensityReq "true";
BA_ "Unavailable_Value" SG_ 1469 AmbientLightNightIntensityReq "0x1E";
BA_ "Event" SG_ 1469 UnitDistanceDisplayRequest "true";
BA_ "Event" SG_ 1469 UnitDistanceDisplayRequest "true";
BA_ "Event" SG_ 1469 UnitDistanceDisplayRequest "true";
BA_ "Event" SG_ 1469 UnitDistanceDisplayRequest "true";
BA_ "Unavailable_Value" SG_ 1469 UnitDistanceDisplayRequest "0b00";
BA_ "Event" SG_ 1469 CockpitLanguageRequest "true";
BA_ "Event" SG_ 1469 CockpitLanguageRequest "true";
BA_ "Event" SG_ 1469 CockpitLanguageRequest "true";
BA_ "Event" SG_ 1469 CockpitLanguageRequest "true";
BA_ "Unavailable_Value" SG_ 1469 CockpitLanguageRequest "0x00";
BA_ "Event" SG_ 1469 IoniserAutoLaunchReq2 "true";
BA_ "Event" SG_ 1469 IoniserAutoLaunchReq2 "true";
BA_ "Event" SG_ 1469 IoniserAutoLaunchReq2 "true";
BA_ "Event" SG_ 1469 IoniserAutoLaunchReq2 "true";
BA_ "Unavailable_Value" SG_ 1469 IoniserAutoLaunchReq2 "0b00";
BA_ "Event" SG_ 1469 HVchargeDisplayRequest "true";
BA_ "Event" SG_ 1469 HVchargeDisplayRequest "true";
BA_ "Event" SG_ 1469 HVchargeDisplayRequest "true";
BA_ "Event" SG_ 1469 HVchargeDisplayRequest "true";
BA_ "Unavailable_Value" SG_ 1469 HVchargeDisplayRequest "0b00";
BA_ "Event" SG_ 1469 ADB_ActivationRequest2 "true";
BA_ "Event" SG_ 1469 ADB_ActivationRequest2 "true";
BA_ "Event" SG_ 1469 ADB_ActivationRequest2 "true";
BA_ "Event" SG_ 1469 ADB_ActivationRequest2 "true";
BA_ "Unavailable_Value" SG_ 1469 ADB_ActivationRequest2 "0b00";
BA_ "Event" SG_ 1469 AutoInternalLightingRequest2 "true";
BA_ "Event" SG_ 1469 AutoInternalLightingRequest2 "true";
BA_ "Event" SG_ 1469 AutoInternalLightingRequest2 "true";
BA_ "Event" SG_ 1469 AutoInternalLightingRequest2 "true";
BA_ "Unavailable_Value" SG_ 1469 AutoInternalLightingRequest2 "0b00";
BA_ "Event" SG_ 1470 ITM_LeftBlowingLevelDownPush "true";
BA_ "Event" SG_ 1470 ITM_LeftBlowingLevelDownPush "true";
BA_ "Event" SG_ 1470 ITM_LeftBlowingLevelDownPush "true";
BA_ "Event" SG_ 1470 ITM_LeftBlowingLevelDownPush "true";
BA_ "Unavailable_Value" SG_ 1470 ITM_LeftBlowingLevelDownPush "0b0";
BA_ "Event" SG_ 1470 ITM_HumidSensorSensitivUpPush "true";
BA_ "Event" SG_ 1470 ITM_HumidSensorSensitivUpPush "true";
BA_ "Event" SG_ 1470 ITM_HumidSensorSensitivUpPush "true";
BA_ "Event" SG_ 1470 ITM_HumidSensorSensitivUpPush "true";
BA_ "Unavailable_Value" SG_ 1470 ITM_HumidSensorSensitivUpPush "0b0";
BA_ "Event" SG_ 1470 ITM_HumidSensorSensitivOperType "true";
BA_ "Event" SG_ 1470 ITM_HumidSensorSensitivOperType "true";
BA_ "Event" SG_ 1470 ITM_HumidSensorSensitivOperType "true";
BA_ "Event" SG_ 1470 ITM_HumidSensorSensitivOperType "true";
BA_ "Event" SG_ 1470 ITM_HumidSensorSensitivDownPush "true";
BA_ "Event" SG_ 1470 ITM_HumidSensorSensitivDownPush "true";
BA_ "Event" SG_ 1470 ITM_HumidSensorSensitivDownPush "true";
BA_ "Event" SG_ 1470 ITM_HumidSensorSensitivDownPush "true";
BA_ "Unavailable_Value" SG_ 1470 ITM_HumidSensorSensitivDownPush "0b0";
BA_ "Event" SG_ 1470 ITM_BlowingLevelLongPush "true";
BA_ "Event" SG_ 1470 ITM_BlowingLevelLongPush "true";
BA_ "Event" SG_ 1470 ITM_BlowingLevelLongPush "true";
BA_ "Event" SG_ 1470 ITM_BlowingLevelLongPush "true";
BA_ "Unavailable_Value" SG_ 1470 ITM_BlowingLevelLongPush "0b0";
BA_ "Event" SG_ 1470 ITM_AQSSensitivityUpPush "true";
BA_ "Event" SG_ 1470 ITM_AQSSensitivityUpPush "true";
BA_ "Event" SG_ 1470 ITM_AQSSensitivityUpPush "true";
BA_ "Event" SG_ 1470 ITM_AQSSensitivityUpPush "true";
BA_ "Unavailable_Value" SG_ 1470 ITM_AQSSensitivityUpPush "0b0";
BA_ "Event" SG_ 1470 ITM_AQSSensitivityOperationType "true";
BA_ "Event" SG_ 1470 ITM_AQSSensitivityOperationType "true";
BA_ "Event" SG_ 1470 ITM_AQSSensitivityOperationType "true";
BA_ "Event" SG_ 1470 ITM_AQSSensitivityOperationType "true";
BA_ "Unavailable_Value" SG_ 1470 ITM_AQSSensitivityOperationType "0b0";
BA_ "Event" SG_ 1470 ITM_AQSSensitivityDownPush "true";
BA_ "Event" SG_ 1470 ITM_AQSSensitivityDownPush "true";
BA_ "Event" SG_ 1470 ITM_AQSSensitivityDownPush "true";
BA_ "Event" SG_ 1470 ITM_AQSSensitivityDownPush "true";
BA_ "Unavailable_Value" SG_ 1470 ITM_AQSSensitivityDownPush "0b0";
BA_ "Event" SG_ 1470 ITM_LeftFlowDistrRequest "true";
BA_ "Event" SG_ 1470 ITM_LeftFlowDistrRequest "true";
BA_ "Event" SG_ 1470 ITM_LeftFlowDistrRequest "true";
BA_ "Event" SG_ 1470 ITM_LeftFlowDistrRequest "true";
BA_ "Unavailable_Value" SG_ 1470 ITM_LeftFlowDistrRequest "0b000";
BA_ "Event" SG_ 1470 ITM_LeftFlowDistrOperationType "true";
BA_ "Event" SG_ 1470 ITM_LeftFlowDistrOperationType "true";
BA_ "Event" SG_ 1470 ITM_LeftFlowDistrOperationType "true";
BA_ "Event" SG_ 1470 ITM_LeftFlowDistrOperationType "true";
BA_ "Unavailable_Value" SG_ 1470 ITM_LeftFlowDistrOperationType "0b0";
BA_ "Event" SG_ 1470 ITM_LeftFlowDistrDownPush "true";
BA_ "Event" SG_ 1470 ITM_LeftFlowDistrDownPush "true";
BA_ "Event" SG_ 1470 ITM_LeftFlowDistrDownPush "true";
BA_ "Event" SG_ 1470 ITM_LeftFlowDistrDownPush "true";
BA_ "Unavailable_Value" SG_ 1470 ITM_LeftFlowDistrDownPush "0b0";
BA_ "Event" SG_ 1470 ITM_LeftBlowingLevelUpPush "true";
BA_ "Event" SG_ 1470 ITM_LeftBlowingLevelUpPush "true";
BA_ "Event" SG_ 1470 ITM_LeftBlowingLevelUpPush "true";
BA_ "Event" SG_ 1470 ITM_LeftBlowingLevelUpPush "true";
BA_ "Unavailable_Value" SG_ 1470 ITM_LeftBlowingLevelUpPush "0b0";
BA_ "Event" SG_ 1470 ITM_LeftBlowingLevelOperType "true";
BA_ "Event" SG_ 1470 ITM_LeftBlowingLevelOperType "true";
BA_ "Event" SG_ 1470 ITM_LeftBlowingLevelOperType "true";
BA_ "Event" SG_ 1470 ITM_LeftBlowingLevelOperType "true";
BA_ "Event" SG_ 1470 ITM_RearLeftBlowLevelOperType "true";
BA_ "Event" SG_ 1470 ITM_RearLeftBlowLevelOperType "true";
BA_ "Event" SG_ 1470 ITM_RearLeftBlowLevelOperType "true";
BA_ "Event" SG_ 1470 ITM_RearLeftBlowLevelOperType "true";
BA_ "Event" SG_ 1470 ITM_RearLeftBlowLevelDownPush "true";
BA_ "Event" SG_ 1470 ITM_RearLeftBlowLevelDownPush "true";
BA_ "Event" SG_ 1470 ITM_RearLeftBlowLevelDownPush "true";
BA_ "Event" SG_ 1470 ITM_RearLeftBlowLevelDownPush "true";
BA_ "Unavailable_Value" SG_ 1470 ITM_RearLeftBlowLevelDownPush "0b0";
BA_ "Event" SG_ 1470 ITM_LeftTempUpPush "true";
BA_ "Event" SG_ 1470 ITM_LeftTempUpPush "true";
BA_ "Event" SG_ 1470 ITM_LeftTempUpPush "true";
BA_ "Event" SG_ 1470 ITM_LeftTempUpPush "true";
BA_ "Unavailable_Value" SG_ 1470 ITM_LeftTempUpPush "0b0";
BA_ "Event" SG_ 1470 ITM_LeftTempOperationType "true";
BA_ "Event" SG_ 1470 ITM_LeftTempOperationType "true";
BA_ "Event" SG_ 1470 ITM_LeftTempOperationType "true";
BA_ "Event" SG_ 1470 ITM_LeftTempOperationType "true";
BA_ "Event" SG_ 1470 ITM_LeftTempDownPush "true";
BA_ "Event" SG_ 1470 ITM_LeftTempDownPush "true";
BA_ "Event" SG_ 1470 ITM_LeftTempDownPush "true";
BA_ "Event" SG_ 1470 ITM_LeftTempDownPush "true";
BA_ "Unavailable_Value" SG_ 1470 ITM_LeftTempDownPush "0b0";
BA_ "Event" SG_ 1470 ITM_LeftFlowDistrUpPush "true";
BA_ "Event" SG_ 1470 ITM_LeftFlowDistrUpPush "true";
BA_ "Event" SG_ 1470 ITM_LeftFlowDistrUpPush "true";
BA_ "Event" SG_ 1470 ITM_LeftFlowDistrUpPush "true";
BA_ "Unavailable_Value" SG_ 1470 ITM_LeftFlowDistrUpPush "0b0";
BA_ "Event" SG_ 1470 ITM_RearLeftTempDownPush "true";
BA_ "Event" SG_ 1470 ITM_RearLeftTempDownPush "true";
BA_ "Event" SG_ 1470 ITM_RearLeftTempDownPush "true";
BA_ "Event" SG_ 1470 ITM_RearLeftTempDownPush "true";
BA_ "Unavailable_Value" SG_ 1470 ITM_RearLeftTempDownPush "0b0";
BA_ "Event" SG_ 1470 ITM_RearLeftFlowDistrUpPush "true";
BA_ "Event" SG_ 1470 ITM_RearLeftFlowDistrUpPush "true";
BA_ "Event" SG_ 1470 ITM_RearLeftFlowDistrUpPush "true";
BA_ "Event" SG_ 1470 ITM_RearLeftFlowDistrUpPush "true";
BA_ "Unavailable_Value" SG_ 1470 ITM_RearLeftFlowDistrUpPush "0b0";
BA_ "Event" SG_ 1470 ITM_RearLeftFlowDistrRequest "true";
BA_ "Event" SG_ 1470 ITM_RearLeftFlowDistrRequest "true";
BA_ "Event" SG_ 1470 ITM_RearLeftFlowDistrRequest "true";
BA_ "Event" SG_ 1470 ITM_RearLeftFlowDistrRequest "true";
BA_ "Unavailable_Value" SG_ 1470 ITM_RearLeftFlowDistrRequest "0b000";
BA_ "Event" SG_ 1470 ITM_RearLeftFlowDistrOperType "true";
BA_ "Event" SG_ 1470 ITM_RearLeftFlowDistrOperType "true";
BA_ "Event" SG_ 1470 ITM_RearLeftFlowDistrOperType "true";
BA_ "Event" SG_ 1470 ITM_RearLeftFlowDistrOperType "true";
BA_ "Unavailable_Value" SG_ 1470 ITM_RearLeftFlowDistrOperType "0b0";
BA_ "Event" SG_ 1470 ITM_RearLeftFlowDistrDownPush "true";
BA_ "Event" SG_ 1470 ITM_RearLeftFlowDistrDownPush "true";
BA_ "Event" SG_ 1470 ITM_RearLeftFlowDistrDownPush "true";
BA_ "Event" SG_ 1470 ITM_RearLeftFlowDistrDownPush "true";
BA_ "Unavailable_Value" SG_ 1470 ITM_RearLeftFlowDistrDownPush "0b0";
BA_ "Event" SG_ 1470 ITM_RearLeftBlowLevelUpPush "true";
BA_ "Event" SG_ 1470 ITM_RearLeftBlowLevelUpPush "true";
BA_ "Event" SG_ 1470 ITM_RearLeftBlowLevelUpPush "true";
BA_ "Event" SG_ 1470 ITM_RearLeftBlowLevelUpPush "true";
BA_ "Unavailable_Value" SG_ 1470 ITM_RearLeftBlowLevelUpPush "0b0";
BA_ "Event" SG_ 1470 ITM_RearRightFlowDistrDownPush "true";
BA_ "Event" SG_ 1470 ITM_RearRightFlowDistrDownPush "true";
BA_ "Event" SG_ 1470 ITM_RearRightFlowDistrDownPush "true";
BA_ "Event" SG_ 1470 ITM_RearRightFlowDistrDownPush "true";
BA_ "Unavailable_Value" SG_ 1470 ITM_RearRightFlowDistrDownPush "0b0";
BA_ "Event" SG_ 1470 ITM_RearRightBlowLevelUpPush "true";
BA_ "Event" SG_ 1470 ITM_RearRightBlowLevelUpPush "true";
BA_ "Event" SG_ 1470 ITM_RearRightBlowLevelUpPush "true";
BA_ "Event" SG_ 1470 ITM_RearRightBlowLevelUpPush "true";
BA_ "Unavailable_Value" SG_ 1470 ITM_RearRightBlowLevelUpPush "0b0";
BA_ "Event" SG_ 1470 ITM_RearRightBlowLevelOperType "true";
BA_ "Event" SG_ 1470 ITM_RearRightBlowLevelOperType "true";
BA_ "Event" SG_ 1470 ITM_RearRightBlowLevelOperType "true";
BA_ "Event" SG_ 1470 ITM_RearRightBlowLevelOperType "true";
BA_ "Event" SG_ 1470 ITM_RearRightBlowLevelDownPush "true";
BA_ "Event" SG_ 1470 ITM_RearRightBlowLevelDownPush "true";
BA_ "Event" SG_ 1470 ITM_RearRightBlowLevelDownPush "true";
BA_ "Event" SG_ 1470 ITM_RearRightBlowLevelDownPush "true";
BA_ "Unavailable_Value" SG_ 1470 ITM_RearRightBlowLevelDownPush "0b0";
BA_ "Event" SG_ 1470 ITM_RearLeftTempUpPush "true";
BA_ "Event" SG_ 1470 ITM_RearLeftTempUpPush "true";
BA_ "Event" SG_ 1470 ITM_RearLeftTempUpPush "true";
BA_ "Event" SG_ 1470 ITM_RearLeftTempUpPush "true";
BA_ "Unavailable_Value" SG_ 1470 ITM_RearLeftTempUpPush "0b0";
BA_ "Event" SG_ 1470 ITM_RearLeftTempOperationType "true";
BA_ "Event" SG_ 1470 ITM_RearLeftTempOperationType "true";
BA_ "Event" SG_ 1470 ITM_RearLeftTempOperationType "true";
BA_ "Event" SG_ 1470 ITM_RearLeftTempOperationType "true";
BA_ "Event" SG_ 1470 ITM_RearRightTempOperationType "true";
BA_ "Event" SG_ 1470 ITM_RearRightTempOperationType "true";
BA_ "Event" SG_ 1470 ITM_RearRightTempOperationType "true";
BA_ "Event" SG_ 1470 ITM_RearRightTempOperationType "true";
BA_ "Event" SG_ 1470 ITM_RearRightTempDownPush "true";
BA_ "Event" SG_ 1470 ITM_RearRightTempDownPush "true";
BA_ "Event" SG_ 1470 ITM_RearRightTempDownPush "true";
BA_ "Event" SG_ 1470 ITM_RearRightTempDownPush "true";
BA_ "Unavailable_Value" SG_ 1470 ITM_RearRightTempDownPush "0b0";
BA_ "Event" SG_ 1470 ITM_RearRightFlowDistrUpPush "true";
BA_ "Event" SG_ 1470 ITM_RearRightFlowDistrUpPush "true";
BA_ "Event" SG_ 1470 ITM_RearRightFlowDistrUpPush "true";
BA_ "Event" SG_ 1470 ITM_RearRightFlowDistrUpPush "true";
BA_ "Unavailable_Value" SG_ 1470 ITM_RearRightFlowDistrUpPush "0b0";
BA_ "Event" SG_ 1470 ITM_RearRightFlowDistrRequest "true";
BA_ "Event" SG_ 1470 ITM_RearRightFlowDistrRequest "true";
BA_ "Event" SG_ 1470 ITM_RearRightFlowDistrRequest "true";
BA_ "Event" SG_ 1470 ITM_RearRightFlowDistrRequest "true";
BA_ "Unavailable_Value" SG_ 1470 ITM_RearRightFlowDistrRequest "0b000";
BA_ "Event" SG_ 1470 ITM_RearRightFlowDistrOperType "true";
BA_ "Event" SG_ 1470 ITM_RearRightFlowDistrOperType "true";
BA_ "Event" SG_ 1470 ITM_RearRightFlowDistrOperType "true";
BA_ "Event" SG_ 1470 ITM_RearRightFlowDistrOperType "true";
BA_ "Unavailable_Value" SG_ 1470 ITM_RearRightFlowDistrOperType "0b0";
BA_ "Event" SG_ 1470 ITM_RightFlowDistrUpPush "true";
BA_ "Event" SG_ 1470 ITM_RightFlowDistrUpPush "true";
BA_ "Event" SG_ 1470 ITM_RightFlowDistrUpPush "true";
BA_ "Event" SG_ 1470 ITM_RightFlowDistrUpPush "true";
BA_ "Unavailable_Value" SG_ 1470 ITM_RightFlowDistrUpPush "0b0";
BA_ "Event" SG_ 1470 ITM_RightFlowDistrOperationType "true";
BA_ "Event" SG_ 1470 ITM_RightFlowDistrOperationType "true";
BA_ "Event" SG_ 1470 ITM_RightFlowDistrOperationType "true";
BA_ "Event" SG_ 1470 ITM_RightFlowDistrOperationType "true";
BA_ "Unavailable_Value" SG_ 1470 ITM_RightFlowDistrOperationType "0b0";
BA_ "Event" SG_ 1470 ITM_RightFlowDistrDownPush "true";
BA_ "Event" SG_ 1470 ITM_RightFlowDistrDownPush "true";
BA_ "Event" SG_ 1470 ITM_RightFlowDistrDownPush "true";
BA_ "Event" SG_ 1470 ITM_RightFlowDistrDownPush "true";
BA_ "Unavailable_Value" SG_ 1470 ITM_RightFlowDistrDownPush "0b0";
BA_ "Event" SG_ 1470 ITM_RightBlowingLevelUpPush "true";
BA_ "Event" SG_ 1470 ITM_RightBlowingLevelUpPush "true";
BA_ "Event" SG_ 1470 ITM_RightBlowingLevelUpPush "true";
BA_ "Event" SG_ 1470 ITM_RightBlowingLevelUpPush "true";
BA_ "Unavailable_Value" SG_ 1470 ITM_RightBlowingLevelUpPush "0b0";
BA_ "Event" SG_ 1470 ITM_RightBlowingLevelOperType "true";
BA_ "Event" SG_ 1470 ITM_RightBlowingLevelOperType "true";
BA_ "Event" SG_ 1470 ITM_RightBlowingLevelOperType "true";
BA_ "Event" SG_ 1470 ITM_RightBlowingLevelOperType "true";
BA_ "Event" SG_ 1470 ITM_RightBlowingLevelDownPush "true";
BA_ "Event" SG_ 1470 ITM_RightBlowingLevelDownPush "true";
BA_ "Event" SG_ 1470 ITM_RightBlowingLevelDownPush "true";
BA_ "Event" SG_ 1470 ITM_RightBlowingLevelDownPush "true";
BA_ "Unavailable_Value" SG_ 1470 ITM_RightBlowingLevelDownPush "0b0";
BA_ "Event" SG_ 1470 ITM_RearRightTempUpPush "true";
BA_ "Event" SG_ 1470 ITM_RearRightTempUpPush "true";
BA_ "Event" SG_ 1470 ITM_RearRightTempUpPush "true";
BA_ "Event" SG_ 1470 ITM_RearRightTempUpPush "true";
BA_ "Unavailable_Value" SG_ 1470 ITM_RearRightTempUpPush "0b0";
BA_ "Event" SG_ 1470 ITM_TempLongPush "true";
BA_ "Event" SG_ 1470 ITM_TempLongPush "true";
BA_ "Event" SG_ 1470 ITM_TempLongPush "true";
BA_ "Event" SG_ 1470 ITM_TempLongPush "true";
BA_ "Unavailable_Value" SG_ 1470 ITM_TempLongPush "0b0";
BA_ "Event" SG_ 1470 ITM_RightTempUpPush "true";
BA_ "Event" SG_ 1470 ITM_RightTempUpPush "true";
BA_ "Event" SG_ 1470 ITM_RightTempUpPush "true";
BA_ "Event" SG_ 1470 ITM_RightTempUpPush "true";
BA_ "Unavailable_Value" SG_ 1470 ITM_RightTempUpPush "0b0";
BA_ "Event" SG_ 1470 ITM_RightTempOperationType "true";
BA_ "Event" SG_ 1470 ITM_RightTempOperationType "true";
BA_ "Event" SG_ 1470 ITM_RightTempOperationType "true";
BA_ "Event" SG_ 1470 ITM_RightTempOperationType "true";
BA_ "Event" SG_ 1470 ITM_RightTempDownPush "true";
BA_ "Event" SG_ 1470 ITM_RightTempDownPush "true";
BA_ "Event" SG_ 1470 ITM_RightTempDownPush "true";
BA_ "Event" SG_ 1470 ITM_RightTempDownPush "true";
BA_ "Unavailable_Value" SG_ 1470 ITM_RightTempDownPush "0b0";
BA_ "Event" SG_ 1470 ITM_RightFlowDistrRequest "true";
BA_ "Event" SG_ 1470 ITM_RightFlowDistrRequest "true";
BA_ "Event" SG_ 1470 ITM_RightFlowDistrRequest "true";
BA_ "Event" SG_ 1470 ITM_RightFlowDistrRequest "true";
BA_ "Unavailable_Value" SG_ 1470 ITM_RightFlowDistrRequest "0b000";
BA_ "Event" SG_ 1471 PassengerBackHeightDisplayReq "true";
BA_ "Event" SG_ 1471 PassengerBackHeightDisplayReq "true";
BA_ "Event" SG_ 1471 PassengerBackHeightDisplayReq "true";
BA_ "Event" SG_ 1471 PassengerBackHeightDisplayReq "true";
BA_ "Unavailable_Value" SG_ 1471 PassengerBackHeightDisplayReq "0b00";
BA_ "Event" SG_ 1471 PassengerSlidingDisplayRequest "true";
BA_ "Event" SG_ 1471 PassengerSlidingDisplayRequest "true";
BA_ "Event" SG_ 1471 PassengerSlidingDisplayRequest "true";
BA_ "Event" SG_ 1471 PassengerSlidingDisplayRequest "true";
BA_ "Unavailable_Value" SG_ 1471 PassengerSlidingDisplayRequest "0b00";
BA_ "Event" SG_ 1471 PassengerEasyAccessState "true";
BA_ "Event" SG_ 1471 PassengerEasyAccessState "true";
BA_ "Event" SG_ 1471 PassengerEasyAccessState "true";
BA_ "Event" SG_ 1471 PassengerEasyAccessState "true";
BA_ "Unavailable_Value" SG_ 1471 PassengerEasyAccessState "0b00";
BA_ "Event" SG_ 1471 PassengerMassageProgramState "true";
BA_ "Event" SG_ 1471 PassengerMassageProgramState "true";
BA_ "Event" SG_ 1471 PassengerMassageProgramState "true";
BA_ "Event" SG_ 1471 PassengerMassageProgramState "true";
BA_ "Unavailable_Value" SG_ 1471 PassengerMassageProgramState "0b00";
BA_ "Event" SG_ 1471 PassengerFrontHeightDisplayReq "true";
BA_ "Event" SG_ 1471 PassengerFrontHeightDisplayReq "true";
BA_ "Event" SG_ 1471 PassengerFrontHeightDisplayReq "true";
BA_ "Event" SG_ 1471 PassengerFrontHeightDisplayReq "true";
BA_ "Unavailable_Value" SG_ 1471 PassengerFrontHeightDisplayReq "0b00";
BA_ "Event" SG_ 1471 PassengerMassageIntensityState "true";
BA_ "Event" SG_ 1471 PassengerMassageIntensityState "true";
BA_ "Event" SG_ 1471 PassengerMassageIntensityState "true";
BA_ "Event" SG_ 1471 PassengerMassageIntensityState "true";
BA_ "Unavailable_Value" SG_ 1471 PassengerMassageIntensityState "0b000";
BA_ "Event" SG_ 1471 PassengerMassageVelocityState "true";
BA_ "Event" SG_ 1471 PassengerMassageVelocityState "true";
BA_ "Event" SG_ 1471 PassengerMassageVelocityState "true";
BA_ "Event" SG_ 1471 PassengerMassageVelocityState "true";
BA_ "Unavailable_Value" SG_ 1471 PassengerMassageVelocityState "0b000";
BA_ "Event" SG_ 1471 PassengerMassageActivationState "true";
BA_ "Event" SG_ 1471 PassengerMassageActivationState "true";
BA_ "Event" SG_ 1471 PassengerMassageActivationState "true";
BA_ "Event" SG_ 1471 PassengerMassageActivationState "true";
BA_ "Unavailable_Value" SG_ 1471 PassengerMassageActivationState "0b0";
BA_ "Event" SG_ 1471 PassengerSeatMMIRequest "true";
BA_ "Event" SG_ 1471 PassengerSeatMMIRequest "true";
BA_ "Event" SG_ 1471 PassengerSeatMMIRequest "true";
BA_ "Event" SG_ 1471 PassengerSeatMMIRequest "true";
BA_ "Unavailable_Value" SG_ 1471 PassengerSeatMMIRequest "0b0";
BA_ "Event" SG_ 1471 PassengerReclinerDisplayRequest "true";
BA_ "Event" SG_ 1471 PassengerReclinerDisplayRequest "true";
BA_ "Event" SG_ 1471 PassengerReclinerDisplayRequest "true";
BA_ "Event" SG_ 1471 PassengerReclinerDisplayRequest "true";
BA_ "Unavailable_Value" SG_ 1471 PassengerReclinerDisplayRequest "0b00";
BA_ "Event" SG_ 1472 MexModeState "true";
BA_ "Event" SG_ 1472 MexModeState "true";
BA_ "Event" SG_ 1472 MexModeState "true";
BA_ "Event" SG_ 1472 MexModeState "true";
BA_ "Unavailable_Value" SG_ 1472 MexModeState "0b000";
BA_ "Event" SG_ 1472 MexModeState_xEV "true";
BA_ "Event" SG_ 1472 MexModeState_xEV "true";
BA_ "Event" SG_ 1472 MexModeState_xEV "true";
BA_ "Event" SG_ 1472 MexModeState_xEV "true";
BA_ "Unavailable_Value" SG_ 1472 MexModeState_xEV "0b000";
BA_ "Event" SG_ 1474 ClimRightTempDisplay "true";
BA_ "Event" SG_ 1474 ClimRightTempDisplay "true";
BA_ "Event" SG_ 1474 ClimRightTempDisplay "true";
BA_ "Event" SG_ 1474 ClimRightTempDisplay "true";
BA_ "Unavailable_Value" SG_ 1474 ClimRightTempDisplay "0x00";
BA_ "Event" SG_ 1474 ClimTempDisplay "true";
BA_ "Event" SG_ 1474 ClimTempDisplay "true";
BA_ "Event" SG_ 1474 ClimTempDisplay "true";
BA_ "Event" SG_ 1474 ClimTempDisplay "true";
BA_ "Unavailable_Value" SG_ 1474 ClimTempDisplay "0x00";
BA_ "Event" SG_ 1474 ClimFlowDistrDisplay "true";
BA_ "Event" SG_ 1474 ClimFlowDistrDisplay "true";
BA_ "Event" SG_ 1474 ClimFlowDistrDisplay "true";
BA_ "Event" SG_ 1474 ClimFlowDistrDisplay "true";
BA_ "Unavailable_Value" SG_ 1474 ClimFlowDistrDisplay "0x0";
BA_ "Event" SG_ 1474 ClimOFFModeDisplay "true";
BA_ "Event" SG_ 1474 ClimOFFModeDisplay "true";
BA_ "Event" SG_ 1474 ClimOFFModeDisplay "true";
BA_ "Event" SG_ 1474 ClimOFFModeDisplay "true";
BA_ "Unavailable_Value" SG_ 1474 ClimOFFModeDisplay "0b0";
BA_ "Unavailable_Value" SG_ 1474 ClimModeTypeDisplay "0b000";
BA_ "Event" SG_ 1474 ClimBlowerLevelDisplay "true";
BA_ "Event" SG_ 1474 ClimBlowerLevelDisplay "true";
BA_ "Event" SG_ 1474 ClimBlowerLevelDisplay "true";
BA_ "Event" SG_ 1474 ClimBlowerLevelDisplay "true";
BA_ "Unavailable_Value" SG_ 1474 ClimBlowerLevelDisplay "0x0";
BA_ "Event" SG_ 1474 ClimClearnessDisplay "true";
BA_ "Event" SG_ 1474 ClimClearnessDisplay "true";
BA_ "Event" SG_ 1474 ClimClearnessDisplay "true";
BA_ "Event" SG_ 1474 ClimClearnessDisplay "true";
BA_ "Unavailable_Value" SG_ 1474 ClimClearnessDisplay "0b00";
BA_ "Event" SG_ 1474 ClimAutoModeDisplay "true";
BA_ "Event" SG_ 1474 ClimAutoModeDisplay "true";
BA_ "Event" SG_ 1474 ClimAutoModeDisplay "true";
BA_ "Event" SG_ 1474 ClimAutoModeDisplay "true";
BA_ "Unavailable_Value" SG_ 1474 ClimAutoModeDisplay "0b00";
BA_ "Event" SG_ 1474 ClimAutoDisplay "true";
BA_ "Event" SG_ 1474 ClimAutoDisplay "true";
BA_ "Event" SG_ 1474 ClimAutoDisplay "true";
BA_ "Event" SG_ 1474 ClimAutoDisplay "true";
BA_ "Unavailable_Value" SG_ 1474 ClimAutoDisplay "0b00";
BA_ "Event" SG_ 1474 ClimACDisplay "true";
BA_ "Event" SG_ 1474 ClimACDisplay "true";
BA_ "Event" SG_ 1474 ClimACDisplay "true";
BA_ "Event" SG_ 1474 ClimACDisplay "true";
BA_ "Unavailable_Value" SG_ 1474 ClimACDisplay "0b00";
BA_ "Unavailable_Value" SG_ 1474 ClimRearModeDisplay "0b00";
BA_ "Event" SG_ 1474 ClimRearDefrostDisplay "true";
BA_ "Event" SG_ 1474 ClimRearDefrostDisplay "true";
BA_ "Event" SG_ 1474 ClimRearDefrostDisplay "true";
BA_ "Event" SG_ 1474 ClimRearDefrostDisplay "true";
BA_ "Unavailable_Value" SG_ 1474 ClimRearDefrostDisplay "0b00";
BA_ "Unavailable_Value" SG_ 1474 CabinTempCurrentValue "0x7F";
BA_ "Event" SG_ 1475 LongitudeSeconde "true";
BA_ "Event" SG_ 1475 LongitudeSeconde "true";
BA_ "Event" SG_ 1475 LongitudeSeconde "true";
BA_ "Unavailable_Value" SG_ 1475 LongitudeSeconde "0x1FFF";
BA_ "Event" SG_ 1475 LongitudeMode "true";
BA_ "Event" SG_ 1475 LongitudeMode "true";
BA_ "Event" SG_ 1475 LongitudeMode "true";
BA_ "Unavailable_Value" SG_ 1475 LongitudeMode "0b0";
BA_ "Event" SG_ 1475 LattitudeMode "true";
BA_ "Event" SG_ 1475 LattitudeMode "true";
BA_ "Event" SG_ 1475 LattitudeMode "true";
BA_ "Unavailable_Value" SG_ 1475 LattitudeMode "0b0";
BA_ "Unavailable_Value" SG_ 1475 LocationType "0b0";
BA_ "Event" SG_ 1475 LattitudeDegree "true";
BA_ "Event" SG_ 1475 LattitudeDegree "true";
BA_ "Event" SG_ 1475 LattitudeDegree "true";
BA_ "Unavailable_Value" SG_ 1475 LattitudeDegree "0xFF";
BA_ "Event" SG_ 1475 LongitudeDegree "true";
BA_ "Event" SG_ 1475 LongitudeDegree "true";
BA_ "Event" SG_ 1475 LongitudeDegree "true";
BA_ "Unavailable_Value" SG_ 1475 LongitudeDegree "0xFF";
BA_ "Event" SG_ 1475 LattitudeSeconde "true";
BA_ "Event" SG_ 1475 LattitudeSeconde "true";
BA_ "Event" SG_ 1475 LattitudeSeconde "true";
BA_ "Unavailable_Value" SG_ 1475 LattitudeSeconde "0x1FFF";
BA_ "Event" SG_ 1475 LongitudeMinute "true";
BA_ "Event" SG_ 1475 LongitudeMinute "true";
BA_ "Event" SG_ 1475 LongitudeMinute "true";
BA_ "Unavailable_Value" SG_ 1475 LongitudeMinute "0x3F";
BA_ "Event" SG_ 1475 LattitudeMinute "true";
BA_ "Event" SG_ 1475 LattitudeMinute "true";
BA_ "Event" SG_ 1475 LattitudeMinute "true";
BA_ "Unavailable_Value" SG_ 1475 LattitudeMinute "0x3F";
VAL_ 1345 NAVI_TrafficProfileType 7 "Not Used" 6 "Not Used" 5 "Not Used" 4 "Reserved" 3 "Reserved" 2 "Traffic restriction information" 1 "Traffic obstruction information" 0 "Traffic jam information";
VAL_ 1345 NAVI_TrafficETCError 1 "Error" 0 "No Error";
VAL_ 1345 NAVI_TrafficFMError 1 "Error" 0 "No Error";
VAL_ 1345 NAVI_TrafficUpdateStatus 1 "Update" 0 "Not update";
VAL_ 1345 NAVI_TrafficFirstData_Flag 1 "First data" 0 "Not First data";
VAL_ 1345 NAVI_TrafficOpticalError 1 "Error" 0 "No Error";
VAL_ 1345 NAVI_TrafficValue0 15 "Code15" 14 "Code14" 13 "Code13" 12 "Code12" 11 "Code11" 10 "Code10" 9 "Code9" 8 "Code8" 7 "Code7" 6 "Code6" 5 "Code5" 4 "Code4" 3 "Code3" 2 "Code2" 1 "Code1" 0 "Code0";
VAL_ 1345 NAVI_TrafficUpdate 1 "This message contain update info" 0 "This message does not contain update info";
VAL_ 1345 NAVI_TrafficRetransmission 1 "This message was sent already at least once before" 0 "This message was not sent yet";
VAL_ 1345 NAVI_TrafficAccuracy 3 "Unknown" 2 "Lowest accuracy" 1 "Medium accuracy" 0 "Highest accuracy";
VAL_ 1356 ADASISv2_POSITION 0 "Table Value30477";
VAL_ 1365 FAPK_DefaultManeuverTypeState 7 "Unavailable" 6 "Not Used" 5 "Not Used" 4 "mode auto" 3 "park in / angled" 2 "park in / perpendicular" 1 "park in / parallel" 0 "Not Used";
VAL_ 1365 ZoomAutoActivationState 1 "Zoom auto Activated" 0 "Zoom auto Deactivated";
VAL_ 1365 AVM_GuidelineActivationState 7 "Unavailable" 6 "Not Used" 5 "Not Used" 4 "Not Used" 3 "Static and Dynamic Guideline Activated" 2 "Dynamic Guideline Activated" 1 "Static Guideline Activated" 0 "Static and Dynamic Guideline Deactivated";
VAL_ 1365 APA_ManeuverFeedback 3 "Unavailable" 2 "Feedback 2" 1 "Feedback 1" 0 "No request";
VAL_ 1365 APAStart_SwitchStatus 7 "display switch maneuver5" 6 "display switch maneuver4" 5 "display switch maneuver3" 4 "display switch maneuver2" 3 "display switch maneuver1" 2 "display switch" 1 "unusable" 0 "No display";
VAL_ 1369 OSE_RearRightDoorAlert 3 "Not Used" 2 "Level2" 1 "Level1" 0 "No alert";
VAL_ 1369 OSE_RearLeftDoorAlert 3 "Not Used" 2 "Level2" 1 "Level1" 0 "No alert";
VAL_ 1369 OSE_FrontLeftDoorAlert 3 "Not Used" 2 "Level2" 1 "Level1" 0 "No alert";
VAL_ 1369 OSE_FronRightDoorAlert 3 "Not Used" 2 "Level2" 1 "Level1" 0 "No alert";
VAL_ 1369 ADAS_LinkFailureRequest 1 "Request" 0 "No request";
VAL_ 1369 ADAS_BranchDirection 3 "Not Used" 2 "Right branch" 1 "Left branch" 0 "No branch";
VAL_ 1369 OSE_ActivationState 1 "Deactivated" 0 "Activated";
VAL_ 1369 ELKA_ActivationState 1 "Deactivated" 0 "Activated";
VAL_ 1369 SET_MAPAutoUpdate_State 3 "Not used" 2 "ON" 1 "OFF" 0 "Invalid";
VAL_ 1369 SET_FocusState_State 3 "Not used" 2 "ON" 1 "OFF" 0 "Invalid";
VAL_ 1369 SET_ADL3_State 3 "Not used" 2 "ON" 1 "OFF" 0 "Invalid";
VAL_ 1369 SET_ALCP2P_AlertLevel_State 3 "Lv3" 2 "Lv2" 1 "Lv1" 0 "Invalid";
VAL_ 1380 TripUnitConsumption 7 "MPGe (UK)" 6 "MPGe (US)" 5 "KWh / 100 miles" 4 "KWh / 100 Km" 3 "MPGuk and M/kWh (MPGe)" 2 "MPGus and M/kWh (MPGe)" 1 "Km / L and km/kWh" 0 "L / 100 km and kWh/100km";
VAL_ 1380 FrostWarningDisplay 1 "Frost warning Alert" 0 "No alert";
VAL_ 1380 TripUnitDistance 3 "not used" 2 "not used" 1 "Miles" 0 "Km";
VAL_ 1380 MeterLanguageStatus 255 "Not used" 1 "Language 1 à 253" 0 "Unavailable value";
VAL_ 1380 Meter_FOTA_status 31 "invalid" 30 "Not used" 29 "Not used" 28 "Not used" 27 "Not used" 26 "Not used" 25 "Not used" 24 "Not used" 23 "Not used" 22 "Not used" 21 "Slave Installation complete" 20 "Slave Copying in progress" 19 "Slave Installation in progress" 18 "Slave Distribution complete" 17 "Slave Integrity check in progress" 16 "Slave Distribution in progress" 15 "Ready for Slave Distribution" 14 "Rollback complete" 13 "Rollback in progress" 12 "Update Error detected" 11 "Error detected" 10 "Cancel in progress" 9 "Activation complete" 8 "Configuration install in progress" 7 "Component version check in progress" 6 "Reboot in progress" 5 "Switch in progress" 4 "Ready for activation" 3 "Vehicle Condition check in progress" 2 "Copying in progress" 1 "Installation in progress" 0 "Idle";
VAL_ 1381 BSWrad_ActivationState 1 "Deactivated" 0 "Activated";
VAL_ 1381 CTA_AlertStatus 3 "Right and Left alert" 2 "Left alert" 1 "Right alert" 0 "No alert";
VAL_ 1381 CTA_CollisionRiskAlert 1 "High collision risk" 0 "Low collision risk";
VAL_ 1381 CTA_StatusDisplay_v2 7 "Not Used" 6 "Not Used" 5 "Not Used" 4 "Permanent failure" 3 "Temporary failure" 2 "Operational" 1 "Not operational" 0 "No display";
VAL_ 1384 MexModeState_v3 15 "MEX MODE 15" 14 "MEX MODE 14" 13 "MEX MODE NORMAL" 12 "MEX MODE RACE" 11 "MEX MODE CITY" 10 "MEX MODE VITAMIN" 9 "MEX MODE ALLROADS" 8 "MEX MODE OFFROAD" 7 "MEX MODE SNOW" 6 "MEX MODE ECOPLUS" 5 "Reserved" 4 "MEX MODE SPORT" 3 "MEX MODE MYSENSE" 2 "MEX MODE COMFORT" 1 "MEX MODE ECO" 0 "Unavailable";
VAL_ 1384 MexAutoState 1 "Auto-adaptive function active" 0 "Auto-adaptive function not active";
VAL_ 1384 ADBSettingRequest 7 "Reset Request" 6 "Mode 6" 5 "Mode 5" 4 "Mode 4" 3 "Mode 3" 2 "Mode 2 (Sport)" 1 "Mode 1 (Normal)" 0 "No request";
VAL_ 1384 CurrentSpecificUserState 3 "Not used" 2 "Beginner mode" 1 "Valet mode" 0 "No specific mode";
VAL_ 1384 VDCSettingRequest 15 "Reset Request" 14 "Mode 14" 13 "Mode 13" 12 "Mode 12" 11 "Mode 11" 10 "Mode 10" 9 "Mode 9" 8 "Mode 8" 7 "Mode 7" 6 "Mode 6" 5 "Mode 5" 4 "Mode 4" 3 "Mode 3" 2 "Mode 2" 1 "Mode 1" 0 "No request";
VAL_ 1392 HUD_ADASactivationRequest2 3 "Reset request" 2 "De-activation request" 1 "Activation request" 0 "No request";
VAL_ 1392 VSPsoundChoiceActivationRequest2 7 "Not used" 6 "Reset" 5 "VSP Choice 5" 4 "VSP Choice 4" 3 "VSP Choice 3" 2 "VSP Choice 2" 1 "VSP Choice 1" 0 "No VSP Choice request";
VAL_ 1392 FAPK_DefaultManeuverTypeRequest2 7 "Not Used" 6 "Not Used" 5 "reset request" 4 "mode auto" 3 "park in / angled" 2 "park in / perpendicular" 1 "park in / parallel" 0 "no request";
VAL_ 1392 AmbientLightingColor_v3 127 "Reset Request" 126 "Color 126" 125 "Color 125" 124 "Color 124" 123 "Color 123" 122 "Color 122" 121 "Color 121" 120 "Color 120" 119 "Color 119" 118 "Color 118" 117 "Color 117" 116 "Color 116" 115 "Color 115" 114 "Color 114" 113 "Color 113" 112 "Color 112" 111 "Color 111" 110 "Color 110" 109 "Color 109" 108 "Color 108" 107 "Color 107" 106 "Color 106" 105 "Color 105" 104 "Color 104" 103 "Color 103" 102 "Color 102" 101 "Color 101" 100 "Color 100" 99 "Color 99" 98 "Color 98" 97 "Color 97" 96 "Color 96" 95 "Color 95" 94 "Color 94" 93 "Color 93" 92 "Color 92" 91 "Color 91" 90 "Color 90" 89 "Color 89" 88 "Color 88" 87 "Color 87" 86 "Color 86" 85 "Color 85" 84 "Color 84" 83 "Color 83" 82 "Color 82" 81 "Color 81" 80 "Color 80" 79 "Color 79" 78 "Color 78" 77 "Color 77" 76 "Color 76" 75 "Color 75" 74 "Color 74" 73 "Color 73" 72 "Color 72" 71 "Color 71" 70 "Color 70" 69 "Color 69" 68 "Color 68" 67 "Color 67" 66 "Color 66" 65 "Color 65" 64 "Color 64" 63 "Color 63" 62 "Color 62" 61 "Color 61" 60 "Color 60" 59 "Color 59" 58 "Color 58" 57 "Color 57" 56 "Color 56" 55 "Color 55" 54 "Color 54" 53 "Color 53" 52 "Color 52" 51 "Color 51" 50 "Color 50" 49 "Color 49" 48 "Color 48" 47 "Color 47" 46 "Color 46" 45 "Color 45" 44 "Color 44" 43 "Color 43" 42 "Color 42" 41 "Color 41" 40 "Color 40" 39 "Color 39" 38 "Color 38" 37 "Color 37" 36 "Color 36" 35 "Color 35" 34 "Color 34" 33 "Color 33" 32 "Color 32" 31 "Color 31" 30 "Color 30" 29 "Color 29" 28 "Color 28" 27 "Color 27" 26 "Color 26" 25 "Color 25" 24 "Color 24" 23 "Color 23" 22 "Color 22" 21 "Color 21" 20 "Color 20" 19 "Color 19" 18 "Color 18" 17 "Color 17" 16 "Color 16" 15 "Color 15" 14 "Color 14" 13 "Color 13" 12 "Color 12" 11 "Color 11" 10 "Color 10" 9 "Color 9" 8 "Color 8" 7 "Color 7" 6 "Color 6" 5 "Color 5" 4 "Color 4" 3 "Color 3" 2 "Color 2" 1 "Color 1" 0 "No request";
VAL_ 1392 FOTA_ReadyToSleep_IVI 1 "Ready to sleep" 0 "Refuse to sleep due to FOTA";
VAL_ 1392 VSPSoundActivationRequest2 3 "Reset request" 2 "VSP no activated" 1 "VSP activated" 0 "No VSP request";
VAL_ 1392 HUD_TurnByTurnActivationRequest2 3 "Reset request" 2 "De-activation request" 1 "Activation request" 0 "No request";
VAL_ 1392 HUD_TSRactivationRequest2 3 "Reset request" 2 "De-activation request" 1 "Activation request" 0 "No request";
VAL_ 1392 SET_Acceleration_Request2 7 "Not used" 6 "Not used" 5 "Not used" 4 "Reset request" 3 "Gentle" 2 "Standard" 1 "Quick" 0 "No request";
VAL_ 1392 SET_NavigatDriveAssist_Request2 3 "Reset request" 2 "ON" 1 "OFF" 0 "No request";
VAL_ 1392 SET_ALCActivationByTSIG_Request2 3 "Reset request" 2 "ON" 1 "OFF" 0 "No request";
VAL_ 1392 SET_Deceleration_Request2 7 "Not used" 6 "Not used" 5 "Not used" 4 "Reset request" 3 "Gentle" 2 "Standard" 1 "Quick" 0 "No request";
VAL_ 1392 SET_OvertakingAssist_Request2 3 "Reset request" 2 "ON" 1 "OFF" 0 "No request";
VAL_ 1392 SET_LaneChangeSwiftness_Request2 7 "Not used" 6 "Not used" 5 "Not used" 4 "Reset request" 3 "Comfort" 2 "Standard" 1 "Swift" 0 "No request";
VAL_ 1392 SET_CornerSpeedLevel_Request2 7 "Not used" 6 "Not used" 5 "Not used" 4 "Reset request" 3 "Gentle" 2 "Standard" 1 "Quick" 0 "No request";
VAL_ 1392 SET_VoiceGuidance_Request2 3 "Reset request" 2 "ON" 1 "OFF" 0 "No request";
VAL_ 1392 SET_PositionInLane_Request2 7 "Not Used" 6 "Not Used" 5 "Not Used" 4 "Reset request" 3 "To_overtake_lane" 2 "Centre" 1 "To_hard_shoulder" 0 "No request";
VAL_ 1392 SET_OvertakeRelatSpeed_Request2 7 "Not used" 6 "Not used" 5 "Not used" 4 "Reset request" 3 "High" 2 "Middle" 1 "Low" 0 "No request";
VAL_ 1392 IVI_SafeModeAck 1 "Activated" 0 "Not activated";
VAL_ 1392 WDA_ActivationRequest2 3 "Reset request" 2 "Deactivation request" 1 "Activation request" 0 "No request";
VAL_ 1392 RAB_ActivationRequest2 3 "Reset Request" 2 "Deactivation request" 1 "Activation request" 0 "No request";
VAL_ 1392 RST_PedalMappingRequest 7 "Unavailable" 6 "Not used" 5 "Not used" 4 "Pedal mapping 4 requested" 3 "Pedal mapping 3 requested" 2 "Pedal mapping 2 requested" 1 "Pedal mapping 1 requested" 0 "No request";
VAL_ 1392 VirtualKeySuspendReq2 3 "VK Factory Reset (Switch to Default VK State)" 2 "VK Resume" 1 "VK Suspend" 0 "No Request";
VAL_ 1392 SET_MAPAutoUpdate_Request2 3 "Reset request" 2 "ON" 1 "OFF" 0 "No request";
VAL_ 1392 SET_FocusState_Request2 3 "Reset request" 2 "ON" 1 "OFF" 0 "No request";
VAL_ 1392 SET_ADL3_Request2 3 "Reset request" 2 "ON" 1 "OFF" 0 "No request";
VAL_ 1394 E_Hor_MedRange_CartoData 0 "Table Value16393";
VAL_ 1394 E_Hor_MedRange_DataType 7 "Reserved" 6 "Meta-Data" 5 "Profile Long" 4 "Profile Short" 3 "Stub" 2 "Segment" 1 "Position" 0 "System Specific";
VAL_ 1398 ChargingStationComType 7 "Unavailable" 6 "Not Used" 5 "DC GB/T" 4 "DC CHAdeMO" 3 "DC Combo HLC ISO15118" 2 "DC Combo basic" 1 "AC HLC ISO15118" 0 "AC Basic";
VAL_ 1398 V2G_ServiceActivationState 7 "Not used" 6 "Not used" 5 "Not used" 4 "Charge Service deactivated due to durability inhibition" 3 "Charge Service deactivated due to certificate error" 2 "Charge Service deactivated due to an error" 1 "Charge Service activated" 0 "Charge Service Not Activated";
VAL_ 1402 BCI_StatusDisplay 3 "Not used" 2 "Operational" 1 "Not operational" 0 "No display";
VAL_ 1402 LDW_SoundType 15 "Not used" 14 "Not used" 13 "Not used" 12 "Not used" 11 "Not used" 10 "Not used" 9 "Not used" 8 "Not used" 7 "Not used" 6 "Not used" 5 "Not used" 4 "Not used" 3 "LDW sound 3" 2 "LDW sound 2 (BSW)" 1 "LDW Sound 1 (LDW)" 0 "No sound";
VAL_ 1402 LDW_SensibilityState 3 "High sensibility" 2 "Middle sensibility" 1 "Low sensibility" 0 "Unavailable";
VAL_ 1402 LDW_ActivationState_v3 3 "Not used" 2 "Deactivated" 1 "Activated" 0 "Unavailable";
VAL_ 1402 LDW_SoundAlert 3 "Not Used" 2 "Lane departure to left side detected" 1 "Lane departure to right side detected" 0 "No lane departure detected";
VAL_ 1410 MemoPositionDisplayRequest 3 "Display3" 2 "Display2" 1 "Display1" 0 "No display";
VAL_ 1410 MemoParkExecutionState 3 "Execution state3" 2 "Execution state2" 1 "Execution state1" 0 "No display";
VAL_ 1412 HVAC_ClimShortcutPush 1 "Switch pushed" 0 "Switch not pushed";
VAL_ 1415 FAPK_SelectedManeuverTypeRequest 7 "Not Used" 6 "Not Used" 5 "mode auto" 4 "park out" 3 "park in / angled" 2 "park in / perpendicular" 1 "park in / parallel" 0 "no request";
VAL_ 1422 DriverBackBolsterDisplayReq 3 "Not monitored" 2 "Backrest bolster decrease Display Request" 1 "Backrest bolster increase Display Request" 0 "No display request";
VAL_ 1422 MC_MovementDisplayRequest 1 "Display requested" 0 "No display requested";
VAL_ 1422 MC_ActivationState 1 "Magic Cockpit ON" 0 "Magic Cockpit OFF";
VAL_ 1422 MC_PositionChangeStatus 15 "Position Change On Going" 14 "MC position 14" 13 "MC position 13" 12 "MC position 12" 11 "MC position 11" 10 "MC position 10" 9 "MC position 9" 8 "MC position 8" 7 "MC position 7" 6 "MC position 6" 5 "MC position 5" 4 "MC position 4" 3 "MC position 3" 2 "MC position 2" 1 "MC position 1" 0 "Unavailable";
VAL_ 1422 MCM_PositionSaveRequest 15 "Unavailable" 14 "Save MC position 14" 13 "Save MC position 13" 12 "Save MC position 12" 11 "Save MC position 11" 10 "Save MC position 10" 9 "Save MC position 9" 8 "Save MC position 8" 7 "Save MC position 7" 6 "Save MC position 6" 5 "Save MC position 5" 4 "Save MC position 4" 3 "Save MC position 3" 2 "Save MC position 2" 1 "Save MC position 1" 0 "No request";
VAL_ 1422 MCM_PositionRecallRequest 15 "Reset Request" 14 "Recall MC position 14" 13 "Recall MC position 13" 12 "Recall MC position 12" 11 "Recall MC position 11" 10 "Recall MC position 10" 9 "Recall MC position 9" 8 "Recall MC position 8" 7 "Recall MC position 7" 6 "Recall MC position 6" 5 "Recall MC position 5" 4 "Recall MC position 4" 3 "Recall MC position 3" 2 "Recall MC position 2" 1 "Recall MC position 1" 0 "No request";
VAL_ 1422 DrLumbarDisplayRequest_Z_Axis 3 "Not monitored" 2 "Z Axis Downward" 1 "Z Axis Upward" 0 "No display request";
VAL_ 1422 MC_TutorialState 1 "Done" 0 "Not Done";
VAL_ 1422 AD_MessageDisplayReq 3 "Not used" 2 "Stop backrest mvt position will not be drivable" 1 "Stop sliding mvt position will not be drivable" 0 "No Display Request";
VAL_ 1422 DriverCushionBolsterDisplayReq 3 "Not monitored" 2 "Cushion bolster decrease Display Request" 1 "Cushion bolster increase Display Request" 0 "No display request";
VAL_ 1422 DrLumbarDisplayRequest_X_Axis 3 "Not monitored" 2 "X Axis Backward" 1 "X Axis Frontward" 0 "No display request";
VAL_ 1436 HFP_ManeuverChoiceDisplayRequest 1 "Maneuver choice possible" 0 "Maneuver choice not possible";
VAL_ 1436 HFP_SelectedManeuverType 7 "Not used" 6 "Not used" 5 "Not used" 4 "park out" 3 "park in / angled" 2 "park in / perpendicular" 1 "park in / parallel" 0 "unavailable";
VAL_ 1436 HFP_DefaultManeuverType 7 "Not used" 6 "Not used" 5 "Not used" 4 "park out" 3 "park in / angled" 2 "park in / perpendicular" 1 "park in / parallel" 0 "unavailable";
VAL_ 1436 DetectedSlotLeft_Selection 1 "Slot left selected by user" 0 "Slot left not selected by user";
VAL_ 1436 HFP_ManeuverMove 3 "Forward move" 2 "Backward move" 1 "First move" 0 "Unavailable";
VAL_ 1436 HFP_SoundRequest 3 "unavailable" 2 "level 2 sound" 1 "level 1 sound" 0 "no sound";
VAL_ 1436 HFP_MapContentDisplay 7 "unavailable" 6 "Not used" 5 "Not used" 4 "Not used" 3 "guidance Display" 2 "parkOutConfirmation Display" 1 "scanning Display" 0 "Empty Display";
VAL_ 1436 HFP_ExtendedInstrContentDisplay 31 "Unavailable" 30 "Instruction 31" 29 "Instruction 30" 28 "Instruction 29" 27 "Instruction 28" 26 "Instruction 27" 25 "Instruction 26" 24 "Instruction 25" 23 "Instruction 24" 22 "Instruction 23" 21 "Instruction 22" 20 "Instruction 21" 19 "instruction 20" 18 "Instruction 19" 17 "Instruction 18" 16 "Instruction 17" 15 "Instruction 16" 14 "Instruction 15" 13 "instruction 14" 12 "instruction 13" 11 "instruction 12" 10 "instruction 11" 9 "instruction 10" 8 "instruction 9" 7 "instruction 8" 6 "instruction 7" 5 "instruction 6" 4 "instruction 5" 3 "instruction 4" 2 "instruction 3" 1 "instruction 2" 0 "instruction 1";
VAL_ 1436 DetectedSlotRight_Suitable 1 "Slot right available for parking" 0 "Slot right unavailable for parking";
VAL_ 1436 DetectedSlotRight_Selection 1 "Slot right selected by user" 0 "Slot right not selected by user";
VAL_ 1436 DetectedSlotLeft_Suitable 1 "Slot left available for parking" 0 "Slot left unavailable for parking";
VAL_ 1436 ScanningSide 3 "unavailable" 2 "right" 1 "left" 0 "no scanning side";
VAL_ 1444 HUD_EffectiveDeployment 1 "HUD deployed" 0 "HUD not deployed";
VAL_ 1444 HUD_TSRactivationState 3 "Not used" 2 "De-activated" 1 "Activated" 0 "Unavailable";
VAL_ 1444 HUD_PositionState 31 "Not used" 30 "Not used" 29 "Not used" 28 "Not used" 27 "Not used" 26 "Not used" 25 "Not used" 24 "Not used" 23 "Not used" 22 "Not used" 21 "Not used" 20 "Step 21" 19 "Step 20" 18 "Step 19" 17 "Step 18" 16 "Step 17" 15 "Step 16" 14 "Step 15" 13 "Step 14" 12 "Step 13" 11 "Step 12" 10 "Step 11" 9 "Step 10" 8 "Step 9" 7 "Step 8" 6 "Step 7" 5 "Step 6" 4 "Step 5" 3 "Step 4" 2 "Step 3" 1 "Step 2" 0 "Step 1";
VAL_ 1444 HUD_ActivationState 3 "Not used" 2 "HUD de-activated" 1 "HUD activated" 0 "Unavailable";
VAL_ 1444 HUD_ADASactivationState 3 "Not used" 2 "De-activated" 1 "Activated" 0 "Unavailable";
VAL_ 1444 HUD_TurnByTurnActivationState 3 "Not used" 2 "De-activated" 1 "Activated" 0 "Unavailable";
VAL_ 1444 HUD_DayLuminosityState 31 "Not used" 30 "Not used" 29 "Not used" 28 "Not used" 27 "Not used" 26 "Not used" 25 "Not used" 24 "Not used" 23 "Not used" 22 "Not used" 21 "Not used" 20 "Step 21" 19 "Step 20" 18 "Step 19" 17 "Step 18" 16 "Step 17" 15 "Step 16" 14 "Step 15" 13 "Step 14" 12 "Step 13" 11 "Step 12" 10 "Step 11" 9 "Step 10" 8 "Step 9" 7 "Step 8" 6 "Step 7" 5 "Step 6" 4 "Step 5" 3 "Step 4" 2 "Step 3" 1 "Step 2" 0 "Step 1";
VAL_ 1444 HUD_AutoDimmingState 1 "Deactivated" 0 "Activated";
VAL_ 1444 HUD_NightLuminosityState 31 "Not used" 30 "Not used" 29 "Not used" 28 "Not used" 27 "Not used" 26 "Not used" 25 "Not used" 24 "Not used" 23 "Not used" 22 "Not used" 21 "Not used" 20 "Step 21" 19 "Step 20" 18 "Step 19" 17 "Step 18" 16 "Step 17" 15 "Step 16" 14 "Step 15" 13 "Step 14" 12 "Step 13" 11 "Step 12" 10 "Step 11" 9 "Step 10" 8 "Step 9" 7 "Step 8" 6 "Step 7" 5 "Step 6" 4 "Step 5" 3 "Step 4" 2 "Step 3" 1 "Step 2" 0 "Step 1";
VAL_ 1446 StorageFormatStatus 3 "Format cancelled" 2 "Format completed" 1 "Format in progress" 0 "No format requested";
VAL_ 1447 SR_LocationInfoRecordState 1 "Record" 0 "No record";
VAL_ 1447 SR_CustomerRecordStatus 3 "Customer Record End" 2 "Customer Record Stopped" 1 "Customer Record In Progress" 0 "No request";
VAL_ 1447 SR_ShockSensitivityState 3 "Not used" 2 "High" 1 "Mid" 0 "Low";
VAL_ 1447 SR_SoundRecordState 1 "Sound recorded" 0 "Sound not recorded";
VAL_ 1447 SR_DrivingInfoRecordState 1 "Record" 0 "No Record";
VAL_ 1447 SR_CustomerRecordLengthState 3 "Not used" 2 "5 minutes" 1 "3 minutes" 0 "1 minute";
VAL_ 1449 ClimLinkPriorityHeatStrgAutoReq 7 "Reset request" 6 "OFF request" 5 "Level 5" 4 "Level 4" 3 "Level 3" 2 "Level 2" 1 "Level 1" 0 "No request";
VAL_ 1449 ClimFPrearLeftBlowingRequest 15 "Blower OFF" 14 "Level 14" 13 "Level 13" 12 "Level 12" 11 "Level 11" 10 "Level 10" 9 "Level 9" 8 "Level 8" 7 "Level 7" 6 "Level 6" 5 "Level 5" 4 "Level 4" 3 "Level 3" 2 "Level 2" 1 "Level 1" 0 "No Request";
VAL_ 1449 ClimFPrearRightBlowingRequest 15 "Blower OFF" 14 "Level 14" 13 "Level 13" 12 "Level 12" 11 "Level 11" 10 "Level 10" 9 "Level 9" 8 "Level 8" 7 "Level 7" 6 "Level 6" 5 "Level 5" 4 "Level 4" 3 "Level 3" 2 "Level 2" 1 "Level 1" 0 "No Request";
VAL_ 1449 VisionMexMode 15 "Unavailable" 14 "Not used" 13 "Mode14" 12 "Mode13" 11 "Mode12" 10 "Mode11" 9 "Mode10" 8 "Mode9" 7 "Mode8" 6 "Mode7" 5 "Mode6" 4 "Mode5" 3 "Mode4" 2 "Mode3" 1 "Mode2" 0 "Mode1";
VAL_ 1450 SR_SystemStatus 1 "System Failure" 0 "Normal";
VAL_ 1450 StorageStatusDisplay 3 "Memory failure" 2 "No memory card" 1 "Need memory format" 0 "No display";
VAL_ 1450 SR_ContinuousRecordLengthState 3 "Not used" 2 "5 minutes" 1 "3 minutes" 0 "1 minute";
VAL_ 1450 SR_AutomaticRecordStatus 3 "Not used" 2 "Automatic Record End" 1 "Automatic Record In Progress" 0 "No request";
VAL_ 1457 AmbientLightingArea3Status 1 "AmbientLighting Area 3 Activated" 0 "AmbientLighting Area 3 Desactivated";
VAL_ 1457 AmbientLightingArea2Status 1 "AmbientLighting Area 2 Activated" 0 "AmbientLighting Area 2 Desactivated";
VAL_ 1457 AmbientLightingActivationStatus 1 "Activation State" 0 "Deactivation State";
VAL_ 1457 AmbientLightingArea1Status 1 "AmbientLighting Area 1 Activated" 0 "AmbientLighting Area 1 Desactivated";
VAL_ 1457 AmbientLightDayIntensityStatus 31 "Unavailable";
VAL_ 1458 PnCHEVCactivationStatus 3 "Unavailable" 2 "Not Used" 1 "PnC function activated" 0 "No PnC function activated";
VAL_ 1459 MOD_ActivationState 1 "Deactivated" 0 "Activated";
VAL_ 1459 AVM_SoundType 1 "Error sound" 0 "Normal sound";
VAL_ 1459 AVM_SoundRequest 1 "Sound requested" 0 "Sound not requested";
VAL_ 1459 MOD_SoundAlertRequest_IVI 1 "Sound alert requested" 0 "Sound alert not requested";
VAL_ 1459 AVM_InitializationState 1 "Initialization on going" 0 "Initialization completed";
VAL_ 1459 AVM_DisplayRequest 1 "Requested" 0 "Not requested";
VAL_ 1459 AVM_LayoutVideoStatus 31 "Layout31" 30 "Layout30" 29 "Layout29" 28 "Layout28" 27 "Layout27" 26 "Layout26" 25 "Layout25" 24 "Layout24" 23 "Layout23" 22 "Layout22" 21 "Layout21" 20 "Layout20" 19 "Layout19" 18 "Layout18" 17 "Layout17" 16 "Layout16" 15 "Layout15" 14 "Layout14" 13 "Layout13" 12 "Layout12" 11 "Layout11" 10 "Layout10" 9 "Layout9" 8 "Layout8" 7 "Layout7" 6 "Layout6" 5 "Layout5" 4 "Layout4" 3 "Layout3" 2 "Layout2" 1 "Layout1" 0 "No display (unavailable)";
VAL_ 1459 AVM_ClosingAuthorization 1 "Authorized" 0 "Not authorized";
VAL_ 1459 AVM_LayoutDisplayRequest 31 "Layout 31" 30 "Layout 30" 29 "Layout 29" 28 "Layout 28" 27 "Layout 27" 26 "Layout 26" 25 "Layout 25" 24 "Layout 24" 23 "Layout 23" 22 "Layout 22" 21 "Layout 21" 20 "Layout 20" 19 "Layout 19" 18 "Layout 18" 17 "Layout 17" 16 "Layout 16" 15 "Layout 15" 14 "Layout 14" 13 "Layout 13" 12 "Layout 12" 11 "Layout 11" 10 "Layout 10" 9 "Layout 9" 8 "Layout 8" 7 "Layout 7" 6 "Layout 6" 5 "Layout 5" 4 "Layout 4" 3 "Layout 3" 2 "Layout 2" 1 "Layout 1" 0 "No message";
VAL_ 1462 ClimRearLeftTempDisplay 10 "Display Hi" 8 "Display Lo" 0 "No display";
VAL_ 1462 ClimFrontDefrostDisplayStatus 1 "Function available" 0 "Function not available";
VAL_ 1462 ClimHeatedSteerWheelDispStatus 1 "Function available" 0 "Function not available";
VAL_ 1462 ClimRearLeftTempDisplayStatus 1 "Function available" 0 "Function not available";
VAL_ 1462 ClimHeatedSteerWheelAutoDisplay 3 "Not Used" 2 "Heated steering wheel Auto OFF" 1 "Heated steering wheel Auto ON" 0 "No display";
VAL_ 1462 ClimFrontDefrostDisplay 3 "Not Used" 2 "Front defrost OFF" 1 "Front defrost ON" 0 "No display";
VAL_ 1462 ClimRearRightTempDisplay 10 "Display Hi" 8 "Display Lo" 0 "No display";
VAL_ 1462 ClimRearRightSyncDisplayStatus 1 "Function available" 0 "Function not available";
VAL_ 1462 ClimRearRightSyncDisplay 3 "Not used" 2 "Sync mode OFF" 1 "Sync mode ON" 0 "No display";
VAL_ 1462 ClimRearLeftSyncDisplayStatus 1 "Function available" 0 "Function not available";
VAL_ 1462 ClimRearLeftSyncDisplay 3 "Not used" 2 "Sync mode OFF" 1 "Sync mode ON" 0 "No display";
VAL_ 1462 ClimRearRightTempDisplayStatus 1 "Function available" 0 "Function not available";
VAL_ 1462 ClimRearRightFlowDistDispStatus 1 "Function available" 0 "Function not available";
VAL_ 1462 ClimRearRightFlowDistrDisplay 7 "Defrost + Vent + Feet" 6 "Defrost + Vent" 5 "Defrost + Feet" 4 "Defrost" 3 "Feet + Vent" 2 "Vent" 1 "Feet" 0 "No display";
VAL_ 1462 ClimRearLeftFlowDistrDispStatus 1 "Function available" 0 "Function not available";
VAL_ 1462 ClimRearLeftFlowDistrDisplay 7 "Defrost + Vent + Feet" 6 "Defrost + Vent" 5 "Defrost + Feet" 4 "Defrost" 3 "Feet + Vent" 2 "Vent" 1 "Feet" 0 "No display";
VAL_ 1462 ClimRearLeftBlowingAutoDisplay 3 "Not used" 2 "Blowing auto OFF" 1 "Blowing auto ON" 0 "No display";
VAL_ 1462 ClimRearRightBlowingAutoDisplay 3 "Not used" 2 "Blowing auto OFF" 1 "Blowing auto ON" 0 "No display";
VAL_ 1462 ClimRearRightBlowLevelDisplay 15 "Blower OFF" 14 "Level 14" 13 "Level 13" 12 "Level 12" 11 "Level 11" 10 "Level 10" 9 "Level 9" 8 "Level 8" 7 "Level 7" 6 "Level 6" 5 "Level 5" 4 "Level 4" 3 "Level 3" 2 "Level 2" 1 "Level 1" 0 "No display";
VAL_ 1462 ClimRearACDisplay 3 "Not used" 2 "AC OFF" 1 "AC ON" 0 "No display";
VAL_ 1462 ClimRearRightBlowLevlDispStatus 1 "Function available" 0 "Function not available";
VAL_ 1462 ClimRearLeftBlowLevelDispStatus 1 "Function available" 0 "Function not available";
VAL_ 1462 ClimRearLeftBlowLevelDisplay 15 "Blower OFF" 14 "Level 14" 13 "Level 13" 12 "Level 12" 11 "Level 11" 10 "Level 10" 9 "Level 9" 8 "Level 8" 7 "Level 7" 6 "Level 6" 5 "Level 5" 4 "Level 4" 3 "Level 3" 2 "Level 2" 1 "Level 1" 0 "No display";
VAL_ 1462 ClimLinkPrioritHeatStrgAutoDisp 7 "Not used" 6 "OFF" 5 "Level 5" 4 "Level 4" 3 "Level 3" 2 "Level 2" 1 "Level 1" 0 "No display";
VAL_ 1462 ClimRearRightAutoDisplay 3 "Not used" 2 "Auto OFF" 1 "Auto ON" 0 "No display";
VAL_ 1462 ClimRearLeftAutoDisplay 3 "Not used" 2 "Auto OFF" 1 "Auto ON" 0 "No display";
VAL_ 1462 ClimRearACDisplayStatus 1 "Function available" 0 "Function not available";
VAL_ 1464 DriverMassageActivationReq 3 "Reset request" 2 "Deactivation request " 1 "Activation request" 0 "No request";
VAL_ 1464 DriverSeatMemoRecallReq 7 "Reset Request" 6 "Recall of memorization 6" 5 "Recall of memorization 5" 4 "Recall of memorization 4" 3 "Recall of memorization 3" 2 "Recall of memorization 2" 1 "Recall of memorization 1" 0 "No recall";
VAL_ 1464 DriverSeatMemoRequest 7 "Reset Request" 6 "Request of memorization 6" 5 "Request of memorization 5" 4 "Request of memorization 4" 3 "Request of memorization 3" 2 "Request of memorization 2" 1 "Request of memorization 1" 0 "No request of memorization";
VAL_ 1464 DriverEasyAccessRequest2 3 "Reset Request" 2 "Easy access de-activation requested" 1 "Easy access activation requested" 0 "No request";
VAL_ 1464 DriverMassageIntensityReq 7 "Reset request" 6 "Not used" 5 "Intensity 5 requested" 4 "Intensity 4 requested" 3 "Intensity 3 requested" 2 "Intensity 2 requested" 1 "Intensity 1 requested" 0 "No request";
VAL_ 1464 DriverMassageProgramReq 7 "Reset request" 6 "Not used" 5 "Program 5 requested" 4 "Program 4 requested" 3 "Program 3 requested" 2 "Program 2 requested" 1 "Program 1 requested" 0 "No request";
VAL_ 1464 PassengerMassageActivationReq 3 "Reset request" 2 "Deactivation request " 1 "Activation request" 0 "No request";
VAL_ 1464 PassengerMassageProgramReq 7 "Reset Request" 6 "Not used" 5 "Request of program massage 5" 4 "Request of program massage 4" 3 "Request of program massage 3" 2 "Request of program massage 2" 1 "Request of program massage 1" 0 "No request";
VAL_ 1464 DriverMassageVelocityReq 7 "Reset request" 6 "Not Used" 5 "Velocity 5 requested" 4 "Velocity 4 requested" 3 "Velocity 3 requested" 2 "Velocity 2 requested" 1 "Velocity 1 requested" 0 "No request";
VAL_ 1464 PassengerEasyAccessRequest 3 "Reset Request" 2 "Easy access de-activation requested" 1 "Easy access activation requested" 0 "No request";
VAL_ 1464 PassengerMassageVelocityReq 7 "Reset Request" 6 "Not Used" 5 "Velocity 5 requested" 4 "Velocity 4 requested" 3 "Velocity 3 requested" 2 "Velocity 2 requested" 1 "Velocity 1 requested" 0 "No request";
VAL_ 1464 PassengerMassageIntensityReq 7 "Reset Request" 6 "Not used" 5 "Intensity 5 requested" 4 "Intensity 4 requested" 3 "Intensity 3 requested" 2 "Intensity 2 requested" 1 "Intensity 1 requested" 0 "No request";
VAL_ 1464 Sound3DActivationRequest 3 "Reset request" 2 "Spatialized requested" 1 "Front output requested" 0 "No request";
VAL_ 1464 AudioPilotActivationRequest 3 "Reset request" 2 "OFF requested" 1 "ON requested" 0 "No request";
VAL_ 1464 CourtesyActivationRequest2 3 "Reset Request" 2 "Courtesy Deactivation Request" 1 "Courtesy Activation Request" 0 "No request";
VAL_ 1465 PreSoakHVACfunctionsRequest 3 "Not used" 2 "Cabin air conditioning/heating ON request" 1 "Cabin air conditioning/heating OFF request" 0 "Not used";
VAL_ 1465 PreSoakFRseatRequest 7 "Not used" 6 "Not used" 5 "Not used" 4 "Ventilated ON request" 3 "Ventilated OFF request" 2 "Heater ON request" 1 "Heater OFF request" 0 "Not used";
VAL_ 1465 PreSoakFLseatRequest 7 "Not used" 6 "Not used" 5 "Not used" 4 "Ventilated ON request" 3 "Ventilated OFF request" 2 "Heater ON request" 1 "Heater OFF request" 0 "Not used";
VAL_ 1465 PreSoakSecondRLseatRequest 7 "Not used" 6 "Not used" 5 "Not used" 4 "Ventilated ON request" 3 "Ventilated OFF request" 2 "Heater ON request" 1 "Heater OFF request" 0 "Not used";
VAL_ 1465 PreSoakSecondRRseatRequest 7 "Not used" 6 "Not used" 5 "Not used" 4 "Ventilated ON request" 3 "Ventilated OFF request" 2 "Heater ON request" 1 "Heater OFF request" 0 "Not used";
VAL_ 1465 PreSoak_eACmodeRequest 3 "Not used" 2 "Quick request" 1 "Normal request" 0 "Not used";
VAL_ 1465 PreSoakThirdRLseatRequest 7 "Not used" 6 "Not used" 5 "Not used" 4 "Ventilated ON request" 3 "Ventilated OFF request" 2 "Heater ON request" 1 "Heater OFF request" 0 "Not used";
VAL_ 1465 PreSoakBatteryHeatingRequest 3 "Not used" 2 "Battery heating ON request" 1 "Battery heating OFF request" 0 "Not used";
VAL_ 1465 PreSoakSecondRCseatRequest 7 "Not used" 6 "Not used" 5 "Not used" 4 "Ventilated ON request" 3 "Ventilated OFF request" 2 "Heater ON request" 1 "Heater OFF request" 0 "Not used";
VAL_ 1465 LivingLightModeRequest 1 "Activated" 0 "Not activated";
VAL_ 1465 PreSoakAirPurifierRequest 3 "Not used" 2 "Air purifier ON request" 1 "Air purifier OFF request" 0 "Not used";
VAL_ 1465 PreSoakFrontDefrostRequest 3 "Not used" 2 "Front defrost ON request" 1 "Front defrost OFF request" 0 "Not used";
VAL_ 1465 PreSoakThirdRRseatRequest 7 "Not used" 6 "Not used" 5 "Not used" 4 "Ventilated ON request" 3 "Ventilated OFF request" 2 "Heater ON request" 1 "Heater OFF request" 0 "Not used";
VAL_ 1465 SecondRowCentralSeatRequest 15 "Not Used" 14 "Not Used" 13 "Not Used" 12 "Not Used" 11 "Not Used" 10 "Not Used" 9 "Not Used" 8 "Reset request" 7 "Ventilated High request" 6 "Ventilated Middle request" 5 "Ventilated Low request" 4 "Heater High request" 3 "Heater Middle request" 2 "Heater Low request" 1 "OFF request" 0 "No request";
VAL_ 1465 PreSoakRearDefrostRequest 3 "Not used" 2 "Rear defrost ON request" 1 "Rear defrost OFF request" 0 "Not used";
VAL_ 1465 PreSoakHeatedStrgWheelRequest 3 "Not used" 2 "Heated steering wheel ON request" 1 "Heated steering wheel OFF request" 0 "Not used";
VAL_ 1465 FrontRightSeatRequest 15 "Not Used" 14 "Not Used" 13 "Not Used" 12 "Not Used" 11 "Not Used" 10 "Not Used" 9 "Not Used" 8 "Reset request" 7 "Ventilated High request" 6 "Ventilated Middle request" 5 "Ventilated Low request" 4 "Heater High request" 3 "Heater Middle request" 2 "Heater Low request" 1 "OFF request" 0 "No request";
VAL_ 1465 FrontLeftSeatRequest 15 "Not Used" 14 "Not Used" 13 "Not Used" 12 "Not Used" 11 "Not Used" 10 "Not Used" 9 "Not Used" 8 "Reset request" 7 "Ventilated High request" 6 "Ventilated Middle request" 5 "Ventilated Low request" 4 "Heater High request" 3 "Heater Middle request" 2 "Heater Low request" 1 "OFF request" 0 "No request";
VAL_ 1466 EcoAdviceTirePressureRR 1 "Advice" 0 "No Advice";
VAL_ 1466 EcoAdviceTirePressureRL 1 "Advice" 0 "No Advice";
VAL_ 1466 EcoAdviceTirePressureFR 1 "Advice" 0 "No Advice";
VAL_ 1466 EcoAdviceTirePressureFL 1 "Advice" 0 "No Advice";
VAL_ 1468 DriverMassageVelocityState 7 "Not Used" 6 "Not Used" 5 "velocity 5" 4 "velocity 4" 3 "velocity 3" 2 "velocity 2" 1 "velocity 1" 0 "No velocity";
VAL_ 1468 DriverMassageProgramState 3 "Program 3 running" 2 "Program 2 running" 1 "Program 1 running" 0 "Massage not Running";
VAL_ 1468 DriverMassageIntensityState 7 "Not Used" 6 "Not Used" 5 "Intensity 5" 4 "Intensity 4" 3 "Intensity 3" 2 "Intensity 2" 1 "Intensity 1" 0 "No intensity";
VAL_ 1468 DriverSeatMemoStatus 7 "Not used" 6 "No Memorized Position" 5 "Seat Position 6" 4 "Seat Position 5" 3 "Seat Position 4" 2 "Seat Position 3" 1 "Seat Position 2" 0 "Seat Position 1";
VAL_ 1468 DriverReclinerDisplayRequest 3 "Not monitored" 2 "Recliner Moving Backward Display Request" 1 "Recliner Moving Forward Display Request" 0 "No Display Request";
VAL_ 1468 DriverFrontHeightDisplayRequest 3 "Not monitored" 2 "Descent Display Request" 1 "Raise Display Request" 0 "No Display Request";
VAL_ 1468 SeatSettingsDisplayRequest 1 "Seat Settings Display Request" 0 "No Display Request";
VAL_ 1468 DriverEasyAccessState 3 "Not used" 2 "Easy access not activated" 1 "Easy access activated" 0 "Unavailable";
VAL_ 1468 DriverBackHeightDisplayRequest 3 "Not monitored" 2 "Descent Display Request" 1 "Raise Display Request" 0 "No Display Request";
VAL_ 1468 DriverMassageActivationState 1 "Massage ON" 0 "Massage OFF";
VAL_ 1468 DriverSlidingDisplayRequest 3 "Not monitored" 2 "Sliding Backward Display Request" 1 "Sliding Forward Display Request" 0 "No Display Request";
VAL_ 1468 CourtesyActivationStatus 1 "Courtesy Activated" 0 "Courtesy NOT activated";
VAL_ 1469 AmbientLightingArea2Req 3 "Reset Request" 2 "AmbientLighting Area 2 not requested" 1 "AmbientLighting Area 2 requested" 0 "No Request";
VAL_ 1469 AmbientLightingArea1Req 3 "Reset Request" 2 "AmbientLighting Area 1 not requested" 1 "AmbientLighting Area 1 requested" 0 "No Request";
VAL_ 1469 AmbientLightingActivationReq 3 "Reset Request" 2 "AmbientLighting Desactivation request" 1 "AmbientLighting Activation request" 0 "No Request";
VAL_ 1469 AmbientLightingArea3Req 3 "Reset Request " 2 "AmbientLighting Area 3 not requested" 1 "AmbientLighting Area 3 requested" 0 "No Request";
VAL_ 1469 MeterVolumeRequest 7 "Reset request" 6 "Not used" 5 "Not used" 4 "Not used" 3 "Volume 3" 2 "Volume 2" 1 "Volume 1" 0 "No request";
VAL_ 1469 AmbientLightDayIntensityRequest 31 "Reset Request" 30 "No Request";
VAL_ 1469 AmbientLightNightIntensityReq 31 "Reset Request" 30 "No request";
VAL_ 1469 UnitDistanceDisplayRequest 3 "Reset request" 2 "display unit in mph request" 1 "display unit in km request" 0 "No request";
VAL_ 1469 CockpitLanguageRequest 255 "Reset request" 1 "Language 01h to FEh" 0 "No Language Request";
VAL_ 1469 IoniserAutoLaunchReq2 3 "Reset request" 2 "Deactivation request" 1 "Activation request" 0 "No request";
VAL_ 1469 HVchargeDisplayRequest 3 "Reset to factory parameter" 2 "Meter OFF during charge request" 1 "Meter ON during charge request" 0 "No request";
VAL_ 1469 ADB_ActivationRequest2 3 "Reset request" 2 "ADB not activated" 1 "ADB activated" 0 "No ADB request";
VAL_ 1469 AutoInternalLightingRequest2 3 "Reset request" 2 "internal lighting deactivation request" 1 "internal lighting activation request" 0 "No request";
VAL_ 1470 ITM_HumidSensorSensitivOperType 1 "Direct setting" 0 "UP & DOWN";
VAL_ 1470 ITM_AQSSensitivityOperationType 1 "Direct setting" 0 "UP & DOWN";
VAL_ 1470 ITM_LeftFlowDistrRequest 7 "Defrost + Vent + Feet" 6 "Defrost + Vent" 5 "Defrost + Feet" 4 "Defrost" 3 "Vent + Feet" 2 "Vent" 1 "Feet" 0 "No request";
VAL_ 1470 ITM_LeftFlowDistrOperationType 1 "Direct setting" 0 "Push by push";
VAL_ 1470 ITM_LeftBlowingLevelOperType 3 "Direct setting" 2 "Dial" 1 "UP & DOWN" 0 "Push by push";
VAL_ 1470 ITM_RearLeftBlowLevelOperType 3 "Direct setting" 2 "Dial" 1 "UP & DOWN" 0 "Push by push";
VAL_ 1470 ITM_LeftTempOperationType 3 "Not Used" 2 "Dial" 1 "Direct setting" 0 "UP & DOWN";
VAL_ 1470 ITM_RearLeftFlowDistrRequest 7 "Defrost + Vent + Feet" 6 "Defrost + Vent" 5 "Defrost + Feet" 4 "Defrost" 3 "Feet + Vent" 2 "Vent" 1 "Feet" 0 "No request";
VAL_ 1470 ITM_RearLeftFlowDistrOperType 1 "Direct setting" 0 "Push by push";
VAL_ 1470 ITM_RearRightBlowLevelOperType 3 "Direct setting" 2 "Dial" 1 "UP & DOWN" 0 "Push by push";
VAL_ 1470 ITM_RearLeftTempOperationType 3 "Not used" 2 "Dial" 1 "Direct setting" 0 "UP & DOWN";
VAL_ 1470 ITM_RearRightTempOperationType 3 "Not used" 2 "Dial" 1 "Direct setting" 0 "UP & DOWN";
VAL_ 1470 ITM_RearRightFlowDistrRequest 7 "Defrost + Vent + Feet" 6 "Defrost + Vent" 5 "Defrost + Feet" 4 "Defrost" 3 "Feet + Vent" 2 "Vent" 1 "Feet" 0 "No request";
VAL_ 1470 ITM_RearRightFlowDistrOperType 1 "Direct setting" 0 "Push by push";
VAL_ 1470 ITM_RightFlowDistrOperationType 1 "Direct setting" 0 "Push by push";
VAL_ 1470 ITM_RightBlowingLevelOperType 3 "Direct setting" 2 "Dial" 1 "UP & DOWN" 0 "Push by push";
VAL_ 1470 ITM_RightTempOperationType 3 "Not Used" 2 "Dial" 1 "Direct setting" 0 "UP & DOWN";
VAL_ 1470 ITM_RightFlowDistrRequest 7 "Defrost + Vent + Feet" 6 "Defrost + Vent" 5 "Defrost + Feet" 4 "Defrost" 3 "Feet + Vent" 2 "Vent" 1 "Feet" 0 "No request";
VAL_ 1471 PassengerBackHeightDisplayReq 3 "Not monitored" 2 "Descent Display Request" 1 "Raise Display Request" 0 "No Display Request";
VAL_ 1471 PassengerSlidingDisplayRequest 3 "Not monitored" 2 "Sliding Backward Display Request" 1 "Sliding Forward Display Request" 0 "No Display Request";
VAL_ 1471 PassengerEasyAccessState 3 "Not used" 2 "Easy access not activated" 1 "Easy access activated" 0 "Unavailable";
VAL_ 1471 PassengerMassageProgramState 3 "Program 3 running" 2 "Program 2 running" 1 "Program 1 running" 0 "Massage not Running";
VAL_ 1471 PassengerFrontHeightDisplayReq 3 "Not monitored" 2 "Descent Display Request" 1 "Raise Display Request" 0 "No Display Request";
VAL_ 1471 PassengerMassageIntensityState 7 "Not Used" 6 "Not Used" 5 "Intensity 5" 4 "Intensity 4" 3 "Intensity 3" 2 "Intensity 2" 1 "Intensity 1" 0 "No intensity";
VAL_ 1471 PassengerMassageVelocityState 7 "Not Used" 6 "Not Used" 5 "velocity 5" 4 "velocity 4" 3 "velocity 3" 2 "velocity 2" 1 "velocity 1" 0 "No velocity";
VAL_ 1471 PassengerMassageActivationState 1 "Massage ON" 0 "Massage OFF";
VAL_ 1471 PassengerSeatMMIRequest 1 "Multimedia Seat Settings Requested" 0 "Multimedia Seat Settings Not Requested";
VAL_ 1471 PassengerReclinerDisplayRequest 3 "Not monitored" 2 "Recliner Moving Backward Display Request" 1 "Recliner Moving Forward Display Request" 0 "No Display Request";
VAL_ 1472 MexModeState 7 "MEX MODE SNOW" 6 "MEX MODE RACE" 5 "MEX MODE PERSONNAL" 4 "MEX MODE DYNAMIC" 3 "MEX MODE NORMAL" 2 "MEX MODE COMFORT" 1 "MEX MODE ECO" 0 "Unavailable";
VAL_ 1472 MexModeState_xEV 7 "Not used" 6 "Not used" 5 "MEX MODE PERSONNAL" 4 "MEX MODE DYNAMIC" 3 "MEX MODE HYBRID" 2 "MEX MODE ZEN" 1 "MEX MODE ECO" 0 "Unavailable";
VAL_ 1474 ClimRightTempDisplay 10 "Display Hi" 8 "Display Lo" 0 "No display";
VAL_ 1474 ClimTempDisplay 10 "Display Hi" 8 "Display Lo" 0 "No display";
VAL_ 1474 ClimFlowDistrDisplay 15 "Feet + Aerator + Mild flow + Defrost " 14 "Aerator + Mild flow + Defrost " 13 "Feet + Mild flow + Defrost " 12 "Mild flow + Defrost " 11 "Feet + Aerator + Defrost " 10 "Aerator + Defrost " 9 "Feet + Defrost " 8 "Defrost " 7 "Feet + Aerator Mild flow " 6 "Mild flow + Aerator" 5 "Feet + Mild flow " 4 "Mild flow " 3 "Feet + Aerator " 2 "Aerator " 1 "Feet" 0 "No display";
VAL_ 1474 ClimOFFModeDisplay 1 "OFF Mode Activated Display" 0 "No Display";
VAL_ 1474 ClimModeTypeDisplay 7 "Not Used" 6 "Not Used" 5 "OFF" 4 "Manual Mode" 3 "Clearness Mode" 2 "Eco Mode" 1 "Auto Mode" 0 "No display";
VAL_ 1474 ClimBlowerLevelDisplay 15 "Blower Off" 14 "Level 14" 13 "Level 13" 12 "Level 12" 11 "Level 11" 10 "Level 10" 9 "Level 9" 8 "Level 8" 7 "Level 7" 6 "Level 6" 5 "Level 5" 4 "Level 4" 3 "Level 3" 2 "Level 2" 1 "Level 1" 0 "No display";
VAL_ 1474 ClimClearnessDisplay 3 "Not Used" 2 "Clearness OFF" 1 "Clearness ON" 0 "No display";
VAL_ 1474 ClimAutoModeDisplay 3 "Auto display" 2 "Fast display" 1 "Soft display" 0 "No display";
VAL_ 1474 ClimAutoDisplay 3 "Not used" 2 "Auto not activated" 1 "Auto activated" 0 "No display";
VAL_ 1474 ClimACDisplay 3 "Not used" 2 "AC OFF" 1 "AC ON" 0 "No display";
VAL_ 1474 ClimRearModeDisplay 3 "Rear panel OFF" 2 "Rear Panel locked " 1 "Rear Panel available" 0 "No display";
VAL_ 1474 ClimRearDefrostDisplay 3 "Not Used" 2 "Rear defrost OFF" 1 "Rear defrost ON" 0 "No display";
VAL_ 1475 LongitudeMode 1 "East" 0 "West";
VAL_ 1475 LattitudeMode 1 "South" 0 "North";
VAL_ 1475 LocationType 1 "Type 2 (other)" 0 "Type 1 (WGS84)";
